VERSION ""

NS_ :

BS_:

BU_: DSAU vHS_M SHVU_RR DPSS AMP ICC RLPSM APSM RWPC RRHV RRPSM CGW_CCU APSS ATS RLHV FPM RDC PSM ASAU

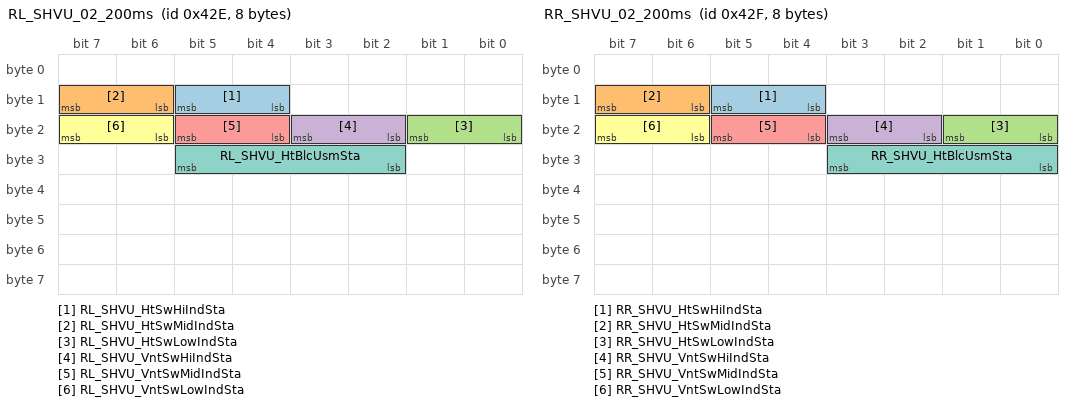
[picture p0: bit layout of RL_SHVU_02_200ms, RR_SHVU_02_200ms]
BO_ 1070 RL_SHVU_02_200ms: 8 SHVU_RR
 SG_ RL_SHVU_HtSwHiIndSta : 12|2@1+ (1,0) [0|0] ""  ATS,CGW_CCU
 SG_ RL_SHVU_HtSwMidIndSta : 14|2@1+ (1,0) [0|0] ""  ATS,CGW_CCU
 SG_ RL_SHVU_HtSwLowIndSta : 16|2@1+ (1,0) [0|0] ""  ATS,CGW_CCU
 SG_ RL_SHVU_VntSwHiIndSta : 18|2@1+ (1,0) [0|0] ""  ATS,CGW_CCU
 SG_ RL_SHVU_VntSwMidIndSta : 20|2@1+ (1,0) [0|0] ""  ATS,CGW_CCU
 SG_ RL_SHVU_VntSwLowIndSta : 22|2@1+ (1,0) [0|0] ""  ATS,CGW_CCU
 SG_ RL_SHVU_HtBlcUsmSta : 26|4@1+ (1,0) [0|0] ""  ATS,CGW_CCU

BO_ 1071 RR_SHVU_02_200ms: 8 SHVU_RR
 SG_ RR_SHVU_HtSwHiIndSta : 12|2@1+ (1,0) [0|0] ""  ATS,CGW_CCU
 SG_ RR_SHVU_HtSwMidIndSta : 14|2@1+ (1,0) [0|0] ""  ATS,CGW_CCU
 SG_ RR_SHVU_HtSwLowIndSta : 16|2@1+ (1,0) [0|0] ""  ATS,CGW_CCU
 SG_ RR_SHVU_VntSwHiIndSta : 18|2@1+ (1,0) [0|0] ""  ATS,CGW_CCU
 SG_ RR_SHVU_VntSwMidIndSta : 20|2@1+ (1,0) [0|0] ""  ATS,CGW_CCU
 SG_ RR_SHVU_VntSwLowIndSta : 22|2@1+ (1,0) [0|0] ""  ATS,CGW_CCU
 SG_ RR_SHVU_HtBlcUsmSta : 24|4@1+ (1,0) [0|0] ""  ATS,CGW_CCU

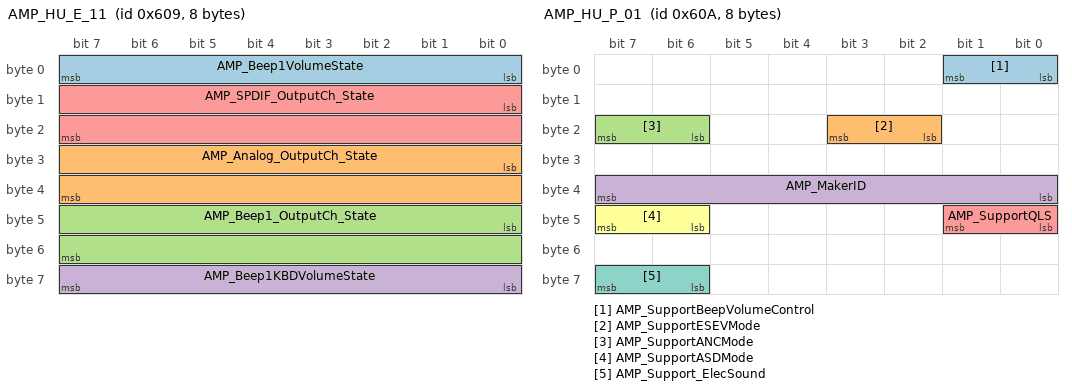
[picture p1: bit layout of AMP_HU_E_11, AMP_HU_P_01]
BO_ 1545 AMP_HU_E_11: 8 AMP
 SG_ AMP_Beep1VolumeState : 0|8@1+ (1,0) [0|0] ""  CGW_CCU
 SG_ AMP_Analog_OutputCh_State : 24|16@1+ (1,0) [0|0] ""  CGW_CCU
 SG_ AMP_Beep1_OutputCh_State : 40|16@1+ (1,0) [0|0] ""  CGW_CCU
 SG_ AMP_Beep1KBDVolumeState : 56|8@1+ (1,0) [0|0] ""  CGW_CCU
 SG_ AMP_SPDIF_OutputCh_State : 8|16@1+ (1,0) [0|0] ""  CGW_CCU

BO_ 1546 AMP_HU_P_01: 8 AMP
 SG_ AMP_SupportBeepVolumeControl : 0|2@1+ (1,0) [0|0] ""  ATS,CGW_CCU
 SG_ AMP_SupportESEVMode : 18|2@1+ (1,0) [0|0] ""  CGW_CCU
 SG_ AMP_SupportANCMode : 22|2@1+ (1,0) [0|0] ""  CGW_CCU
 SG_ AMP_MakerID : 32|8@1+ (1,0) [0|0] ""  CGW_CCU
 SG_ AMP_SupportQLS : 40|2@1+ (1,0) [0|0] ""  CGW_CCU
 SG_ AMP_SupportASDMode : 46|2@1+ (1,0) [0|0] ""  CGW_CCU
 SG_ AMP_Support_ElecSound : 62|2@1+ (1,0) [0|0] ""  CGW_CCU

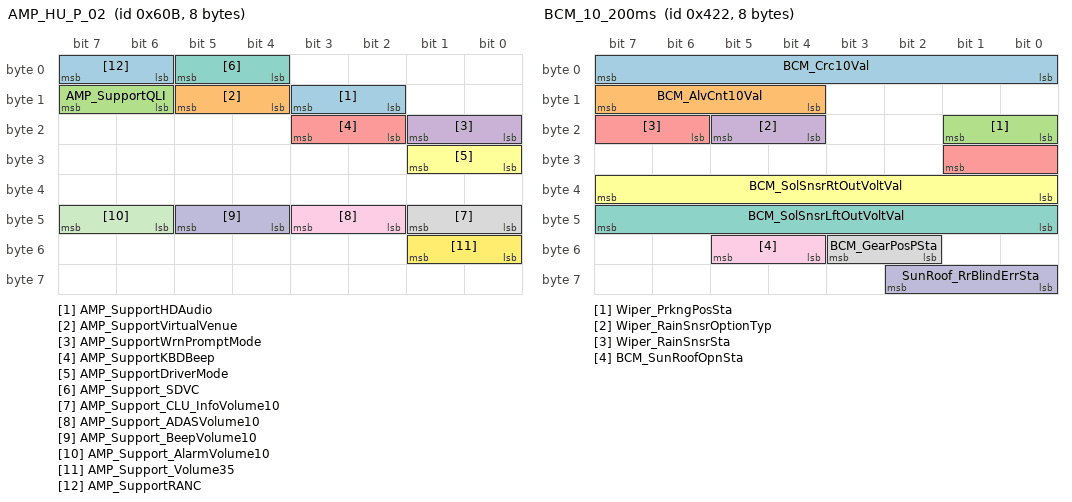
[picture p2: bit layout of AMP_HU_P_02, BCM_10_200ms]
BO_ 1547 AMP_HU_P_02: 8 AMP
 SG_ AMP_SupportHDAudio : 10|2@1+ (1,0) [0|0] ""  CGW_CCU
 SG_ AMP_SupportVirtualVenue : 12|2@1+ (1,0) [0|0] ""  CGW_CCU
 SG_ AMP_SupportQLI : 14|2@1+ (1,0) [0|0] ""  CGW_CCU
 SG_ AMP_SupportWrnPromptMode : 16|2@1+ (1,0) [0|0] ""  CGW_CCU
 SG_ AMP_SupportKBDBeep : 18|2@1+ (1,0) [0|0] ""  CGW_CCU
 SG_ AMP_SupportDriverMode : 24|2@1+ (1,0) [0|0] ""  CGW_CCU
 SG_ AMP_Support_SDVC : 4|2@1+ (1,0) [0|0] ""  CGW_CCU
 SG_ AMP_Support_CLU_InfoVolume10 : 40|2@1+ (1,0) [0|0] ""  CGW_CCU
 SG_ AMP_Support_ADASVolume10 : 42|2@1+ (1,0) [0|0] ""  CGW_CCU
 SG_ AMP_Support_BeepVolume10 : 44|2@1+ (1,0) [0|0] ""  CGW_CCU
 SG_ AMP_Support_AlarmVolume10 : 46|2@1+ (1,0) [0|0] ""  CGW_CCU
 SG_ AMP_Support_Volume35 : 48|2@1+ (1,0) [0|0] ""  CGW_CCU
 SG_ AMP_SupportRANC : 6|2@1+ (1,0) [0|0] ""  CGW_CCU

BO_ 1058 BCM_10_200ms: 8 CGW_CCU
 SG_ BCM_Crc10Val : 0|8@1+ (1,0) [0|0] ""  Vector__XXX
 SG_ BCM_AlvCnt10Val : 12|4@1+ (1,0) [0|0] ""  Vector__XXX
 SG_ Wiper_PrkngPosSta : 16|2@1+ (1,0) [0|0] ""  Vector__XXX
 SG_ Wiper_RainSnsrOptionTyp : 20|2@1+ (1,0) [0|0] ""  Vector__XXX
 SG_ Wiper_RainSnsrSta : 22|4@1+ (1,0) [0|0] ""  Vector__XXX
 SG_ BCM_SolSnsrRtOutVoltVal : 32|8@1+ (4.72441,0) [0|0] ""  Vector__XXX
 SG_ BCM_SolSnsrLftOutVoltVal : 40|8@1+ (4.72441,0) [0|0] ""  Vector__XXX
 SG_ BCM_GearPosPSta : 50|2@1+ (1,0) [0|0] ""  RLPSM,ATS
 SG_ BCM_SunRoofOpnSta : 52|2@1+ (1,0) [0|0] ""  AMP
 SG_ SunRoof_RrBlindErrSta : 56|3@1+ (1,0) [0|0] ""  Vector__XXX

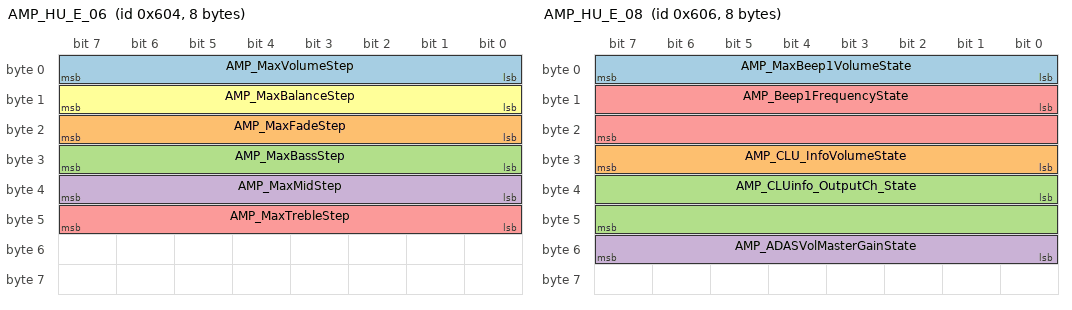
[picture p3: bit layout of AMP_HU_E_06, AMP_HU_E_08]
BO_ 1540 AMP_HU_E_06: 8 AMP
 SG_ AMP_MaxVolumeStep : 0|8@1+ (1,0) [0|0] ""  CGW_CCU
 SG_ AMP_MaxFadeStep : 16|8@1+ (1,0) [0|0] ""  CGW_CCU
 SG_ AMP_MaxBassStep : 24|8@1+ (1,0) [0|0] ""  CGW_CCU
 SG_ AMP_MaxMidStep : 32|8@1+ (1,0) [0|0] ""  CGW_CCU
 SG_ AMP_MaxTrebleStep : 40|8@1+ (1,0) [0|0] ""  CGW_CCU
 SG_ AMP_MaxBalanceStep : 8|8@1+ (1,0) [0|0] ""  CGW_CCU

BO_ 1542 AMP_HU_E_08: 8 AMP
 SG_ AMP_MaxBeep1VolumeState : 0|8@1+ (1,0) [0|0] ""  CGW_CCU
 SG_ AMP_CLU_InfoVolumeState : 24|8@1+ (1,0) [0|0] ""  CGW_CCU
 SG_ AMP_CLUinfo_OutputCh_State : 32|16@1+ (1,0) [0|0] ""  CGW_CCU
 SG_ AMP_ADASVolMasterGainState : 48|8@1+ (1,0) [0|0] ""  CGW_CCU
 SG_ AMP_Beep1FrequencyState : 8|16@1+ (1,0) [0|0] "Hz"  CGW_CCU

BO_ 1543 AMP_HU_E_09: 8 AMP
 SG_ AMP_WalkieTalkieVolumeState : 24|8@1+ (1,0) [0|0] ""  CGW_CCU
 SG_ AMP_WalkieTalkie_OutputCh_State : 8|16@1+ (1,0) [0|0] ""  CGW_CCU

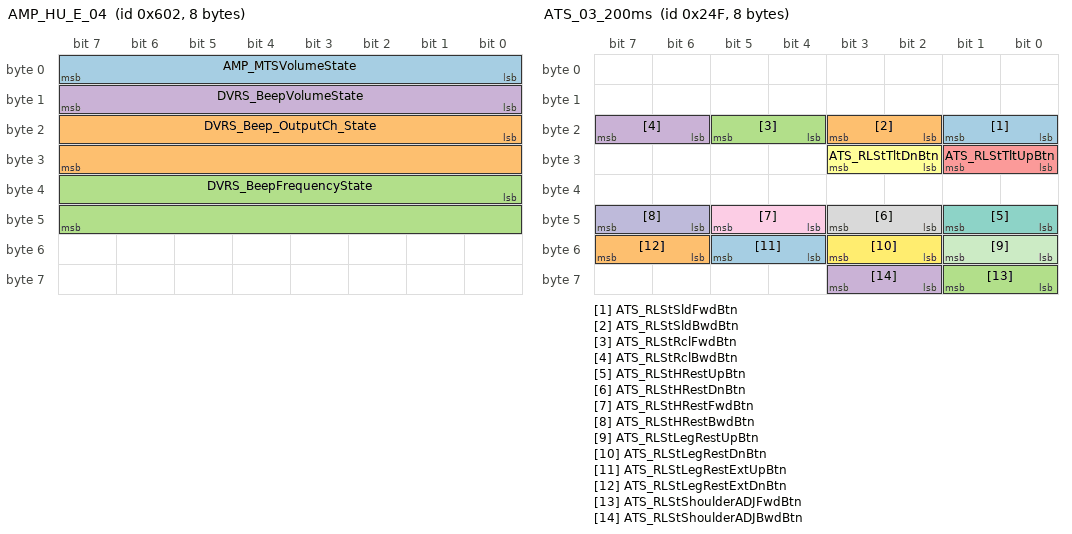
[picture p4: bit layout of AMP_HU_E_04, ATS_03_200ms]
BO_ 1538 AMP_HU_E_04: 8 AMP
 SG_ AMP_MTSVolumeState : 0|8@1+ (1,0) [0|0] ""  CGW_CCU
 SG_ DVRS_Beep_OutputCh_State : 16|16@1+ (1,0) [0|0] ""  CGW_CCU
 SG_ DVRS_BeepFrequencyState : 32|16@1+ (1,0) [0|0] "Hz"  CGW_CCU
 SG_ DVRS_BeepVolumeState : 8|8@1+ (1,0) [0|0] ""  CGW_CCU

BO_ 591 ATS_03_200ms: 8 ATS
 SG_ ATS_RLStSldFwdBtn : 16|2@1+ (1,0) [0|0] ""  RLPSM
 SG_ ATS_RLStSldBwdBtn : 18|2@1+ (1,0) [0|0] ""  RLPSM
 SG_ ATS_RLStRclFwdBtn : 20|2@1+ (1,0) [0|0] ""  RLPSM
 SG_ ATS_RLStRclBwdBtn : 22|2@1+ (1,0) [0|0] ""  RLPSM
 SG_ ATS_RLStTltUpBtn : 24|2@1+ (1,0) [0|0] ""  RLPSM
 SG_ ATS_RLStTltDnBtn : 26|2@1+ (1,0) [0|0] ""  RLPSM
 SG_ ATS_RLStHRestUpBtn : 40|2@1+ (1,0) [0|0] ""  RLPSM
 SG_ ATS_RLStHRestDnBtn : 42|2@1+ (1,0) [0|0] ""  RLPSM
 SG_ ATS_RLStHRestFwdBtn : 44|2@1+ (1,0) [0|0] ""  RLPSM
 SG_ ATS_RLStHRestBwdBtn : 46|2@1+ (1,0) [0|0] ""  RLPSM
 SG_ ATS_RLStLegRestUpBtn : 48|2@1+ (1,0) [0|0] ""  RLPSM
 SG_ ATS_RLStLegRestDnBtn : 50|2@1+ (1,0) [0|0] ""  RLPSM
 SG_ ATS_RLStLegRestExtUpBtn : 52|2@1+ (1,0) [0|0] ""  RLPSM
 SG_ ATS_RLStLegRestExtDnBtn : 54|2@1+ (1,0) [0|0] ""  RLPSM
 SG_ ATS_RLStShoulderADJFwdBtn : 56|2@1+ (1,0) [0|0] ""  RLPSM,RRPSM
 SG_ ATS_RLStShoulderADJBwdBtn : 58|2@1+ (1,0) [0|0] ""  RLPSM,RRPSM

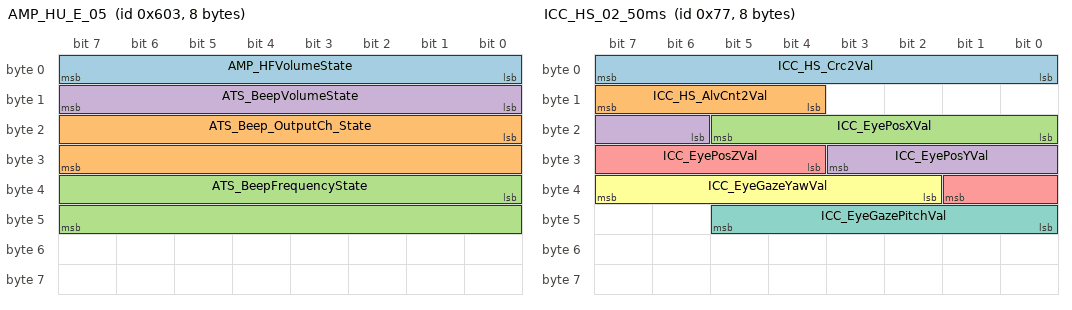
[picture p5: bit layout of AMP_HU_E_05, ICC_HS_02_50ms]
BO_ 1539 AMP_HU_E_05: 8 AMP
 SG_ AMP_HFVolumeState : 0|8@1+ (1,0) [0|0] ""  CGW_CCU
 SG_ ATS_Beep_OutputCh_State : 16|16@1+ (1,0) [0|0] ""  CGW_CCU
 SG_ ATS_BeepFrequencyState : 32|16@1+ (1,0) [0|0] "Hz"  CGW_CCU
 SG_ ATS_BeepVolumeState : 8|8@1+ (1,0) [0|0] ""  CGW_CCU

BO_ 119 ICC_HS_02_50ms: 8 ICC
 SG_ ICC_HS_Crc2Val : 0|8@1+ (1,0) [0|0] ""  CGW_CCU
 SG_ ICC_HS_AlvCnt2Val : 12|4@1+ (1,0) [0|0] ""  CGW_CCU
 SG_ ICC_EyePosXVal : 16|6@1+ (2,-60) [0|0] ""  CGW_CCU
 SG_ ICC_EyePosYVal : 22|6@1+ (2,-60) [0|0] ""  CGW_CCU
 SG_ ICC_EyePosZVal : 28|6@1+ (2,-60) [0|0] ""  CGW_CCU
 SG_ ICC_EyeGazeYawVal : 34|6@1+ (2,-60) [0|0] ""  CGW_CCU
 SG_ ICC_EyeGazePitchVal : 40|6@1+ (2,-60) [0|0] ""  CGW_CCU

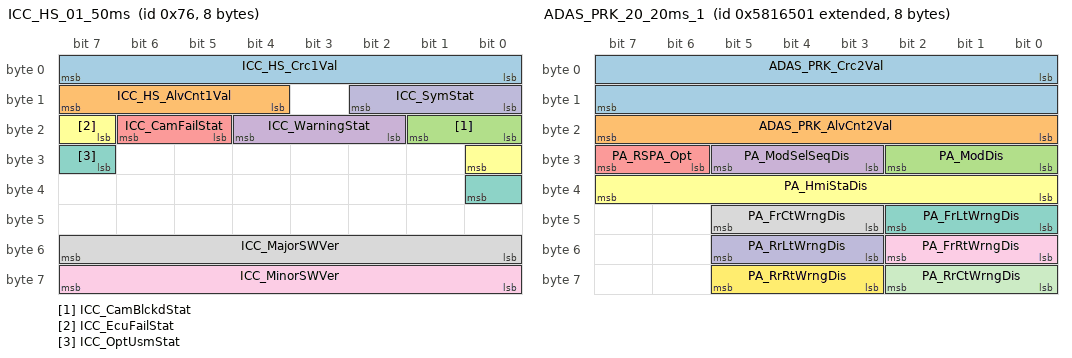
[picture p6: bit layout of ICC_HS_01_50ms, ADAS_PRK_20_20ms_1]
BO_ 118 ICC_HS_01_50ms: 8 ICC
 SG_ ICC_HS_Crc1Val : 0|8@1+ (1,0) [0|0] ""  CGW_CCU
 SG_ ICC_HS_AlvCnt1Val : 12|4@1+ (1,0) [0|0] ""  CGW_CCU
 SG_ ICC_CamBlckdStat : 16|2@1+ (1,0) [0|0] ""  CGW_CCU
 SG_ ICC_WarningStat : 18|3@1+ (1,0) [0|0] ""  CGW_CCU
 SG_ ICC_CamFailStat : 21|2@1+ (1,0) [0|0] ""  CGW_CCU
 SG_ ICC_EcuFailStat : 23|2@1+ (1,0) [0|0] ""  CGW_CCU
 SG_ ICC_OptUsmStat : 31|2@1+ (1,0) [0|0] ""  CGW_CCU
 SG_ ICC_MajorSWVer : 48|8@1+ (1,0) [0|0] ""  CGW_CCU
 SG_ ICC_MinorSWVer : 56|8@1+ (1,0) [0|0] ""  CGW_CCU
 SG_ ICC_SymStat : 8|3@1+ (1,0) [0|0] ""  CGW_CCU

BO_ 2239849729 ADAS_PRK_20_20ms_1: 8 CGW_CCU
 SG_ ADAS_PRK_Crc2Val : 0|16@1+ (1,0) [0|0] ""  Vector__XXX
 SG_ ADAS_PRK_AlvCnt2Val : 16|8@1+ (1,0) [0|0] ""  Vector__XXX
 SG_ PA_ModDis : 24|3@1+ (1,0) [0|0] ""  Vector__XXX
 SG_ PA_ModSelSeqDis : 27|3@1+ (1,0) [0|0] ""  Vector__XXX
 SG_ PA_RSPA_Opt : 30|2@1+ (1,0) [0|0] ""  Vector__XXX
 SG_ PA_HmiStaDis : 32|8@1+ (1,0) [0|0] ""  Vector__XXX
 SG_ PA_FrLtWrngDis : 40|3@1+ (1,0) [0|0] ""  Vector__XXX
 SG_ PA_FrCtWrngDis : 43|3@1+ (1,0) [0|0] ""  Vector__XXX
 SG_ PA_FrRtWrngDis : 48|3@1+ (1,0) [0|0] ""  Vector__XXX
 SG_ PA_RrLtWrngDis : 51|3@1+ (1,0) [0|0] ""  Vector__XXX
 SG_ PA_RrCtWrngDis : 56|3@1+ (1,0) [0|0] ""  Vector__XXX
 SG_ PA_RrRtWrngDis : 59|3@1+ (1,0) [0|0] ""  Vector__XXX

BO_ 2239849730 ADAS_PRK_20_20ms_2: 8 CGW_CCU
 SG_ PA_BpAlrmReq : 0|5@1+ (1,0) [0|0] ""  Vector__XXX
 SG_ PA_FrWrngAlrmReq : 10|2@1+ (1,0) [0|0] ""  Vector__XXX
 SG_ PA_RrWrngAlrmReq : 12|2@1+ (1,0) [0|0] ""  Vector__XXX
 SG_ PA_FrLtWrngAlrmReq : 14|2@1+ (1,0) [0|0] ""  AMP
 SG_ PA_FrCtWrngAlrmReq : 16|2@1+ (1,0) [0|0] ""  AMP
 SG_ PA_FrRtWrngAlrmReq : 18|2@1+ (1,0) [0|0] ""  AMP
 SG_ PA_RrLtWrngAlrmReq : 20|2@1+ (1,0) [0|0] ""  AMP
 SG_ PA_RrCtWrngAlrmReq : 22|2@1+ (1,0) [0|0] ""  AMP
 SG_ PA_RrRtWrngAlrmReq : 24|2@1+ (1,0) [0|0] ""  AMP
 SG_ PA_Sta : 26|4@1+ (1,0) [0|0] ""  Vector__XXX
 SG_ PA_TestModSta : 30|2@1+ (1,0) [0|0] ""  Vector__XXX
 SG_ PA_StrAnglReq : 32|16@1- (0.1,0) [0|0] ""  Vector__XXX
 SG_ ADAS_PRK_OptInfo : 48|4@1+ (1,0) [0|0] ""  Vector__XXX
 SG_ PA_AlrmVlmLvlReq : 5|3@1+ (1,0) [0|0] ""  Vector__XXX
 SG_ PA_LtFrWrngDis : 56|3@1+ (1,0) [0|0] ""  Vector__XXX
 SG_ PA_RtFrWrngDis : 59|3@1+ (1,0) [0|0] ""  Vector__XXX
 SG_ PA_SdWrngAlrmReq : 62|2@1+ (1,0) [0|0] ""  AMP
 SG_ PA_AlrmVlmDeratingReq : 8|2@1+ (1,0) [0|0] ""  Vector__XXX

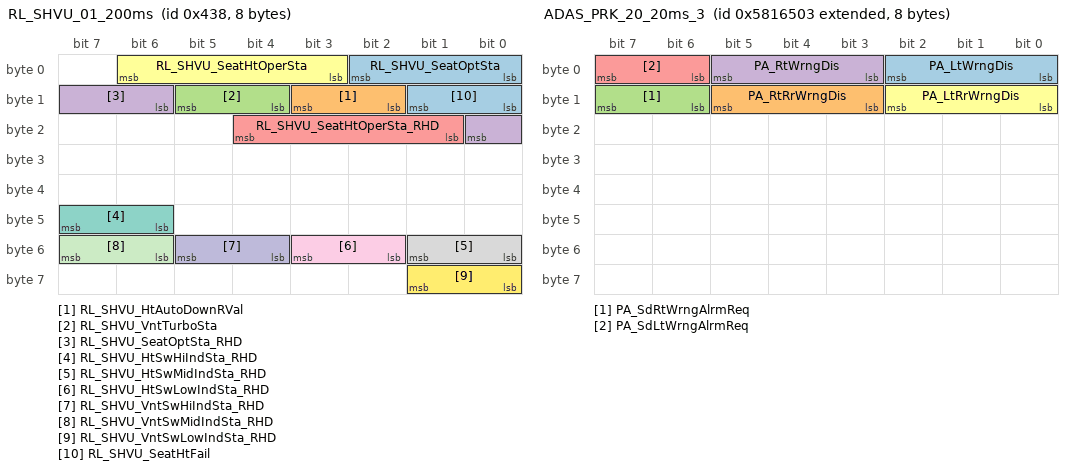
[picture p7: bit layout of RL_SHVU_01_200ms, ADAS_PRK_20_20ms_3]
BO_ 1080 RL_SHVU_01_200ms: 8 SHVU_RR
 SG_ RL_SHVU_SeatOptSta : 0|3@1+ (1,0) [0|0] ""  ATS,CGW_CCU
 SG_ RL_SHVU_HtAutoDownRVal : 10|2@1+ (1,0) [0|0] ""  ATS,ATS,CGW_CCU,CGW_CCU
 SG_ RL_SHVU_VntTurboSta : 12|2@1+ (1,0) [0|0] ""  ATS,ATS,CGW_CCU,CGW_CCU
 SG_ RL_SHVU_SeatOptSta_RHD : 14|3@1+ (1,0) [0|0] ""  ATS,CGW_CCU
 SG_ RL_SHVU_SeatHtOperSta_RHD : 17|4@1+ (1,0) [0|0] ""  ATS,CGW_CCU
 SG_ RL_SHVU_SeatHtOperSta : 3|4@1+ (1,0) [0|0] ""  ATS,CGW_CCU
 SG_ RL_SHVU_HtSwHiIndSta_RHD : 46|2@1+ (1,0) [0|0] ""  ATS,CGW_CCU
 SG_ RL_SHVU_HtSwMidIndSta_RHD : 48|2@1+ (1,0) [0|0] ""  ATS,CGW_CCU
 SG_ RL_SHVU_HtSwLowIndSta_RHD : 50|2@1+ (1,0) [0|0] ""  ATS,CGW_CCU
 SG_ RL_SHVU_VntSwHiIndSta_RHD : 52|2@1+ (1,0) [0|0] ""  ATS,CGW_CCU
 SG_ RL_SHVU_VntSwMidIndSta_RHD : 54|2@1+ (1,0) [0|0] ""  ATS,CGW_CCU
 SG_ RL_SHVU_VntSwLowIndSta_RHD : 56|2@1+ (1,0) [0|0] ""  ATS,CGW_CCU
 SG_ RL_SHVU_SeatHtFail : 8|2@1+ (1,0) [0|0] ""  ATS,CGW_CCU,CGW_CCU

BO_ 2239849731 ADAS_PRK_20_20ms_3: 8 CGW_CCU
 SG_ PA_LtWrngDis : 0|3@1+ (1,0) [0|0] ""  Vector__XXX
 SG_ PA_RtRrWrngDis : 11|3@1+ (1,0) [0|0] ""  Vector__XXX
 SG_ PA_SdRtWrngAlrmReq : 14|2@1+ (1,0) [0|0] ""  AMP
 SG_ PA_RtWrngDis : 3|3@1+ (1,0) [0|0] ""  Vector__XXX
 SG_ PA_SdLtWrngAlrmReq : 6|2@1+ (1,0) [0|0] ""  AMP
 SG_ PA_LtRrWrngDis : 8|3@1+ (1,0) [0|0] ""  Vector__XXX

BO_ 2315420161 HU_FPM_E_02_1: 8 CGW_CCU
 SG_ AVN_Encrypted_Result2 : 0|64@1+ (1,0) [0|0] ""  FPM

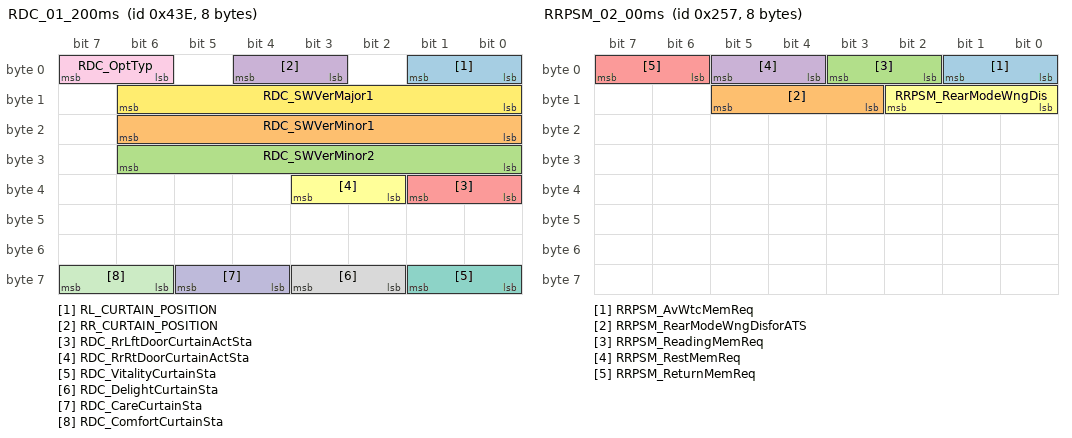
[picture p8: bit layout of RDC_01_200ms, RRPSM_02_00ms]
BO_ 1086 RDC_01_200ms: 8 RDC
 SG_ RL_CURTAIN_POSITION : 0|2@1+ (1,0) [0|0] ""  ATS,CGW_CCU
 SG_ RDC_SWVerMinor1 : 16|7@1+ (1,0) [0|0] ""  CGW_CCU
 SG_ RDC_SWVerMinor2 : 24|7@1+ (1,0) [0|0] ""  CGW_CCU
 SG_ RR_CURTAIN_POSITION : 3|2@1+ (1,0) [0|0] ""  ATS,CGW_CCU
 SG_ RDC_RrLftDoorCurtainActSta : 32|2@1+ (1,0) [0|0] ""  ATS
 SG_ RDC_RrRtDoorCurtainActSta : 34|2@1+ (1,0) [0|0] ""  ATS
 SG_ RDC_VitalityCurtainSta : 56|2@1+ (1,0) [0|0] ""  CGW_CCU
 SG_ RDC_DelightCurtainSta : 58|2@1+ (1,0) [0|0] ""  CGW_CCU
 SG_ RDC_OptTyp : 6|2@1+ (1,0) [0|0] ""  ATS,CGW_CCU
 SG_ RDC_CareCurtainSta : 60|2@1+ (1,0) [0|0] ""  CGW_CCU
 SG_ RDC_ComfortCurtainSta : 62|2@1+ (1,0) [0|0] ""  CGW_CCU
 SG_ RDC_SWVerMajor1 : 8|7@1+ (1,0) [0|0] ""  CGW_CCU

BO_ 599 RRPSM_02_00ms: 8 RRPSM
 SG_ RRPSM_AvWtcMemReq : 0|2@1+ (1,0) [0|0] ""  ATS
 SG_ RRPSM_RearModeWngDisforATS : 11|3@1+ (1,0) [0|0] ""  ATS
 SG_ RRPSM_ReadingMemReq : 2|2@1+ (1,0) [0|0] ""  ATS
 SG_ RRPSM_RestMemReq : 4|2@1+ (1,0) [0|0] ""  ATS
 SG_ RRPSM_ReturnMemReq : 6|2@1+ (1,0) [0|0] ""  ATS
 SG_ RRPSM_RearModeWngDis : 8|3@1+ (1,0) [0|0] ""  CGW_CCU

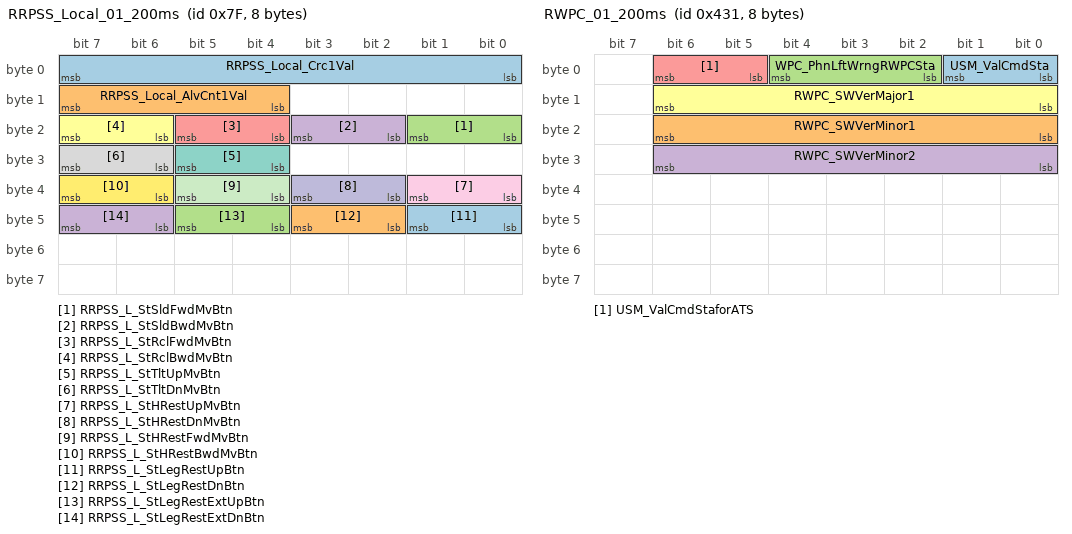
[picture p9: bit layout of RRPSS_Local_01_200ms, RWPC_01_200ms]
BO_ 127 RRPSS_Local_01_200ms: 8 RLPSM
 SG_ RRPSS_Local_Crc1Val : 0|8@1+ (1,0) [0|0] ""  CGW_CCU
 SG_ RRPSS_Local_AlvCnt1Val : 12|4@1+ (1,0) [0|0] ""  CGW_CCU
 SG_ RRPSS_L_StSldFwdMvBtn : 16|2@1+ (1,0) [0|0] ""  ATS,CGW_CCU
 SG_ RRPSS_L_StSldBwdMvBtn : 18|2@1+ (1,0) [0|0] ""  ATS,CGW_CCU
 SG_ RRPSS_L_StRclFwdMvBtn : 20|2@1+ (1,0) [0|0] ""  ATS,CGW_CCU
 SG_ RRPSS_L_StRclBwdMvBtn : 22|2@1+ (1,0) [0|0] ""  ATS,CGW_CCU
 SG_ RRPSS_L_StTltUpMvBtn : 28|2@1+ (1,0) [0|0] ""  ATS,CGW_CCU
 SG_ RRPSS_L_StTltDnMvBtn : 30|2@1+ (1,0) [0|0] ""  ATS,CGW_CCU
 SG_ RRPSS_L_StHRestUpMvBtn : 32|2@1+ (1,0) [0|0] ""  ATS,CGW_CCU
 SG_ RRPSS_L_StHRestDnMvBtn : 34|2@1+ (1,0) [0|0] ""  ATS,CGW_CCU
 SG_ RRPSS_L_StHRestFwdMvBtn : 36|2@1+ (1,0) [0|0] ""  ATS,CGW_CCU
 SG_ RRPSS_L_StHRestBwdMvBtn : 38|2@1+ (1,0) [0|0] ""  ATS,CGW_CCU
 SG_ RRPSS_L_StLegRestUpBtn : 40|2@1+ (1,0) [0|0] ""  ATS,CGW_CCU
 SG_ RRPSS_L_StLegRestDnBtn : 42|2@1+ (1,0) [0|0] ""  ATS,CGW_CCU
 SG_ RRPSS_L_StLegRestExtUpBtn : 44|2@1+ (1,0) [0|0] ""  ATS,CGW_CCU
 SG_ RRPSS_L_StLegRestExtDnBtn : 46|2@1+ (1,0) [0|0] ""  ATS,CGW_CCU

BO_ 1073 RWPC_01_200ms: 8 RWPC
 SG_ USM_ValCmdSta : 0|2@1+ (1,0) [0|0] ""  ATS,CGW_CCU
 SG_ RWPC_SWVerMinor1 : 16|7@1+ (1,0) [0|0] ""  CGW_CCU
 SG_ WPC_PhnLftWrngRWPCSta : 2|3@1+ (1,0) [0|0] ""  ATS,CGW_CCU
 SG_ RWPC_SWVerMinor2 : 24|7@1+ (1,0) [0|0] ""  CGW_CCU
 SG_ USM_ValCmdStaforATS : 5|2@1+ (1,0) [0|0] ""  ATS
 SG_ RWPC_SWVerMajor1 : 8|7@1+ (1,0) [0|0] ""  CGW_CCU

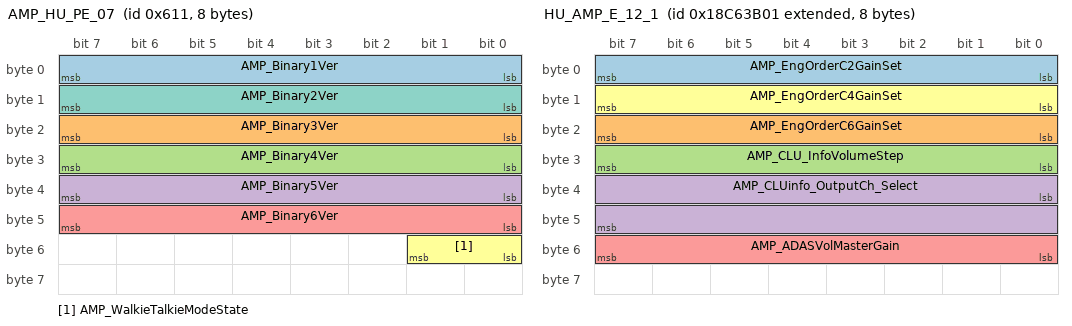
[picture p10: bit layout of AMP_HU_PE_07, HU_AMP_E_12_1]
BO_ 1553 AMP_HU_PE_07: 8 AMP
 SG_ AMP_Binary1Ver : 0|8@1+ (1,0) [0|0] ""  CGW_CCU
 SG_ AMP_Binary3Ver : 16|8@1+ (1,0) [0|0] ""  CGW_CCU
 SG_ AMP_Binary4Ver : 24|8@1+ (1,0) [0|0] ""  CGW_CCU
 SG_ AMP_Binary5Ver : 32|8@1+ (1,0) [0|0] ""  CGW_CCU
 SG_ AMP_Binary6Ver : 40|8@1+ (1,0) [0|0] ""  CGW_CCU
 SG_ AMP_WalkieTalkieModeState : 48|2@1+ (1,0) [0|0] ""  CGW_CCU
 SG_ AMP_Binary2Ver : 8|8@1+ (1,0) [0|0] ""  CGW_CCU

BO_ 2563128065 HU_AMP_E_12_1: 8 CGW_CCU
 SG_ AMP_EngOrderC2GainSet : 0|8@1+ (1,0) [0|0] ""  Vector__XXX
 SG_ AMP_EngOrderC6GainSet : 16|8@1+ (1,0) [0|0] ""  Vector__XXX
 SG_ AMP_CLU_InfoVolumeStep : 24|8@1+ (1,0) [0|0] ""  AMP
 SG_ AMP_CLUinfo_OutputCh_Select : 32|16@1+ (1,0) [0|0] ""  AMP
 SG_ AMP_ADASVolMasterGain : 48|8@1+ (1,0) [0|0] ""  AMP
 SG_ AMP_EngOrderC4GainSet : 8|8@1+ (1,0) [0|0] ""  Vector__XXX

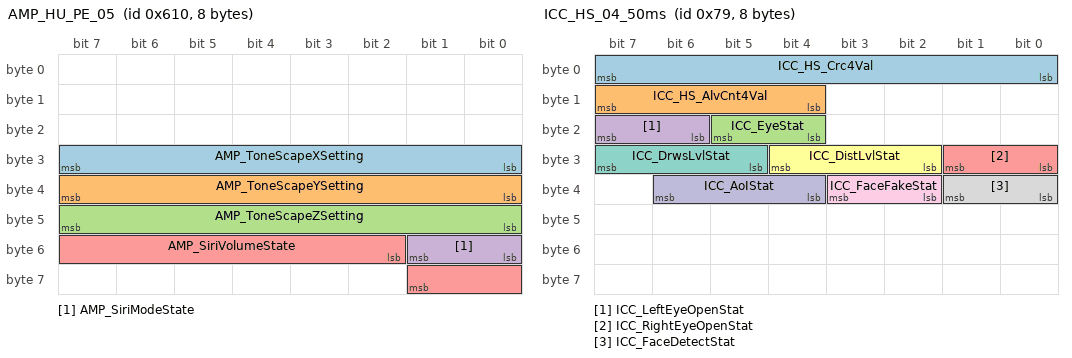
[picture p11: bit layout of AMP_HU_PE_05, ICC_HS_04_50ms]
BO_ 1552 AMP_HU_PE_05: 8 AMP
 SG_ AMP_ToneScapeXSetting : 24|8@1+ (1,0) [0|0] ""  CGW_CCU
 SG_ AMP_ToneScapeYSetting : 32|8@1+ (1,0) [0|0] ""  CGW_CCU
 SG_ AMP_ToneScapeZSetting : 40|8@1+ (1,0) [0|0] ""  CGW_CCU
 SG_ AMP_SiriModeState : 48|2@1+ (1,0) [0|0] ""  CGW_CCU
 SG_ AMP_SiriVolumeState : 50|8@1+ (1,0) [0|0] ""  CGW_CCU

BO_ 121 ICC_HS_04_50ms: 8 ICC
 SG_ ICC_HS_Crc4Val : 0|8@1+ (1,0) [0|0] ""  CGW_CCU
 SG_ ICC_HS_AlvCnt4Val : 12|4@1+ (1,0) [0|0] ""  CGW_CCU
 SG_ ICC_EyeStat : 20|2@1+ (1,0) [0|0] ""  CGW_CCU
 SG_ ICC_LeftEyeOpenStat : 22|2@1+ (1,0) [0|0] ""  CGW_CCU
 SG_ ICC_RightEyeOpenStat : 24|2@1+ (1,0) [0|0] ""  CGW_CCU
 SG_ ICC_DistLvlStat : 26|3@1+ (1,0) [0|0] ""  CGW_CCU
 SG_ ICC_DrwsLvlStat : 29|3@1+ (1,0) [0|0] ""  CGW_CCU
 SG_ ICC_FaceDetectStat : 32|2@1+ (1,0) [0|0] ""  CGW_CCU
 SG_ ICC_FaceFakeStat : 34|2@1+ (1,0) [0|0] ""  CGW_CCU
 SG_ ICC_AoIStat : 36|3@1+ (1,0) [0|0] ""  CGW_CCU

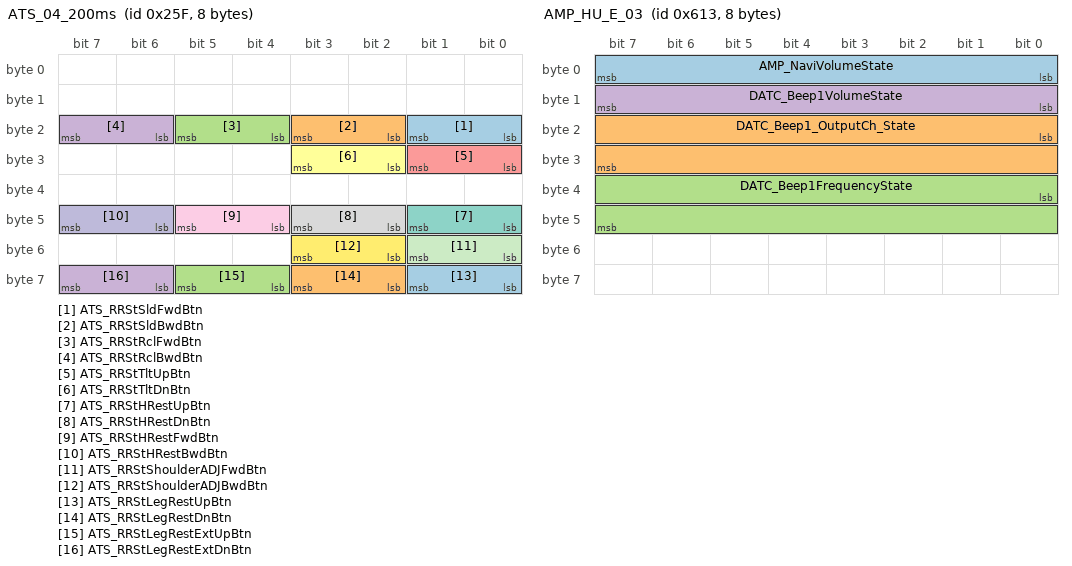
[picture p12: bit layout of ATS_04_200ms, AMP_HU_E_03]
BO_ 607 ATS_04_200ms: 8 ATS
 SG_ ATS_RRStSldFwdBtn : 16|2@1+ (1,0) [0|0] ""  RRPSM
 SG_ ATS_RRStSldBwdBtn : 18|2@1+ (1,0) [0|0] ""  RRPSM
 SG_ ATS_RRStRclFwdBtn : 20|2@1+ (1,0) [0|0] ""  RRPSM
 SG_ ATS_RRStRclBwdBtn : 22|2@1+ (1,0) [0|0] ""  RRPSM
 SG_ ATS_RRStTltUpBtn : 24|2@1+ (1,0) [0|0] ""  RRPSM
 SG_ ATS_RRStTltDnBtn : 26|2@1+ (1,0) [0|0] ""  RRPSM
 SG_ ATS_RRStHRestUpBtn : 40|2@1+ (1,0) [0|0] ""  RRPSM
 SG_ ATS_RRStHRestDnBtn : 42|2@1+ (1,0) [0|0] ""  RRPSM
 SG_ ATS_RRStHRestFwdBtn : 44|2@1+ (1,0) [0|0] ""  RRPSM
 SG_ ATS_RRStHRestBwdBtn : 46|2@1+ (1,0) [0|0] ""  RRPSM
 SG_ ATS_RRStShoulderADJFwdBtn : 48|2@1+ (1,0) [0|0] ""  RLPSM,RRPSM
 SG_ ATS_RRStShoulderADJBwdBtn : 50|2@1+ (1,0) [0|0] ""  RLPSM,RRPSM
 SG_ ATS_RRStLegRestUpBtn : 56|2@1+ (1,0) [0|0] ""  RRPSM
 SG_ ATS_RRStLegRestDnBtn : 58|2@1+ (1,0) [0|0] ""  RRPSM
 SG_ ATS_RRStLegRestExtUpBtn : 60|2@1+ (1,0) [0|0] ""  RRPSM
 SG_ ATS_RRStLegRestExtDnBtn : 62|2@1+ (1,0) [0|0] ""  RRPSM

BO_ 1555 AMP_HU_E_03: 8 AMP
 SG_ AMP_NaviVolumeState : 0|8@1+ (1,0) [0|0] ""  CGW_CCU
 SG_ DATC_Beep1_OutputCh_State : 16|16@1+ (1,0) [0|0] ""  CGW_CCU
 SG_ DATC_Beep1FrequencyState : 32|16@1+ (1,0) [0|0] "Hz"  CGW_CCU
 SG_ DATC_Beep1VolumeState : 8|8@1+ (1,0) [0|0] ""  CGW_CCU

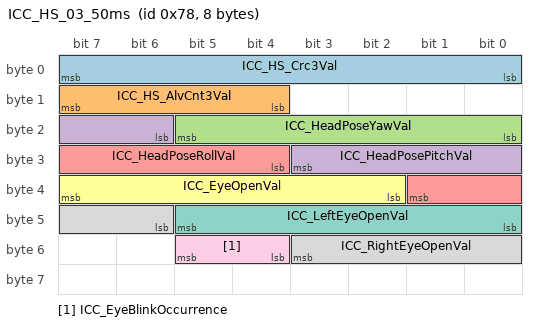
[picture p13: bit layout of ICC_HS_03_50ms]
BO_ 120 ICC_HS_03_50ms: 8 ICC
 SG_ ICC_HS_Crc3Val : 0|8@1+ (1,0) [0|0] ""  CGW_CCU
 SG_ ICC_HS_AlvCnt3Val : 12|4@1+ (1,0) [0|0] ""  CGW_CCU
 SG_ ICC_HeadPoseYawVal : 16|6@1+ (2,-60) [0|0] ""  CGW_CCU
 SG_ ICC_HeadPosePitchVal : 22|6@1+ (2,-60) [0|0] ""  CGW_CCU
 SG_ ICC_HeadPoseRollVal : 28|6@1+ (2,-60) [0|0] ""  CGW_CCU
 SG_ ICC_EyeOpenVal : 34|6@1+ (2,0) [0|0] ""  CGW_CCU
 SG_ ICC_LeftEyeOpenVal : 40|6@1+ (2,0) [0|0] ""  CGW_CCU
 SG_ ICC_RightEyeOpenVal : 46|6@1+ (2,0) [0|0] ""  CGW_CCU
 SG_ ICC_EyeBlinkOccurrence : 52|2@1+ (1,0) [0|0] ""  CGW_CCU

BO_TX_BU_ 1070 : SHVU_RR,RLHV,RLPSM;
BO_TX_BU_ 1071 : SHVU_RR,RRPSM,RRHV;
BO_TX_BU_ 1080 : SHVU_RR,RLHV,RLPSM;
CM_ BO_ 2239849729 "[P] Periodic";
CM_ SG_ 2239849729 ADAS_PRK_Crc2Val "ADAS_PRK_CyclicRedundancyCheck2Value";
CM_ SG_ 2239849729 ADAS_PRK_AlvCnt2Val "ADAS_PRK_AliveCounter2Value";
CM_ SG_ 2239849729 PA_ModDis "PA_ModeDisplay";
CM_ SG_ 2239849729 PA_ModSelSeqDis "PA_ModeSelectionSequenceDisplay";
CM_ SG_ 2239849729 PA_HmiStaDis "PA_HmiStateDisplay";
CM_ SG_ 2239849729 PA_FrLtWrngDis "PA_FrontLeftWarningDisplay";
CM_ SG_ 2239849729 PA_FrCtWrngDis "PA_FrontCenterWarningDisplay";
CM_ SG_ 2239849729 PA_FrRtWrngDis "PA_FrontRightWarningDisplay";
CM_ SG_ 2239849729 PA_RrLtWrngDis "PA_RearLeftWarningDisplay";
CM_ SG_ 2239849729 PA_RrCtWrngDis "PA_RearCenterWarningDisplay";
CM_ SG_ 2239849729 PA_RrRtWrngDis "PA_RearRightWarningDisplay";
CM_ BO_ 2239849730 "[P] Periodic";
CM_ SG_ 2239849730 PA_BpAlrmReq "PA_BeepAlarmRequest";
CM_ SG_ 2239849730 PA_FrWrngAlrmReq "PA_FrontWarningAlarmRequest";
CM_ SG_ 2239849730 PA_RrWrngAlrmReq "PA_RearWarningAlarmRequest";
CM_ SG_ 2239849730 PA_FrLtWrngAlrmReq "PA_FrontLeftWarningAlarmRequest";
CM_ SG_ 2239849730 PA_FrCtWrngAlrmReq "PA_FrontCenterWarningAlarmRequest";
CM_ SG_ 2239849730 PA_FrRtWrngAlrmReq "PA_FrontRightWarningAlarmRequest";
CM_ SG_ 2239849730 PA_RrLtWrngAlrmReq "PA_RearLeftWarningAlarmRequest";
CM_ SG_ 2239849730 PA_RrCtWrngAlrmReq "PA_RearCenterWarningAlarmRequest";
CM_ SG_ 2239849730 PA_RrRtWrngAlrmReq "PA_RearRightWarningAlarmRequest";
CM_ SG_ 2239849730 PA_Sta "PA_Status";
CM_ SG_ 2239849730 PA_TestModSta "PA_TestModeStatus";
CM_ SG_ 2239849730 PA_StrAnglReq "PA_SteeringAngleRequest";
CM_ SG_ 2239849730 ADAS_PRK_OptInfo "Information of Resolution/PCLK to H/U";
CM_ SG_ 2239849730 PA_AlrmVlmLvlReq "PA_AlarmVolumeLevelRequest";
CM_ SG_ 2239849730 PA_LtFrWrngDis "PA_LeftFrontWarningDisplay";
CM_ SG_ 2239849730 PA_RtFrWrngDis "PA_RightFrontWarningDisplay";
CM_ SG_ 2239849730 PA_SdWrngAlrmReq "PA_SideWarningAlarmRequest";
CM_ SG_ 2239849730 PA_AlrmVlmDeratingReq "PA_AlarmVolumeDeratingRequest";
CM_ BO_ 2239849731 "[P] Periodic";
CM_ SG_ 2239849731 PA_LtWrngDis "PA_LeftWarningDisplay";
CM_ SG_ 2239849731 PA_RtRrWrngDis "PA_RightRearWarningDisplay";
CM_ SG_ 2239849731 PA_SdRtWrngAlrmReq "PA_SideRightWarningAlarmRequest";
CM_ SG_ 2239849731 PA_RtWrngDis "PA_RightWarningDisplay";
CM_ SG_ 2239849731 PA_SdLtWrngAlrmReq "PA_SideLeftWarningAlarmRequest";
CM_ SG_ 2239849731 PA_LtRrWrngDis "PA_LeftRearWarningDisplay";
CM_ BO_ 1555 "[EC] On Event and On Change";
CM_ SG_ 1555 AMP_NaviVolumeState "Information for Current Navi Prompt Volume Setting
-range : 0 ~ max
-max : value of AMP_MaxNaviVolumeState(0x082)
-Feedback from AMP_NaviVolumeStep(0x00C)@H_U";
CM_ BO_ 1538 "[EC] On Event and On Change";
CM_ SG_ 1538 AMP_MTSVolumeState "Information for Current MTS Call Volume Setting Status
For AVN 4.0 production diagnostic
-range : 0 ~ max
-max : value of AMP_MaxMTSVolumeState(0x083)
-Feedback from AMP_MTSVolumeStep(0x00D)@H_U";
CM_ BO_ 1539 "[EC] On Event and On Change";
CM_ SG_ 1539 AMP_HFVolumeState "Information for Current HF(Hands Free) Call Volume Setting Status
-range : 0 ~ max
-max : value of AMP_MaxHFVolumeState(0x084)
-Feedback from AMP_HFVolumeStep(0x00E)@H_U";
CM_ BO_ 1540 "[EC] On Event and On Change";
CM_ SG_ 1540 AMP_MaxVolumeStep "Information for Current Max Main Audio Volume Limit
Transmit 500msec after Booting Up
-AMP_MainVolumeSet(0x00F)@H_U uses this Value to define range
-AMP_MainVolumeSetting(0x183)@AMP uses this Value to define range";
CM_ SG_ 1540 AMP_MaxFadeStep "Information for Current Max Front/Rear Audio Fader Limit
Transmit 500msec after Booting Up
-AMP_FadeSet(0x00F)@H_U uses this Value to define range
-AMP_FadeSetting(0x183)@AMP uses this Value to define range";
CM_ SG_ 1540 AMP_MaxBassStep "Information for Current Max Bass Tone Control Limit
Transmit 500msec after Booting Up
-AMP_BassSet(0x00F)@H_U uses this Value to define range
-AMP_BassSetting(0x183)@AMP uses this Value to define range";
CM_ SG_ 1540 AMP_MaxMidStep "Information for Current Max Midrange Tone Control Limit
Transmit 500msec after Booting Up
-AMP_MidSet(0x00F)@H_U uses this Value to define range
-AMP_MidSetting(0x183)@H_U uses this Value to define range";
CM_ SG_ 1540 AMP_MaxTrebleStep "Information for Current Max Treble Tone Control Limit
Transmit 500msec after Booting Up
-AMP_TrebleSet(0x00F)@H_U uses this Value to define range
-AMP_TrebleSetting(0x183)@H_U uses this Value to define range";
CM_ SG_ 1540 AMP_MaxBalanceStep "Information for Current Max Left/Right Audio Balance Limit
Transmit 500msec after Booting Up
-AMP_BalanceSet(0x00F)@H_U uses this Value to define range
-AMP_BalnaceSetting(0x183)@AMP uses this Value to define range";
CM_ BO_ 1542 "[EC] On Event and On Change";
CM_ SG_ 1542 AMP_MaxBeep1VolumeState "Information for current touch beep sound max volume limit
Send 500msec after Booting up";
CM_ BO_ 1543 "[EC] On Event and On Change";
CM_ BO_ 1545 "[EC] On Event and On Change";
CM_ SG_ 1545 AMP_Beep1VolumeState "Information for Current Beep1 Sound Volume Setting Status
-range : 0 ~ max
-max : value of AMP_MaxBeep1VolumeState(0x087)
-Feedback from AMP_Beep1VolumeStep(0x070)@H_U";
CM_ BO_ 1552 "[PE] Periodic and On Event";
CM_ SG_ 1552 AMP_SiriModeState "Send Feedback Signal 'Siri Mode On/Off' from AMP to HU";
CM_ BO_ 1553 "[PE] Periodic and On Event";
CM_ SG_ 1553 AMP_Binary1Ver "Information for SW Binary1 Version of AMP";
CM_ SG_ 1553 AMP_Binary3Ver "Information for SW Binary3 Version of AMP";
CM_ SG_ 1553 AMP_Binary4Ver "Information for SW Binary4 Version of AMP";
CM_ SG_ 1553 AMP_Binary5Ver "Information for SW Binary5 Version of AMP";
CM_ SG_ 1553 AMP_Binary6Ver "Information for SW Binary6 Version of AMP";
CM_ SG_ 1553 AMP_WalkieTalkieModeState "Send Feedback Signal 'WalkieTalkie Mode On/Off' from AMP to HU";
CM_ SG_ 1553 AMP_Binary2Ver "Information for SW Binary2 Version of AMP";
CM_ BO_ 1546 "[P] Periodic";
CM_ SG_ 1546 AMP_SupportBeepVolumeControl "Information for AMPsupport configurable Beep1
send 500msec after Booting up";
CM_ SG_ 1546 AMP_SupportESEVMode "Information for AMP support ESEV(Engine Sound by Engine Vibration).";
CM_ SG_ 1546 AMP_SupportANCMode "Does AMP support ANC?";
CM_ SG_ 1546 AMP_MakerID "Information for AMP Maker
For model afrer 2014, use 0x01~0x03 only.
* Use Only 0x01~0x03 values after 2014 *";
CM_ SG_ 1546 AMP_SupportQLS "Information for amp support Quantum Logic Surround mode
Harman AMP Only";
CM_ SG_ 1546 AMP_SupportASDMode "Information for  AMP support ASD (Active Sound Design, Virtual Engine Sound)";
CM_ SG_ 1546 AMP_Support_ElecSound "inform to H/U & CLU whether amp support premium electric sound or not";
CM_ BO_ 1547 "[P] Periodic";
CM_ SG_ 1547 AMP_SupportKBDBeep "Information for AMP support Keyboard Beep";
CM_ SG_ 1547 AMP_Support_SDVC "Information for AMP support RANC (Road Active Noise Control)";
CM_ SG_ 1547 AMP_SupportRANC "Information for AMP support RANC (Road Active Noise Control)";
CM_ BO_ 591 "[PE] Periodic and On Event";
CM_ SG_ 591 ATS_RLStSldFwdBtn "Rear Left Power Seat Slide Forward Touch Button";
CM_ SG_ 591 ATS_RLStSldBwdBtn "Rear Left Power Seat Slide Backward Touch Button";
CM_ SG_ 591 ATS_RLStRclFwdBtn "Rear Left Power Seat Recline Forward Touch Button";
CM_ SG_ 591 ATS_RLStRclBwdBtn "Rear Left Power Seat Recline Backward Touch Button";
CM_ SG_ 591 ATS_RLStTltUpBtn "Rear Left Power Seat Tilt Up Touch Button";
CM_ SG_ 591 ATS_RLStTltDnBtn "Rear Left Power Seat Tilt Down Touch Button";
CM_ SG_ 591 ATS_RLStHRestUpBtn "Rear Left Power Seat Head Rest Up Touch Button";
CM_ SG_ 591 ATS_RLStHRestDnBtn "Rear Left Power Seat Head Rest Down Touch Button";
CM_ SG_ 591 ATS_RLStHRestFwdBtn "Rear Left Power Seat Head Rest Forward Touch Button";
CM_ SG_ 591 ATS_RLStHRestBwdBtn "Rear Left Power Seat Head Rest Backward Touch Button";
CM_ SG_ 591 ATS_RLStLegRestUpBtn "Rear Left Power Seat Leg Rest Up Touch Button";
CM_ SG_ 591 ATS_RLStLegRestDnBtn "Rear Left Power Seat Leg Rest Down Touch Button";
CM_ SG_ 591 ATS_RLStLegRestExtUpBtn "Rear Left Power Seat Leg Rest Ext. Up Touch Button";
CM_ SG_ 591 ATS_RLStLegRestExtDnBtn "Rear Left Power Seat Leg Rest Ext. Down Touch Button";
CM_ SG_ 591 ATS_RLStShoulderADJFwdBtn "Rear Left Power Seat Shoulder Adjuster Forward Touch Button";
CM_ SG_ 591 ATS_RLStShoulderADJBwdBtn "Rear Left Power Seat Shoulder Adjuster Backward Touch Button";
CM_ BO_ 607 "[PE] Periodic and On Event";
CM_ SG_ 607 ATS_RRStSldFwdBtn "Rear Right Power Seat Slide Forward Touch Button";
CM_ SG_ 607 ATS_RRStSldBwdBtn "Rear Right Power Seat Slide Backward Touch Button";
CM_ SG_ 607 ATS_RRStRclFwdBtn "Rear Right Power Seat Recline Forward Touch Button";
CM_ SG_ 607 ATS_RRStRclBwdBtn "Rear Right Power Seat Recline Backward Touch Button";
CM_ SG_ 607 ATS_RRStTltUpBtn "Rear Right Power Seat Tilt Up Touch Button";
CM_ SG_ 607 ATS_RRStTltDnBtn "Rear Right Power Seat Tilt Down Touch Button";
CM_ SG_ 607 ATS_RRStHRestUpBtn "Rear Right Power Seat Head Rest Up Touch Button";
CM_ SG_ 607 ATS_RRStHRestDnBtn "Rear Right Power Seat Head Rest Down Touch Button";
CM_ SG_ 607 ATS_RRStHRestFwdBtn "Rear Right Power Seat Head Rest Forward Touch Button";
CM_ SG_ 607 ATS_RRStHRestBwdBtn "Rear Right Power Seat Head Rest Backward Touch Button";
CM_ SG_ 607 ATS_RRStShoulderADJFwdBtn "Rear Right Power Seat Shoulder Adjuster Forward Touch Button";
CM_ SG_ 607 ATS_RRStShoulderADJBwdBtn "Rear Right Power Seat Shoulder Adjuster Backward Touch Button";
CM_ SG_ 607 ATS_RRStLegRestUpBtn "Rear Right Power Seat Leg Rest Up Touch Button";
CM_ SG_ 607 ATS_RRStLegRestDnBtn "Rear Right Power Seat Leg Rest Down Touch Button";
CM_ SG_ 607 ATS_RRStLegRestExtUpBtn "Rear Right Power Seat Leg Rest Ext. Up Touch Button";
CM_ SG_ 607 ATS_RRStLegRestExtDnBtn "Rear Right Power Seat Leg Rest Ext. Down Touch Button";
CM_ BO_ 1058 "[PE] Periodic and On Event";
CM_ SG_ 1058 BCM_Crc10Val "BCM_CyclicRedundancyCheck10Value";
CM_ SG_ 1058 BCM_AlvCnt10Val "BCM_AliveCounter10Value";
CM_ SG_ 1058 Wiper_PrkngPosSta "Wiper_ParkingPositionStatus ##2G##BCM - BCMmsg22 - C_WiperParkPosition";
CM_ SG_ 1058 Wiper_RainSnsrOptionTyp "Wiper_RainSensorOptionType ##2G##BCM - BCMmsg24 - C_RainSnsOption";
CM_ SG_ 1058 Wiper_RainSnsrSta "Wiper_RainSensorStatus ##2G##BCM - BCMmsg24 - C_RainSnsState";
CM_ SG_ 1058 BCM_SolSnsrRtOutVoltVal "BCM_SolarSensorRightOutputVoltageValue ##2G##BCM - BCMmsg24 - C_PhotosensorRH";
CM_ SG_ 1058 BCM_SolSnsrLftOutVoltVal "BCM_SolarSensorLeftOutputVoltageValue ##2G##BCM - BCMmsg24 - C_PhotosensorLH";
CM_ SG_ 1058 BCM_GearPosPSta "BCM_GearPositionPStatus ##2G##BCM - BCMmsg17 - C_PpositiOn";
CM_ SG_ 1058 BCM_SunRoofOpnSta "BCM_SunRoofOpenStatus ##2G##BCM - BCMmsg20 - C_SunRoofOpenState";
CM_ BO_ 2563128065 "[EC] On Event and On Change";
CM_ SG_ 2563128065 AMP_EngOrderC2GainSet "Command for Personal Engine Sound System (Engine Sound Equalizer) Advanced Setting for Engine order C2 (Powerful Lowband Sound)
Default : 0x5 (NVH Sound research lab tuning value)";
CM_ SG_ 2563128065 AMP_EngOrderC6GainSet "Command for Personal Engine Sound System (Engine Sound Equalizer) Advanced Setting for Engine order C6 (Highband Sound)
Default : 0x5 (NVH Sound research lab tuning value)";
CM_ SG_ 2563128065 AMP_EngOrderC4GainSet "Command for Personal Engine Sound System (Engine Sound Equalizer) Advanced Setting for Engine order C4 (Sporty Midband Sound)
Default : 0x5 (NVH Sound research lab tuning value)";
CM_ BO_ 2315420161 "[EC] On Event and On Change";
CM_ BO_ 118 "[P] Periodic";
CM_ SG_ 118 ICC_HS_Crc1Val "ICC_HS_CyclicRedundancyCheck1Value";
CM_ SG_ 118 ICC_HS_AlvCnt1Val "ICC_HS_AliveCounter1Value";
CM_ BO_ 119 "[P] Periodic";
CM_ SG_ 119 ICC_HS_Crc2Val "ICC_HS_CyclicRedundancyCheck2Value";
CM_ SG_ 119 ICC_HS_AlvCnt2Val "ICC_HS_AliveCounter2Value";
CM_ BO_ 120 "[P] Periodic";
CM_ SG_ 120 ICC_HS_Crc3Val "ICC_HS_CyclicRedundancyCheck3Value";
CM_ SG_ 120 ICC_HS_AlvCnt3Val "ICC_HS_AliveCounter3Value";
CM_ BO_ 121 "[P] Periodic";
CM_ SG_ 121 ICC_HS_Crc4Val "ICC_HS_CyclicRedundancyCheck4Value";
CM_ SG_ 121 ICC_HS_AlvCnt4Val "ICC_HS_AliveCounter4Value";
CM_ BO_ 1086 "[PE] Periodic and On Event";
CM_ SG_ 1086 RL_CURTAIN_POSITION "Rear Left Curtain Status Position Output";
CM_ SG_ 1086 RDC_SWVerMinor1 "Second Word(ASCII) in RDC S/W Ver";
CM_ SG_ 1086 RDC_SWVerMinor2 "Third Word(ASCII) in RDC S/W Ver";
CM_ SG_ 1086 RR_CURTAIN_POSITION "Rear Right Curtain Status Position Output";
CM_ SG_ 1086 RDC_OptTyp "OPTION FLAG for RDC";
CM_ SG_ 1086 RDC_SWVerMajor1 "First Word(ASCII) in RDC S/W Ver";
CM_ BO_ 1080 "[PE] Periodic and On Event";
CM_ SG_ 1080 RL_SHVU_SeatOptSta "Rear LH Seat Heater/Vent option info";
CM_ SG_ 1080 RL_SHVU_HtAutoDownRVal "Rear LH Seat Heater AutoDown R Value";
CM_ SG_ 1080 RL_SHVU_VntTurboSta "Rear LH Seat Vent Turbo Mode Status";
CM_ SG_ 1080 RL_SHVU_SeatOptSta_RHD "Rear LH Seat Heater/Vent option info";
CM_ SG_ 1080 RL_SHVU_SeatHtOperSta_RHD "Rear LH Seat Heater/Vent current operation state";
CM_ SG_ 1080 RL_SHVU_SeatHtOperSta "Rear LH Seat Heater/Vent current operation state";
CM_ SG_ 1080 RL_SHVU_HtSwHiIndSta_RHD "Rear Left_Seat Heater Switch High Indicator Status";
CM_ SG_ 1080 RL_SHVU_HtSwMidIndSta_RHD "Rear Left_Seat Heater Switch Mid Indicator Status";
CM_ SG_ 1080 RL_SHVU_HtSwLowIndSta_RHD "Rear Left_Seat Heater Switch Low Indicator Status";
CM_ SG_ 1080 RL_SHVU_VntSwHiIndSta_RHD "Rear Left Seat Vent Switch High Indicator Status";
CM_ SG_ 1080 RL_SHVU_VntSwMidIndSta_RHD "Rear Left Seat Vent Switch Mid Indicator Status";
CM_ SG_ 1080 RL_SHVU_VntSwLowIndSta_RHD "Rear Left Seat Vent Switch Low Indicator Status";
CM_ SG_ 1080 RL_SHVU_SeatHtFail "Rear LH Seat Heater/Vent FailSafe State";
CM_ BO_ 1070 "[PE] Periodic and On Event";
CM_ SG_ 1070 RL_SHVU_HtSwHiIndSta "Rear Left_Seat Heater Switch High Indicator Status";
CM_ SG_ 1070 RL_SHVU_HtSwMidIndSta "Rear Left_Seat Heater Switch Mid Indicator Status";
CM_ SG_ 1070 RL_SHVU_HtSwLowIndSta "Rear Left_Seat Heater Switch Low Indicator Status";
CM_ SG_ 1070 RL_SHVU_VntSwHiIndSta "Rear Left Seat Vent Switch High Indicator Status";
CM_ SG_ 1070 RL_SHVU_VntSwMidIndSta "Rear Left Seat Vent Switch Mid Indicator Status";
CM_ SG_ 1070 RL_SHVU_VntSwLowIndSta "Rear Left Seat Vent Switch Low Indicator Status";
CM_ SG_ 1070 RL_SHVU_HtBlcUsmSta "RL Seat Heater Balance Status";
CM_ BO_ 599 "[EC] On Event and On Change";
CM_ SG_ 599 RRPSM_AvWtcMemReq "RRPSM_AvWatchingPositionMemoryRequest";
CM_ SG_ 599 RRPSM_RearModeWngDisforATS "Rear Mode information for ATS";
CM_ SG_ 599 RRPSM_ReadingMemReq "RRPSM_ReadingPositionMemoryRequest";
CM_ SG_ 599 RRPSM_RestMemReq "RRPSM_RestModePositionMemoryRequest";
CM_ SG_ 599 RRPSM_ReturnMemReq "RRPSM_ReturnModePositionMemoryRequest";
CM_ SG_ 599 RRPSM_RearModeWngDis "Rear Mode information for AVN Display";
CM_ BO_ 127 "[PE] Periodic and On Event";
CM_ SG_ 127 RRPSS_Local_Crc1Val "RRPSS_CyclicRedundancyCheck1Value";
CM_ SG_ 127 RRPSS_Local_AlvCnt1Val "RRPSS_AliveCounter1Value";
CM_ SG_ 127 RRPSS_L_StSldFwdMvBtn "RRPSS_StSldFwdMvBtn";
CM_ SG_ 127 RRPSS_L_StSldBwdMvBtn "RRPSS_StSldBwdMvBtn";
CM_ SG_ 127 RRPSS_L_StRclFwdMvBtn "RRPSS_StRclFwdMvBtn";
CM_ SG_ 127 RRPSS_L_StRclBwdMvBtn "RRPSS_StRclBwdMvBtn";
CM_ SG_ 127 RRPSS_L_StTltUpMvBtn "RRPSS_StTltUpMvBtn";
CM_ SG_ 127 RRPSS_L_StTltDnMvBtn "RRPSS_StTltDnMvBtn";
CM_ SG_ 127 RRPSS_L_StHRestUpMvBtn "RRPSS_StHRestUpMvBtn";
CM_ SG_ 127 RRPSS_L_StHRestDnMvBtn "RRPSS_StHRestDnMvBtn";
CM_ SG_ 127 RRPSS_L_StHRestFwdMvBtn "RRPSS_StHRestFwdMvBtn";
CM_ SG_ 127 RRPSS_L_StHRestBwdMvBtn "RRPSS_StHRestBwdMvBtn";
CM_ SG_ 127 RRPSS_L_StLegRestUpBtn "RRPSS_Leg Rest Up Move Button";
CM_ SG_ 127 RRPSS_L_StLegRestDnBtn "RRPSS_Leg Rest Down Move Button";
CM_ SG_ 127 RRPSS_L_StLegRestExtUpBtn "RRPSS_Leg Support Forward Move Button";
CM_ SG_ 127 RRPSS_L_StLegRestExtDnBtn "RRPSS_Leg Support Backward Move Button";
CM_ BO_ 1071 "[PE] Periodic and On Event";
CM_ SG_ 1071 RR_SHVU_HtSwHiIndSta "Rear Right_Seat Heater Switch High Indicator Status";
CM_ SG_ 1071 RR_SHVU_HtSwMidIndSta "Rear Left_Seat Heater Switch Mid Indicator Status";
CM_ SG_ 1071 RR_SHVU_HtSwLowIndSta "Rear Right_Seat Heater Switch Low Indicator Status";
CM_ SG_ 1071 RR_SHVU_VntSwHiIndSta "Rear Right Seat Vent Switch High Indicator Status";
CM_ SG_ 1071 RR_SHVU_VntSwMidIndSta "Rear Right Seat Vent Switch Mid Indicator Status";
CM_ SG_ 1071 RR_SHVU_VntSwLowIndSta "Rear Right Seat Vent Switch Low Indicator Status";
CM_ SG_ 1071 RR_SHVU_HtBlcUsmSta "RR Seat Heater Balance Status";
CM_ BO_ 1073 "[PE] Periodic and On Event";
CM_ SG_ 1073 USM_ValCmdSta "USM_ValueCommandStatus";
CM_ SG_ 1073 RWPC_SWVerMinor1 "Second Word(ASCII) in RWPC S/W Ver";
CM_ SG_ 1073 WPC_PhnLftWrngRWPCSta "WPC_PhoneLeftWaringRWPCStatus";
CM_ SG_ 1073 RWPC_SWVerMinor2 "Third Word(ASCII) in RWPC S/W Ver";
CM_ SG_ 1073 USM_ValCmdStaforATS "USM_ValueCommandStatus";
CM_ SG_ 1073 RWPC_SWVerMajor1 "First Word(ASCII) in RWPC S/W Ver";
BA_DEF_ BO_ "DiagState" ENUM "No","Yes" ;
BA_DEF_ BO_ "DiagResponse" ENUM "No","Yes" ;
BA_DEF_ BO_ "DiagRequest" ENUM "No","Yes" ;
BA_DEF_ BO_ "TpMessage" ENUM "No","Yes" ;
BA_DEF_ BO_ "UsrMsgIDSforwardDeviation" INT 0 100 ;
BA_DEF_ BO_ "UsrMsgIDSbackwardDeviation" INT 50 1000 ;
BA_DEF_ BO_ "GenMsgCycleTime" INT 0 2000 ;
BA_DEF_ BO_ "GenMsgStartDelayTime" INT 0 2000 ;
BA_DEF_ BO_ "GenMsgSendType" ENUM "Cyclic","NoMsgSendType" ;
BA_DEF_ BO_ "GenMsgCycleTimeFast" INT 0 500 ;
BA_DEF_ BO_ "GenMsgDelayTime" INT 0 20 ;
BA_DEF_ BO_ "GenMsgILSupport" ENUM "No","Yes" ;
BA_DEF_ BO_ "GenMsgNrOfRepetition" INT 0 3 ;
BA_DEF_ BO_ "NmMessage" ENUM "No","Yes" ;
BA_DEF_ BO_ "NWM-Botschaft" ENUM "No","Yes" ;
BA_DEF_ BO_ "TpTxIndex" INT 0 255 ;
BA_DEF_ BO_ "VFrameFormat" ENUM "StandardCAN","ExtendedCAN","reserved","reserved","reserved","reserved","reserved","reserved","reserved","reserved","reserved","reserved","reserved","reserved","StandardCAN_FD","ExtendedCAN_FD" ;
BA_DEF_ SG_ "UserSigValidity" ENUM "B+","ACC","IG","IG1","IG2","IG3","IG1 or IG2","IG1 or IG3","Undef" ;
BA_DEF_ SG_ "TimeoutValue" STRING ;
BA_DEF_ SG_ "UsrSigPurpose" ENUM "Undef","FN","DIAG","DIAG(Req)","DIAG(Res)","DIAG(Phy)","DEV","CCP(Req)","CCP(Res)","NM","TP" ;
BA_DEF_ SG_ "GenSigStartValue" INT 0 1215752192 ;
BA_DEF_ SG_ "NetworkRequest" ENUM "Yes","No" ;
BA_DEF_ SG_ "NetworkRequestHoldingTime" INT 0 65535 ;
BA_DEF_ SG_ "Description" STRING ;
BA_DEF_ SG_ "Version" STRING ;
BA_DEF_ SG_ "GenSigEnvVarType" ENUM "Int","Float","Undef" ;
BA_DEF_ SG_ "GenSigSendType" ENUM "Cyclic","OnWrite","OnWriteWithRepetition","OnChange","OnChangeWithRepetition","IfActive","IfActiveWithRepetition","NoSigSendType","OnChangeAndIfActive","OnChangeAndIfActiveWithRepetition" ;
BA_DEF_ SG_ "GwSigLatencyTime" INT 0 65536 ;
BA_DEF_ SG_ "GwSigMissingSourceType" ENUM "Undef","OldValue","DefaultValue","InitialValue" ;
BA_DEF_ SG_ "NWM-WakeupAllowed" ENUM "<n.a.>" ;
BA_DEF_ SG_ "RoutingFactor" INT 1 1215752192 ;
BA_DEF_REL_ BU_SG_REL_ "GenSigTimeoutTime" INT 0 7000 ;
BA_DEF_DEF_ "DiagState" "No" ;
BA_DEF_DEF_ "DiagResponse" "No" ;
BA_DEF_DEF_ "DiagRequest" "No" ;
BA_DEF_DEF_ "TpMessage" "No" ;
BA_DEF_DEF_ "UsrMsgIDSforwardDeviation" 10 ;
BA_DEF_DEF_ "UsrMsgIDSbackwardDeviation" 100 ;
BA_DEF_DEF_ "GenMsgCycleTime" 200 ;
BA_DEF_DEF_ "GenMsgStartDelayTime" 0 ;
BA_DEF_DEF_ "GenMsgSendType" "NoMsgSendType" ;
BA_DEF_DEF_ "GenMsgCycleTimeFast" 40 ;
BA_DEF_DEF_ "GenMsgDelayTime" 20 ;
BA_DEF_DEF_ "GenMsgILSupport" "Yes" ;
BA_DEF_DEF_ "GenMsgNrOfRepetition" 3 ;
BA_DEF_DEF_ "NmMessage" "No" ;
BA_DEF_DEF_ "NWM-Botschaft" "No" ;
BA_DEF_DEF_ "TpTxIndex" 0 ;
BA_DEF_DEF_ "VFrameFormat" "StandardCAN" ;
BA_DEF_DEF_ "UserSigValidity" "IG" ;
BA_DEF_DEF_ "TimeoutValue" "" ;
BA_DEF_DEF_ "UsrSigPurpose" "FN" ;
BA_DEF_DEF_ "GenSigStartValue" 0 ;
BA_DEF_DEF_ "NetworkRequest" "No" ;
BA_DEF_DEF_ "NetworkRequestHoldingTime" 0 ;
BA_DEF_DEF_ "Description" "" ;
BA_DEF_DEF_ "Version" "" ;
BA_DEF_DEF_ "GenSigEnvVarType" "Undef" ;
BA_DEF_DEF_ "GenSigSendType" "NoSigSendType" ;
BA_DEF_DEF_ "GwSigLatencyTime" 40 ;
BA_DEF_DEF_ "GwSigMissingSourceType" "Undef" ;
BA_DEF_DEF_ "NWM-WakeupAllowed" "<n.a.>" ;
BA_DEF_DEF_ "RoutingFactor" 1 ;
BA_DEF_DEF_REL_ "GenSigTimeoutTime" 500 ;
BA_ "GenMsgSendType" BO_ 2239849729 0;
BA_ "GenMsgCycleTime" BO_ 2239849729 100;
BA_ "GenMsgCycleTimeFast" BO_ 2239849729 0;
BA_ "GenMsgNrOfRepetition" BO_ 2239849729 0;
BA_ "VFrameFormat" BO_ 2239849729 1;
BA_ "Description" SG_ 2239849729 ADAS_PRK_Crc2Val "The data area for CRC calculation is based on the data length (DLC) of the message DB.

The CRC shall be calculated over the entire data block (excluding the CRC bytes) including the user data, alive counter and Data ID

 

- CRC Polynomial (0x1021) , Initial Value : 0xFFFF, XOR value : 0x0000, Data ID : Message ID + 0xF800 

- The initial value is for CRC calculation and the message should be sent with the calculated result value. 

- The mathematical expression to 16 bit CRC polynomial is given here. G(x) = x16 + x12 + x5 + 1";
BA_ "GenSigStartValue" SG_ 2239849729 ADAS_PRK_Crc2Val 65535;
BA_ "UserSigValidity" SG_ 2239849729 ADAS_PRK_Crc2Val 3;
BA_ "RoutingFactor" SG_ 2239849729 ADAS_PRK_Crc2Val 5;
BA_ "Version" SG_ 2239849729 ADAS_PRK_Crc2Val "18.11.08";
BA_ "Description" SG_ 2239849729 ADAS_PRK_AlvCnt2Val "For the first transmission request for a data element the counter shall be initialized with 0 and shall be incremented by 1 for every subsequent send request. 

When the counter reaches the maximum value(0xFF), then it shall restart with 0 for the next send request";
BA_ "UserSigValidity" SG_ 2239849729 ADAS_PRK_AlvCnt2Val 3;
BA_ "RoutingFactor" SG_ 2239849729 ADAS_PRK_AlvCnt2Val 5;
BA_ "Version" SG_ 2239849729 ADAS_PRK_AlvCnt2Val "18.11.08";
BA_ "Description" SG_ 2239849729 PA_ModDis "This signal is used for PA/PDW display ON/OFF.

The value is sended to be based on the PA/PDW internal activation status, not the only switch status.

This means that the signal value should be OFF in case of PA/PDW internal activation status OFF, although PA/PDW switch is ON.



<Fuction>

0H : PA OFF, PDW OFF

1H : PA OFF, PDW ON

2H : PA ON, PDW OFF

3H : PA ON, PDW ON";
BA_ "UserSigValidity" SG_ 2239849729 PA_ModDis 3;
BA_ "RoutingFactor" SG_ 2239849729 PA_ModDis 5;
BA_ "Version" SG_ 2239849729 PA_ModDis "17.12.03";
BA_ "Description" SG_ 2239849729 PA_ModSelSeqDis "The signal is used for PA mode selection tap of Cluster.";
BA_ "UserSigValidity" SG_ 2239849729 PA_ModSelSeqDis 3;
BA_ "RoutingFactor" SG_ 2239849729 PA_ModSelSeqDis 5;
BA_ "Version" SG_ 2239849729 PA_ModSelSeqDis "17.11.00";
BA_ "Description" SG_ 2239849729 PA_RSPA_Opt "0x0: PA & RSPA (ENTRY) & RSPA 기능 등 MDPS 조향 제어 필요 기능 미적용 시,

        신호값 '0x0' 송출.  

0x1: PA or RSPA (ENTRY) or RSPA 등 MDPS 조향 제어 필요 기능 적용 시, 

        신호값 '0x1' 송출.";
BA_ "UserSigValidity" SG_ 2239849729 PA_RSPA_Opt 3;
BA_ "RoutingFactor" SG_ 2239849729 PA_RSPA_Opt 5;
BA_ "Version" SG_ 2239849729 PA_RSPA_Opt "19.12.01";
BA_ "Description" SG_ 2239849729 PA_HmiStaDis "This signal is used for PA HMI indicator (display).";
BA_ "UserSigValidity" SG_ 2239849729 PA_HmiStaDis 3;
BA_ "RoutingFactor" SG_ 2239849729 PA_HmiStaDis 5;
BA_ "Version" SG_ 2239849729 PA_HmiStaDis "19.01.04";
BA_ "Description" SG_ 2239849729 PA_FrLtWrngDis "This signal is used for PA sensors warning indicator(display).";
BA_ "UserSigValidity" SG_ 2239849729 PA_FrLtWrngDis 3;
BA_ "RoutingFactor" SG_ 2239849729 PA_FrLtWrngDis 5;
BA_ "Version" SG_ 2239849729 PA_FrLtWrngDis "20.03.02";
BA_ "Description" SG_ 2239849729 PA_FrCtWrngDis "This signal is used for PA sensors warning indicator(display).

PA_FrCtrWrngDis signal is to indicate the closest obstacle warning among front inner left & right sensors.";
BA_ "UserSigValidity" SG_ 2239849729 PA_FrCtWrngDis 3;
BA_ "RoutingFactor" SG_ 2239849729 PA_FrCtWrngDis 5;
BA_ "Version" SG_ 2239849729 PA_FrCtWrngDis "20.03.02";
BA_ "Description" SG_ 2239849729 PA_FrRtWrngDis "This signal is used for PA sensors warning indicator(display).";
BA_ "UserSigValidity" SG_ 2239849729 PA_FrRtWrngDis 3;
BA_ "RoutingFactor" SG_ 2239849729 PA_FrRtWrngDis 5;
BA_ "Version" SG_ 2239849729 PA_FrRtWrngDis "17.11.00";
BA_ "Description" SG_ 2239849729 PA_RrLtWrngDis "This signal is used for PA sensors warning indicator(display).";
BA_ "UserSigValidity" SG_ 2239849729 PA_RrLtWrngDis 3;
BA_ "RoutingFactor" SG_ 2239849729 PA_RrLtWrngDis 5;
BA_ "Version" SG_ 2239849729 PA_RrLtWrngDis "20.03.02";
BA_ "Description" SG_ 2239849729 PA_RrCtWrngDis "This signal is used for PA sensors warning indicator(display).

PA_RrCtrWrngDis signal is to indicate the closest obstacle warning among rear inner left & right sensors.";
BA_ "UserSigValidity" SG_ 2239849729 PA_RrCtWrngDis 3;
BA_ "RoutingFactor" SG_ 2239849729 PA_RrCtWrngDis 5;
BA_ "Version" SG_ 2239849729 PA_RrCtWrngDis "20.03.02";
BA_ "Description" SG_ 2239849729 PA_RrRtWrngDis "This signal is used for PA sensors warning indicator(display).";
BA_ "UserSigValidity" SG_ 2239849729 PA_RrRtWrngDis 3;
BA_ "RoutingFactor" SG_ 2239849729 PA_RrRtWrngDis 5;
BA_ "Version" SG_ 2239849729 PA_RrRtWrngDis "17.11.00";
BA_ "GenMsgSendType" BO_ 2239849730 0;
BA_ "GenMsgCycleTime" BO_ 2239849730 100;
BA_ "GenMsgCycleTimeFast" BO_ 2239849730 0;
BA_ "GenMsgNrOfRepetition" BO_ 2239849730 0;
BA_ "VFrameFormat" BO_ 2239849730 1;
BA_ "Description" SG_ 2239849730 PA_BpAlrmReq "This signal is used for Beep warning alarm of PA/PDW in AMP Speaker

and PIEZO(SMK) Buzzer";
BA_ "UserSigValidity" SG_ 2239849730 PA_BpAlrmReq 3;
BA_ "RoutingFactor" SG_ 2239849730 PA_BpAlrmReq 5;
BA_ "Version" SG_ 2239849730 PA_BpAlrmReq "18.08.07";
BA_ "Description" SG_ 2239849730 PA_FrWrngAlrmReq "This signal is used for front warning alarm of PA/PDW.";
BA_ "UserSigValidity" SG_ 2239849730 PA_FrWrngAlrmReq 3;
BA_ "RoutingFactor" SG_ 2239849730 PA_FrWrngAlrmReq 5;
BA_ "Version" SG_ 2239849730 PA_FrWrngAlrmReq "17.11.00";
BA_ "Description" SG_ 2239849730 PA_RrWrngAlrmReq "This signal is used for rear warning alarm of PA/PDW.";
BA_ "UserSigValidity" SG_ 2239849730 PA_RrWrngAlrmReq 3;
BA_ "RoutingFactor" SG_ 2239849730 PA_RrWrngAlrmReq 5;
BA_ "Version" SG_ 2239849730 PA_RrWrngAlrmReq "17.11.00";
BA_ "Description" SG_ 2239849730 PA_FrLtWrngAlrmReq "This signal is used for front left warning alarm of PA/PDW for EXP AMP";
BA_ "UserSigValidity" SG_ 2239849730 PA_FrLtWrngAlrmReq 3;
BA_REL_ "GenSigTimeoutTime" BU_SG_REL_ AMP SG_ 2239849730 PA_FrLtWrngAlrmReq 1500;
BA_ "RoutingFactor" SG_ 2239849730 PA_FrLtWrngAlrmReq 5;
BA_ "Version" SG_ 2239849730 PA_FrLtWrngAlrmReq "20.03.02";
BA_ "Description" SG_ 2239849730 PA_FrCtWrngAlrmReq "This signal is used for front center warning alarm of PA/PDW for EXP AMP";
BA_ "UserSigValidity" SG_ 2239849730 PA_FrCtWrngAlrmReq 3;
BA_REL_ "GenSigTimeoutTime" BU_SG_REL_ AMP SG_ 2239849730 PA_FrCtWrngAlrmReq 1500;
BA_ "RoutingFactor" SG_ 2239849730 PA_FrCtWrngAlrmReq 5;
BA_ "Version" SG_ 2239849730 PA_FrCtWrngAlrmReq "20.03.02";
BA_ "Description" SG_ 2239849730 PA_FrRtWrngAlrmReq "This signal is used for front right warning alarm of PA/PDW for EXP AMP";
BA_ "UserSigValidity" SG_ 2239849730 PA_FrRtWrngAlrmReq 3;
BA_REL_ "GenSigTimeoutTime" BU_SG_REL_ AMP SG_ 2239849730 PA_FrRtWrngAlrmReq 1500;
BA_ "RoutingFactor" SG_ 2239849730 PA_FrRtWrngAlrmReq 5;
BA_ "Version" SG_ 2239849730 PA_FrRtWrngAlrmReq "17.11.00";
BA_ "Description" SG_ 2239849730 PA_RrLtWrngAlrmReq "This signal is used for rear left warning alarm of PA/PDW for EXP AMP";
BA_ "UserSigValidity" SG_ 2239849730 PA_RrLtWrngAlrmReq 3;
BA_REL_ "GenSigTimeoutTime" BU_SG_REL_ AMP SG_ 2239849730 PA_RrLtWrngAlrmReq 1500;
BA_ "RoutingFactor" SG_ 2239849730 PA_RrLtWrngAlrmReq 5;
BA_ "Version" SG_ 2239849730 PA_RrLtWrngAlrmReq "20.03.02";
BA_ "Description" SG_ 2239849730 PA_RrCtWrngAlrmReq "This signal is used for rear center warning alarm of PA/PDW for EXP AMP";
BA_ "UserSigValidity" SG_ 2239849730 PA_RrCtWrngAlrmReq 3;
BA_REL_ "GenSigTimeoutTime" BU_SG_REL_ AMP SG_ 2239849730 PA_RrCtWrngAlrmReq 1500;
BA_ "RoutingFactor" SG_ 2239849730 PA_RrCtWrngAlrmReq 5;
BA_ "Version" SG_ 2239849730 PA_RrCtWrngAlrmReq "20.03.02";
BA_ "Description" SG_ 2239849730 PA_RrRtWrngAlrmReq "This signal is used for rear right warning alarm of PA/PDW for EXP AMP";
BA_ "UserSigValidity" SG_ 2239849730 PA_RrRtWrngAlrmReq 3;
BA_REL_ "GenSigTimeoutTime" BU_SG_REL_ AMP SG_ 2239849730 PA_RrRtWrngAlrmReq 1500;
BA_ "RoutingFactor" SG_ 2239849730 PA_RrRtWrngAlrmReq 5;
BA_ "Version" SG_ 2239849730 PA_RrRtWrngAlrmReq "17.11.00";
BA_ "Description" SG_ 2239849730 PA_Sta "This signal indicates the status of the PA steering activation machine. 



 <Fuction>

0H : Reserved

1H : Initial value after ignition

2H : Request of a new start status after an abort of the MDPS

3H : StandBy status of the PA function. No error and no request

4H : First request toward an automatic steering

5H : Final request for an automatic steering

6H : Acknowledge an MDPS failure. This state is set for one cycle only

7H : Acknowledge an MDPS abort. This state is set for one cycle only

8H ~ FH : Reserved";
BA_ "GenSigStartValue" SG_ 2239849730 PA_Sta 1;
BA_ "UserSigValidity" SG_ 2239849730 PA_Sta 3;
BA_ "RoutingFactor" SG_ 2239849730 PA_Sta 5;
BA_ "Version" SG_ 2239849730 PA_Sta "17.12.03";
BA_ "Description" SG_ 2239849730 PA_TestModSta "This signal indicates the status of the “ MDPS Activation control for testing the PA system”";
BA_ "UserSigValidity" SG_ 2239849730 PA_TestModSta 3;
BA_ "RoutingFactor" SG_ 2239849730 PA_TestModSta 5;
BA_ "Version" SG_ 2239849730 PA_TestModSta "17.11.00";
BA_ "Description" SG_ 2239849730 PA_StrAnglReq "This value is used to set a steering wheel position target for the PA function. The signal is signed 16bits.



Conversion: (PH) = (HEX) x 0.1 (for 0< HEX < 32767) OR

(HEX - 65536) x 0.1 (for HEX > 32767)";
BA_ "UserSigValidity" SG_ 2239849730 PA_StrAnglReq 3;
BA_ "RoutingFactor" SG_ 2239849730 PA_StrAnglReq 5;
BA_ "Version" SG_ 2239849730 PA_StrAnglReq "17.11.00";
BA_ "Description" SG_ 2239849730 ADAS_PRK_OptInfo "Information of Resolution/PCLK to H/U

Bit0 : RVM PCLK for ADAS_PRK (0: Not Support / 1: Support)

Bit1 : PCA-R Warning Level State Display Spec (0: Old / 1: New)

Bit2 : Reserved

Bit3 : Reserved";
BA_ "UserSigValidity" SG_ 2239849730 ADAS_PRK_OptInfo 3;
BA_ "RoutingFactor" SG_ 2239849730 ADAS_PRK_OptInfo 5;
BA_ "Version" SG_ 2239849730 ADAS_PRK_OptInfo "20.01.01";
BA_ "Description" SG_ 2239849730 PA_AlrmVlmLvlReq "This signal is used for adjusting PDW Volume";
BA_ "UserSigValidity" SG_ 2239849730 PA_AlrmVlmLvlReq 3;
BA_ "RoutingFactor" SG_ 2239849730 PA_AlrmVlmLvlReq 5;
BA_ "Version" SG_ 2239849730 PA_AlrmVlmLvlReq "17.11.00";
BA_ "Description" SG_ 2239849730 PA_LtFrWrngDis "This signal is used for PA sensors warning indicator(display).

PA_LtFrWrngDis signal is to indicate the closest obstacle warning among left sensors.";
BA_ "UserSigValidity" SG_ 2239849730 PA_LtFrWrngDis 3;
BA_ "RoutingFactor" SG_ 2239849730 PA_LtFrWrngDis 5;
BA_ "Version" SG_ 2239849730 PA_LtFrWrngDis "20.06.02";
BA_ "Description" SG_ 2239849730 PA_RtFrWrngDis "This signal is used for PA sensors warning indicator(display).

PA_RtFrWrngDis signal is to indicate the closest obstacle warning among right sensors.";
BA_ "UserSigValidity" SG_ 2239849730 PA_RtFrWrngDis 3;
BA_ "RoutingFactor" SG_ 2239849730 PA_RtFrWrngDis 5;
BA_ "Version" SG_ 2239849730 PA_RtFrWrngDis "20.06.02";
BA_ "Description" SG_ 2239849730 PA_SdWrngAlrmReq "This signal is used for side warning alarm of PA/PDW.";
BA_ "UserSigValidity" SG_ 2239849730 PA_SdWrngAlrmReq 3;
BA_REL_ "GenSigTimeoutTime" BU_SG_REL_ AMP SG_ 2239849730 PA_SdWrngAlrmReq 1500;
BA_ "RoutingFactor" SG_ 2239849730 PA_SdWrngAlrmReq 5;
BA_ "Version" SG_ 2239849730 PA_SdWrngAlrmReq "20.06.02";
BA_ "Description" SG_ 2239849730 PA_AlrmVlmDeratingReq "This signal indicates function of Audio volume down during PA / PDW Warning Alarm.";
BA_ "UserSigValidity" SG_ 2239849730 PA_AlrmVlmDeratingReq 3;
BA_ "RoutingFactor" SG_ 2239849730 PA_AlrmVlmDeratingReq 5;
BA_ "Version" SG_ 2239849730 PA_AlrmVlmDeratingReq "17.11.00";
BA_ "GenMsgSendType" BO_ 2239849731 0;
BA_ "GenMsgCycleTime" BO_ 2239849731 100;
BA_ "GenMsgCycleTimeFast" BO_ 2239849731 0;
BA_ "GenMsgNrOfRepetition" BO_ 2239849731 0;
BA_ "VFrameFormat" BO_ 2239849731 1;
BA_ "Description" SG_ 2239849731 PA_LtWrngDis "This signal is used for PA sensors warning indicator(display).

PA_LtWrngDis signal is to indicate the closest obstacle warning among left sensors.";
BA_ "UserSigValidity" SG_ 2239849731 PA_LtWrngDis 3;
BA_ "RoutingFactor" SG_ 2239849731 PA_LtWrngDis 5;
BA_ "Version" SG_ 2239849731 PA_LtWrngDis "20.06.02";
BA_ "Description" SG_ 2239849731 PA_RtRrWrngDis "This signal is used for PA sensors warning indicator(display).

PA_RtRrWrngDis signal is to indicate the closest obstacle warning among right sensors.";
BA_ "UserSigValidity" SG_ 2239849731 PA_RtRrWrngDis 3;
BA_ "RoutingFactor" SG_ 2239849731 PA_RtRrWrngDis 5;
BA_ "Version" SG_ 2239849731 PA_RtRrWrngDis "20.06.02";
BA_ "Description" SG_ 2239849731 PA_SdRtWrngAlrmReq "This signal is used for side right warning alarm of PA/PDW.";
BA_ "UserSigValidity" SG_ 2239849731 PA_SdRtWrngAlrmReq 3;
BA_REL_ "GenSigTimeoutTime" BU_SG_REL_ AMP SG_ 2239849731 PA_SdRtWrngAlrmReq 1500;
BA_ "RoutingFactor" SG_ 2239849731 PA_SdRtWrngAlrmReq 5;
BA_ "Version" SG_ 2239849731 PA_SdRtWrngAlrmReq "20.06.02";
BA_ "Description" SG_ 2239849731 PA_RtWrngDis "This signal is used for PA sensors warning indicator(display).

PA_RtWrngDis signal is to indicate the closest obstacle warning among right sensors.";
BA_ "UserSigValidity" SG_ 2239849731 PA_RtWrngDis 3;
BA_ "RoutingFactor" SG_ 2239849731 PA_RtWrngDis 5;
BA_ "Version" SG_ 2239849731 PA_RtWrngDis "20.06.02";
BA_ "Description" SG_ 2239849731 PA_SdLtWrngAlrmReq "This signal is used for side left warning alarm of PA/PDW.";
BA_ "UserSigValidity" SG_ 2239849731 PA_SdLtWrngAlrmReq 3;
BA_REL_ "GenSigTimeoutTime" BU_SG_REL_ AMP SG_ 2239849731 PA_SdLtWrngAlrmReq 1500;
BA_ "RoutingFactor" SG_ 2239849731 PA_SdLtWrngAlrmReq 5;
BA_ "Version" SG_ 2239849731 PA_SdLtWrngAlrmReq "20.06.02";
BA_ "Description" SG_ 2239849731 PA_LtRrWrngDis "This signal is used for PA sensors warning indicator(display).

PA_LtRrWrngDis signal is to indicate the closest obstacle warning among left sensors.";
BA_ "UserSigValidity" SG_ 2239849731 PA_LtRrWrngDis 3;
BA_ "RoutingFactor" SG_ 2239849731 PA_LtRrWrngDis 5;
BA_ "Version" SG_ 2239849731 PA_LtRrWrngDis "20.06.02";
BA_ "GenMsgCycleTime" BO_ 1555 0;
BA_ "GenSigSendType" SG_ 1555 AMP_NaviVolumeState 4;
BA_ "GenSigStartValue" SG_ 1555 AMP_NaviVolumeState 255;
BA_ "UserSigValidity" SG_ 1555 AMP_NaviVolumeState 1;
BA_REL_ "GenSigTimeoutTime" BU_SG_REL_ CGW_CCU SG_ 1555 AMP_NaviVolumeState 0;
BA_ "NetworkRequest" SG_ 1555 AMP_NaviVolumeState 0;
BA_ "Version" SG_ 1555 AMP_NaviVolumeState "19.01.07";
BA_ "Description" SG_ 1555 DATC_Beep1_OutputCh_State "Command for Set DATC Beep1 Output Channel to identify which Speakers will output Sound

- per bit, 0 means 'Not Output Channel' and 1 means 'Output Channel'

bit0 : FL / bit1 : FR / bit2 : RL / bit3 : RR / bit4 : CTR / bit5 : Surround L /

bit6 : Surround R / bit7 : SWF / bit8 : Headrest L / bit9 : Headrest R / bit10 : Loof L /

bit11 : Loof CTR / bit12 : Loof R / bit13~bit15 : Reserved

- Feedback from DATC_Beep1_OutputCh_Select@H_U_MM";
BA_ "GenSigSendType" SG_ 1555 DATC_Beep1_OutputCh_State 4;
BA_ "GenSigStartValue" SG_ 1555 DATC_Beep1_OutputCh_State 65535;
BA_ "UserSigValidity" SG_ 1555 DATC_Beep1_OutputCh_State 1;
BA_REL_ "GenSigTimeoutTime" BU_SG_REL_ CGW_CCU SG_ 1555 DATC_Beep1_OutputCh_State 0;
BA_ "Version" SG_ 1555 DATC_Beep1_OutputCh_State "21.07.05";
BA_ "Description" SG_ 1555 DATC_Beep1FrequencyState "Information for current DATC touch beep frequency

-range : 20Hz ~ 20000Hz";
BA_ "GenSigSendType" SG_ 1555 DATC_Beep1FrequencyState 4;
BA_ "GenSigStartValue" SG_ 1555 DATC_Beep1FrequencyState 65535;
BA_ "UserSigValidity" SG_ 1555 DATC_Beep1FrequencyState 1;
BA_REL_ "GenSigTimeoutTime" BU_SG_REL_ CGW_CCU SG_ 1555 DATC_Beep1FrequencyState 0;
BA_ "Version" SG_ 1555 DATC_Beep1FrequencyState "21.07.05";
BA_ "Description" SG_ 1555 DATC_Beep1VolumeState "Information for Current DATC Beep Sound Volume Setting Status

-range : 0 ~ max

-max : value of AMP_MaxBeep1VolumeState

-Feedback from DATC_Beep1VolumeStep@H_U";
BA_ "GenSigSendType" SG_ 1555 DATC_Beep1VolumeState 4;
BA_ "GenSigStartValue" SG_ 1555 DATC_Beep1VolumeState 255;
BA_ "UserSigValidity" SG_ 1555 DATC_Beep1VolumeState 1;
BA_REL_ "GenSigTimeoutTime" BU_SG_REL_ CGW_CCU SG_ 1555 DATC_Beep1VolumeState 0;
BA_ "Version" SG_ 1555 DATC_Beep1VolumeState "20.03.03";
BA_ "GenMsgCycleTime" BO_ 1538 0;
BA_ "GenSigSendType" SG_ 1538 AMP_MTSVolumeState 4;
BA_ "GenSigStartValue" SG_ 1538 AMP_MTSVolumeState 255;
BA_ "UserSigValidity" SG_ 1538 AMP_MTSVolumeState 1;
BA_REL_ "GenSigTimeoutTime" BU_SG_REL_ CGW_CCU SG_ 1538 AMP_MTSVolumeState 0;
BA_ "NetworkRequest" SG_ 1538 AMP_MTSVolumeState 0;
BA_ "Version" SG_ 1538 AMP_MTSVolumeState "18.12.06";
BA_ "Description" SG_ 1538 DVRS_Beep_OutputCh_State "Command for Set DVRS Beep Output Channel to identify which Speakers will output Sound

- per bit, 0 means 'Not Output Channel' and 1 means 'Output Channel'

bit0 : FL / bit1 : FR / bit2 : RL / bit3 : RR / bit4 : CTR / bit5 : Surround L /

bit6 : Surround R / bit7 : SWF / bit8 : Headrest L / bit9 : Headrest R / bit10 : Loof L /

bit11 : Loof CTR / bit12 : Loof R / bit13~bit15 : Reserved

- Feedback from DVRS_Beep_OutputCh_Select@H_U_MM";
BA_ "GenSigSendType" SG_ 1538 DVRS_Beep_OutputCh_State 4;
BA_ "GenSigStartValue" SG_ 1538 DVRS_Beep_OutputCh_State 65535;
BA_ "UserSigValidity" SG_ 1538 DVRS_Beep_OutputCh_State 1;
BA_REL_ "GenSigTimeoutTime" BU_SG_REL_ CGW_CCU SG_ 1538 DVRS_Beep_OutputCh_State 0;
BA_ "Version" SG_ 1538 DVRS_Beep_OutputCh_State "20.03.03";
BA_ "Description" SG_ 1538 DVRS_BeepFrequencyState "Information for current DVRS touch beep frequency

-range : 20Hz ~ 20000Hz";
BA_ "GenSigSendType" SG_ 1538 DVRS_BeepFrequencyState 4;
BA_ "GenSigStartValue" SG_ 1538 DVRS_BeepFrequencyState 65535;
BA_ "UserSigValidity" SG_ 1538 DVRS_BeepFrequencyState 1;
BA_REL_ "GenSigTimeoutTime" BU_SG_REL_ CGW_CCU SG_ 1538 DVRS_BeepFrequencyState 0;
BA_ "Version" SG_ 1538 DVRS_BeepFrequencyState "21.07.05";
BA_ "Description" SG_ 1538 DVRS_BeepVolumeState "Information for Current DVRS Beep Sound Volume Setting Status

-range : 0 ~ max

-max : value of AMP_MaxBeep1VolumeState

-Feedback from DVRS_BeepVolumeStep@H_U";
BA_ "GenSigSendType" SG_ 1538 DVRS_BeepVolumeState 4;
BA_ "GenSigStartValue" SG_ 1538 DVRS_BeepVolumeState 255;
BA_ "UserSigValidity" SG_ 1538 DVRS_BeepVolumeState 1;
BA_REL_ "GenSigTimeoutTime" BU_SG_REL_ CGW_CCU SG_ 1538 DVRS_BeepVolumeState 0;
BA_ "Version" SG_ 1538 DVRS_BeepVolumeState "20.03.03";
BA_ "GenMsgCycleTime" BO_ 1539 0;
BA_ "GenSigSendType" SG_ 1539 AMP_HFVolumeState 4;
BA_ "GenSigStartValue" SG_ 1539 AMP_HFVolumeState 255;
BA_ "UserSigValidity" SG_ 1539 AMP_HFVolumeState 1;
BA_REL_ "GenSigTimeoutTime" BU_SG_REL_ CGW_CCU SG_ 1539 AMP_HFVolumeState 0;
BA_ "NetworkRequest" SG_ 1539 AMP_HFVolumeState 0;
BA_ "Version" SG_ 1539 AMP_HFVolumeState "18.12.06";
BA_ "Description" SG_ 1539 ATS_Beep_OutputCh_State "Command for Set ATS Beep Output Channel to identify which Speakers will output Sound

- per bit, 0 means 'Not Output Channel' and 1 means 'Output Channel'

bit0 : FL / bit1 : FR / bit2 : RL / bit3 : RR / bit4 : CTR / bit5 : Surround L /

bit6 : Surround R / bit7 : SWF / bit8 : Headrest L / bit9 : Headrest R / bit10 : Loof L /

bit11 : Loof CTR / bit12 : Loof R / bit13~bit15 : Reserved

- Feedback from ATS_Beep_OutputCh_Select@H_U_MM";
BA_ "GenSigSendType" SG_ 1539 ATS_Beep_OutputCh_State 4;
BA_ "GenSigStartValue" SG_ 1539 ATS_Beep_OutputCh_State 65535;
BA_ "UserSigValidity" SG_ 1539 ATS_Beep_OutputCh_State 1;
BA_REL_ "GenSigTimeoutTime" BU_SG_REL_ CGW_CCU SG_ 1539 ATS_Beep_OutputCh_State 0;
BA_ "Version" SG_ 1539 ATS_Beep_OutputCh_State "21.07.05";
BA_ "Description" SG_ 1539 ATS_BeepFrequencyState "Information for current ATS touch beep frequency

-range : 20Hz ~ 20000Hz";
BA_ "GenSigSendType" SG_ 1539 ATS_BeepFrequencyState 4;
BA_ "GenSigStartValue" SG_ 1539 ATS_BeepFrequencyState 65535;
BA_ "UserSigValidity" SG_ 1539 ATS_BeepFrequencyState 1;
BA_REL_ "GenSigTimeoutTime" BU_SG_REL_ CGW_CCU SG_ 1539 ATS_BeepFrequencyState 0;
BA_ "Version" SG_ 1539 ATS_BeepFrequencyState "21.07.05";
BA_ "Description" SG_ 1539 ATS_BeepVolumeState "Information for Current ATS Beep Sound Volume Setting Status

-range : 0 ~ max

-max : value of AMP_MaxBeep1VolumeState

-Feedback from ATS_BeepVolumeStep@H_U";
BA_ "GenSigSendType" SG_ 1539 ATS_BeepVolumeState 4;
BA_ "GenSigStartValue" SG_ 1539 ATS_BeepVolumeState 255;
BA_ "UserSigValidity" SG_ 1539 ATS_BeepVolumeState 1;
BA_REL_ "GenSigTimeoutTime" BU_SG_REL_ CGW_CCU SG_ 1539 ATS_BeepVolumeState 0;
BA_ "Version" SG_ 1539 ATS_BeepVolumeState "20.03.03";
BA_ "GenMsgCycleTime" BO_ 1540 0;
BA_ "GenSigSendType" SG_ 1540 AMP_MaxVolumeStep 4;
BA_ "GenSigStartValue" SG_ 1540 AMP_MaxVolumeStep 255;
BA_ "UserSigValidity" SG_ 1540 AMP_MaxVolumeStep 1;
BA_REL_ "GenSigTimeoutTime" BU_SG_REL_ CGW_CCU SG_ 1540 AMP_MaxVolumeStep 0;
BA_ "NetworkRequest" SG_ 1540 AMP_MaxVolumeStep 0;
BA_ "Version" SG_ 1540 AMP_MaxVolumeStep "18.12.06";
BA_ "GenSigSendType" SG_ 1540 AMP_MaxFadeStep 4;
BA_ "GenSigStartValue" SG_ 1540 AMP_MaxFadeStep 255;
BA_ "UserSigValidity" SG_ 1540 AMP_MaxFadeStep 1;
BA_REL_ "GenSigTimeoutTime" BU_SG_REL_ CGW_CCU SG_ 1540 AMP_MaxFadeStep 0;
BA_ "NetworkRequest" SG_ 1540 AMP_MaxFadeStep 0;
BA_ "Version" SG_ 1540 AMP_MaxFadeStep "18.12.06";
BA_ "GenSigSendType" SG_ 1540 AMP_MaxBassStep 4;
BA_ "GenSigStartValue" SG_ 1540 AMP_MaxBassStep 255;
BA_ "UserSigValidity" SG_ 1540 AMP_MaxBassStep 1;
BA_REL_ "GenSigTimeoutTime" BU_SG_REL_ CGW_CCU SG_ 1540 AMP_MaxBassStep 0;
BA_ "NetworkRequest" SG_ 1540 AMP_MaxBassStep 0;
BA_ "Version" SG_ 1540 AMP_MaxBassStep "18.12.06";
BA_ "GenSigSendType" SG_ 1540 AMP_MaxMidStep 4;
BA_ "GenSigStartValue" SG_ 1540 AMP_MaxMidStep 255;
BA_ "UserSigValidity" SG_ 1540 AMP_MaxMidStep 1;
BA_REL_ "GenSigTimeoutTime" BU_SG_REL_ CGW_CCU SG_ 1540 AMP_MaxMidStep 0;
BA_ "NetworkRequest" SG_ 1540 AMP_MaxMidStep 0;
BA_ "Version" SG_ 1540 AMP_MaxMidStep "18.12.06";
BA_ "GenSigSendType" SG_ 1540 AMP_MaxTrebleStep 4;
BA_ "GenSigStartValue" SG_ 1540 AMP_MaxTrebleStep 255;
BA_ "UserSigValidity" SG_ 1540 AMP_MaxTrebleStep 1;
BA_REL_ "GenSigTimeoutTime" BU_SG_REL_ CGW_CCU SG_ 1540 AMP_MaxTrebleStep 0;
BA_ "NetworkRequest" SG_ 1540 AMP_MaxTrebleStep 0;
BA_ "Version" SG_ 1540 AMP_MaxTrebleStep "18.12.06";
BA_ "GenSigSendType" SG_ 1540 AMP_MaxBalanceStep 4;
BA_ "GenSigStartValue" SG_ 1540 AMP_MaxBalanceStep 255;
BA_ "UserSigValidity" SG_ 1540 AMP_MaxBalanceStep 1;
BA_REL_ "GenSigTimeoutTime" BU_SG_REL_ CGW_CCU SG_ 1540 AMP_MaxBalanceStep 0;
BA_ "NetworkRequest" SG_ 1540 AMP_MaxBalanceStep 0;
BA_ "Version" SG_ 1540 AMP_MaxBalanceStep "18.12.06";
BA_ "GenMsgCycleTime" BO_ 1542 0;
BA_ "GenSigSendType" SG_ 1542 AMP_MaxBeep1VolumeState 4;
BA_ "GenSigStartValue" SG_ 1542 AMP_MaxBeep1VolumeState 255;
BA_ "UserSigValidity" SG_ 1542 AMP_MaxBeep1VolumeState 1;
BA_REL_ "GenSigTimeoutTime" BU_SG_REL_ CGW_CCU SG_ 1542 AMP_MaxBeep1VolumeState 0;
BA_ "NetworkRequest" SG_ 1542 AMP_MaxBeep1VolumeState 0;
BA_ "Version" SG_ 1542 AMP_MaxBeep1VolumeState "18.12.06";
BA_ "Description" SG_ 1542 AMP_CLU_InfoVolumeState "Information for Current cluster info volume Setting Status

-range : 0 ~ 0xFE

-Feedback from AMP_CLU_InfoVolumeStep @H_U";
BA_ "GenSigSendType" SG_ 1542 AMP_CLU_InfoVolumeState 4;
BA_ "GenSigStartValue" SG_ 1542 AMP_CLU_InfoVolumeState 255;
BA_ "UserSigValidity" SG_ 1542 AMP_CLU_InfoVolumeState 1;
BA_REL_ "GenSigTimeoutTime" BU_SG_REL_ CGW_CCU SG_ 1542 AMP_CLU_InfoVolumeState 0;
BA_ "Version" SG_ 1542 AMP_CLU_InfoVolumeState "21.05.02";
BA_ "Description" SG_ 1542 AMP_CLUinfo_OutputCh_State "Command for Set cluster info sound Output Channel to identify which Speakers will output Sound

- per bit, 0 means 'Not Output Channel' and 1 means 'Output Channel'

bit0 : FL / bit1 : FR / bit2 : RL / bit3 : RR / bit4 : CTR / bit5 : Surround L /

bit6 : Surround R / bit7 : SWF / bit8 : Headrest L / bit9 : Headrest R / bit10 : Loof L /

bit11 : Loof CTR / bit12 : Loof R / bit13~bit15 : Reserved

- Feedback from AMP_CLUinfo_OutputCh_Select @H_U_MM";
BA_ "GenSigSendType" SG_ 1542 AMP_CLUinfo_OutputCh_State 4;
BA_ "GenSigStartValue" SG_ 1542 AMP_CLUinfo_OutputCh_State 65535;
BA_ "UserSigValidity" SG_ 1542 AMP_CLUinfo_OutputCh_State 1;
BA_REL_ "GenSigTimeoutTime" BU_SG_REL_ CGW_CCU SG_ 1542 AMP_CLUinfo_OutputCh_State 0;
BA_ "Version" SG_ 1542 AMP_CLUinfo_OutputCh_State "21.05.02";
BA_ "Description" SG_ 1542 AMP_ADASVolMasterGainState "Information for Current ADAS warning sound Volume Setting Status

-range : 0 ~ 0xFE

-Feedback from AMP_ADASVolMasterGain @H_U";
BA_ "GenSigSendType" SG_ 1542 AMP_ADASVolMasterGainState 4;
BA_ "GenSigStartValue" SG_ 1542 AMP_ADASVolMasterGainState 255;
BA_ "UserSigValidity" SG_ 1542 AMP_ADASVolMasterGainState 1;
BA_REL_ "GenSigTimeoutTime" BU_SG_REL_ CGW_CCU SG_ 1542 AMP_ADASVolMasterGainState 0;
BA_ "Version" SG_ 1542 AMP_ADASVolMasterGainState "21.05.02";
BA_ "Description" SG_ 1542 AMP_Beep1FrequencyState "Information for current AVN touch beep frequency

-range : 20 Hz ~ 20000 Hz";
BA_ "GenSigSendType" SG_ 1542 AMP_Beep1FrequencyState 4;
BA_ "GenSigStartValue" SG_ 1542 AMP_Beep1FrequencyState 65535;
BA_ "UserSigValidity" SG_ 1542 AMP_Beep1FrequencyState 1;
BA_REL_ "GenSigTimeoutTime" BU_SG_REL_ CGW_CCU SG_ 1542 AMP_Beep1FrequencyState 0;
BA_ "Version" SG_ 1542 AMP_Beep1FrequencyState "21.07.05";
BA_ "GenMsgCycleTime" BO_ 1543 0;
BA_ "Description" SG_ 1543 AMP_WalkieTalkieVolumeState "Feedback signal for WalkieTalkie Mode Volume State";
BA_ "GenSigSendType" SG_ 1543 AMP_WalkieTalkieVolumeState 4;
BA_ "GenSigStartValue" SG_ 1543 AMP_WalkieTalkieVolumeState 255;
BA_ "UserSigValidity" SG_ 1543 AMP_WalkieTalkieVolumeState 1;
BA_REL_ "GenSigTimeoutTime" BU_SG_REL_ CGW_CCU SG_ 1543 AMP_WalkieTalkieVolumeState 0;
BA_ "Version" SG_ 1543 AMP_WalkieTalkieVolumeState "21.07.04";
BA_ "Description" SG_ 1543 AMP_WalkieTalkie_OutputCh_State "Command for Set WalkieTalkie Output Channel to identify which Speakers will output Sound

- per bit, 0 means 'Not Output Channel' and 1 means 'Output Channel'

bit0 : FL / bit1 : FR / bit2 : RL / bit3 : RR / bit4 : CTR / bit5 : Surround L /

bit6 : Surround R / bit7 : SWF / bit8 : Headrest L / bit9 : Headrest R / bit10 : Loof L /

bit11 : Loof CTR / bit12 : Loof R / bit13~bit15 : Reserved

- Feedback from AMP_WalkieTalkie_OutputCh_Select@H_U_MM";
BA_ "GenSigSendType" SG_ 1543 AMP_WalkieTalkie_OutputCh_State 4;
BA_ "UserSigValidity" SG_ 1543 AMP_WalkieTalkie_OutputCh_State 1;
BA_REL_ "GenSigTimeoutTime" BU_SG_REL_ CGW_CCU SG_ 1543 AMP_WalkieTalkie_OutputCh_State 0;
BA_ "Version" SG_ 1543 AMP_WalkieTalkie_OutputCh_State "21.07.04";
BA_ "GenMsgCycleTime" BO_ 1545 0;
BA_ "GenSigSendType" SG_ 1545 AMP_Beep1VolumeState 4;
BA_ "GenSigStartValue" SG_ 1545 AMP_Beep1VolumeState 255;
BA_ "UserSigValidity" SG_ 1545 AMP_Beep1VolumeState 1;
BA_REL_ "GenSigTimeoutTime" BU_SG_REL_ CGW_CCU SG_ 1545 AMP_Beep1VolumeState 0;
BA_ "NetworkRequest" SG_ 1545 AMP_Beep1VolumeState 0;
BA_ "Version" SG_ 1545 AMP_Beep1VolumeState "18.12.06";
BA_ "Description" SG_ 1545 AMP_Analog_OutputCh_State "Command for Set Analog Output Channel to identify which Speakers will output Sound

- per bit, 0 means 'Not Output Channel' and 1 means 'Output Channel'

bit0 : FL / bit1 : FR / bit2 : RL / bit3 : RR / bit4 : CTR / bit5 : Surround L /

bit6 : Surround R / bit7 : SWF / bit8 : Headrest L / bit9 : Headrest R / bit10 : Loof L /

bit11 : Loof CTR / bit12 : Loof R / bit13~bit15 : Reserved

- Feedback from AMP_Analog_OutputCh_Select@H_U_MM";
BA_ "GenSigSendType" SG_ 1545 AMP_Analog_OutputCh_State 4;
BA_ "UserSigValidity" SG_ 1545 AMP_Analog_OutputCh_State 1;
BA_REL_ "GenSigTimeoutTime" BU_SG_REL_ CGW_CCU SG_ 1545 AMP_Analog_OutputCh_State 0;
BA_ "Version" SG_ 1545 AMP_Analog_OutputCh_State "20.01.01";
BA_ "Description" SG_ 1545 AMP_Beep1_OutputCh_State "Command for Set Beep1 Output Channel to identify which Speakers will output Sound

- per bit, 0 means 'Not Output Channel' and 1 means 'Output Channel'

bit0 : FL / bit1 : FR / bit2 : RL / bit3 : RR / bit4 : CTR / bit5 : Surround L /

bit6 : Surround R / bit7 : SWF / bit8 : Headrest L / bit9 : Headrest R / bit10 : Loof L /

bit11 : Loof CTR / bit12 : Loof R / bit13~bit15 : Reserved

- Feedback from AMP_Beep1_OutputCh_Select@H_U_MM";
BA_ "GenSigSendType" SG_ 1545 AMP_Beep1_OutputCh_State 4;
BA_ "GenSigStartValue" SG_ 1545 AMP_Beep1_OutputCh_State 65535;
BA_ "UserSigValidity" SG_ 1545 AMP_Beep1_OutputCh_State 1;
BA_REL_ "GenSigTimeoutTime" BU_SG_REL_ CGW_CCU SG_ 1545 AMP_Beep1_OutputCh_State 0;
BA_ "Version" SG_ 1545 AMP_Beep1_OutputCh_State "19.12.08";
BA_ "Description" SG_ 1545 AMP_Beep1KBDVolumeState "Information for Current AVN keyboard Beep Sound Volume Setting Status

-range : 0 ~ max

-max : value of AMP_MaxBeep1VolumeState

-Feedback from AMP_Beep1KBDVolumeStep@H_U";
BA_ "GenSigSendType" SG_ 1545 AMP_Beep1KBDVolumeState 4;
BA_ "GenSigStartValue" SG_ 1545 AMP_Beep1KBDVolumeState 255;
BA_ "UserSigValidity" SG_ 1545 AMP_Beep1KBDVolumeState 1;
BA_REL_ "GenSigTimeoutTime" BU_SG_REL_ CGW_CCU SG_ 1545 AMP_Beep1KBDVolumeState 0;
BA_ "Version" SG_ 1545 AMP_Beep1KBDVolumeState "20.06.01";
BA_ "Description" SG_ 1545 AMP_SPDIF_OutputCh_State "Command for Set SPDIF Output Channel to identify which Speakers will output Sound

- per bit, 0 means 'Not Output Channel' and 1 means 'Output Channel'

bit0 : FL / bit1 : FR / bit2 : RL / bit3 : RR / bit4 : CTR / bit5 : Surround L /

bit6 : Surround R / bit7 : SWF / bit8 : Headrest L / bit9 : Headrest R / bit10 : Loof L /

bit11 : Loof CTR / bit12 : Loof R / bit13~bit15 : Reserved

- Feedback from AMP_SPDIF_OutputCh_Select@H_U_MM";
BA_ "GenSigSendType" SG_ 1545 AMP_SPDIF_OutputCh_State 4;
BA_ "GenSigStartValue" SG_ 1545 AMP_SPDIF_OutputCh_State 255;
BA_ "UserSigValidity" SG_ 1545 AMP_SPDIF_OutputCh_State 1;
BA_REL_ "GenSigTimeoutTime" BU_SG_REL_ CGW_CCU SG_ 1545 AMP_SPDIF_OutputCh_State 0;
BA_ "Version" SG_ 1545 AMP_SPDIF_OutputCh_State "19.12.02";
BA_ "GenMsgSendType" BO_ 1552 0;
BA_ "GenMsgCycleTime" BO_ 1552 2000;
BA_ "GenSigSendType" SG_ 1552 AMP_ToneScapeXSetting 4;
BA_ "GenSigStartValue" SG_ 1552 AMP_ToneScapeXSetting 255;
BA_ "UserSigValidity" SG_ 1552 AMP_ToneScapeXSetting 1;
BA_REL_ "GenSigTimeoutTime" BU_SG_REL_ CGW_CCU SG_ 1552 AMP_ToneScapeXSetting 5000;
BA_ "NetworkRequest" SG_ 1552 AMP_ToneScapeXSetting 0;
BA_ "Version" SG_ 1552 AMP_ToneScapeXSetting "20.02.04";
BA_ "GenSigSendType" SG_ 1552 AMP_ToneScapeYSetting 4;
BA_ "GenSigStartValue" SG_ 1552 AMP_ToneScapeYSetting 255;
BA_ "UserSigValidity" SG_ 1552 AMP_ToneScapeYSetting 1;
BA_REL_ "GenSigTimeoutTime" BU_SG_REL_ CGW_CCU SG_ 1552 AMP_ToneScapeYSetting 5000;
BA_ "NetworkRequest" SG_ 1552 AMP_ToneScapeYSetting 0;
BA_ "Version" SG_ 1552 AMP_ToneScapeYSetting "20.02.04";
BA_ "GenSigSendType" SG_ 1552 AMP_ToneScapeZSetting 4;
BA_ "GenSigStartValue" SG_ 1552 AMP_ToneScapeZSetting 255;
BA_ "UserSigValidity" SG_ 1552 AMP_ToneScapeZSetting 1;
BA_REL_ "GenSigTimeoutTime" BU_SG_REL_ CGW_CCU SG_ 1552 AMP_ToneScapeZSetting 5000;
BA_ "NetworkRequest" SG_ 1552 AMP_ToneScapeZSetting 0;
BA_ "Version" SG_ 1552 AMP_ToneScapeZSetting "20.02.04";
BA_ "Description" SG_ 1552 AMP_SiriModeState "The signal is the feedback signal of Siri Mode On/Off state";
BA_ "GenSigSendType" SG_ 1552 AMP_SiriModeState 4;
BA_ "GenSigStartValue" SG_ 1552 AMP_SiriModeState 3;
BA_ "UserSigValidity" SG_ 1552 AMP_SiriModeState 1;
BA_REL_ "GenSigTimeoutTime" BU_SG_REL_ CGW_CCU SG_ 1552 AMP_SiriModeState 5000;
BA_ "Version" SG_ 1552 AMP_SiriModeState "20.07.00";
BA_ "Description" SG_ 1552 AMP_SiriVolumeState "Feedback signal for Siri Mode Volume State";
BA_ "GenSigSendType" SG_ 1552 AMP_SiriVolumeState 4;
BA_ "GenSigStartValue" SG_ 1552 AMP_SiriVolumeState 255;
BA_ "UserSigValidity" SG_ 1552 AMP_SiriVolumeState 1;
BA_REL_ "GenSigTimeoutTime" BU_SG_REL_ CGW_CCU SG_ 1552 AMP_SiriVolumeState 5000;
BA_ "Version" SG_ 1552 AMP_SiriVolumeState "20.07.00";
BA_ "GenMsgSendType" BO_ 1553 0;
BA_ "GenSigSendType" SG_ 1553 AMP_Binary1Ver 4;
BA_ "GenSigStartValue" SG_ 1553 AMP_Binary1Ver 255;
BA_ "UserSigValidity" SG_ 1553 AMP_Binary1Ver 1;
BA_REL_ "GenSigTimeoutTime" BU_SG_REL_ CGW_CCU SG_ 1553 AMP_Binary1Ver 1500;
BA_ "RoutingFactor" SG_ 1553 AMP_Binary1Ver 0;
BA_ "Version" SG_ 1553 AMP_Binary1Ver "20.07.04";
BA_ "GenSigSendType" SG_ 1553 AMP_Binary3Ver 4;
BA_ "GenSigStartValue" SG_ 1553 AMP_Binary3Ver 255;
BA_ "UserSigValidity" SG_ 1553 AMP_Binary3Ver 1;
BA_REL_ "GenSigTimeoutTime" BU_SG_REL_ CGW_CCU SG_ 1553 AMP_Binary3Ver 1500;
BA_ "RoutingFactor" SG_ 1553 AMP_Binary3Ver 0;
BA_ "Version" SG_ 1553 AMP_Binary3Ver "20.07.04";
BA_ "GenSigSendType" SG_ 1553 AMP_Binary4Ver 4;
BA_ "GenSigStartValue" SG_ 1553 AMP_Binary4Ver 255;
BA_ "UserSigValidity" SG_ 1553 AMP_Binary4Ver 1;
BA_REL_ "GenSigTimeoutTime" BU_SG_REL_ CGW_CCU SG_ 1553 AMP_Binary4Ver 1500;
BA_ "RoutingFactor" SG_ 1553 AMP_Binary4Ver 0;
BA_ "Version" SG_ 1553 AMP_Binary4Ver "20.07.04";
BA_ "GenSigSendType" SG_ 1553 AMP_Binary5Ver 4;
BA_ "GenSigStartValue" SG_ 1553 AMP_Binary5Ver 255;
BA_ "UserSigValidity" SG_ 1553 AMP_Binary5Ver 1;
BA_REL_ "GenSigTimeoutTime" BU_SG_REL_ CGW_CCU SG_ 1553 AMP_Binary5Ver 1500;
BA_ "RoutingFactor" SG_ 1553 AMP_Binary5Ver 0;
BA_ "Version" SG_ 1553 AMP_Binary5Ver "20.07.05";
BA_ "GenSigSendType" SG_ 1553 AMP_Binary6Ver 4;
BA_ "GenSigStartValue" SG_ 1553 AMP_Binary6Ver 255;
BA_ "UserSigValidity" SG_ 1553 AMP_Binary6Ver 1;
BA_REL_ "GenSigTimeoutTime" BU_SG_REL_ CGW_CCU SG_ 1553 AMP_Binary6Ver 1500;
BA_ "RoutingFactor" SG_ 1553 AMP_Binary6Ver 0;
BA_ "Version" SG_ 1553 AMP_Binary6Ver "20.07.05";
BA_ "Description" SG_ 1553 AMP_WalkieTalkieModeState "The signal is the feedback signal of WalkieTalkie Mode On/Off state";
BA_ "GenSigSendType" SG_ 1553 AMP_WalkieTalkieModeState 4;
BA_ "GenSigStartValue" SG_ 1553 AMP_WalkieTalkieModeState 3;
BA_ "UserSigValidity" SG_ 1553 AMP_WalkieTalkieModeState 1;
BA_REL_ "GenSigTimeoutTime" BU_SG_REL_ CGW_CCU SG_ 1553 AMP_WalkieTalkieModeState 1500;
BA_ "RoutingFactor" SG_ 1553 AMP_WalkieTalkieModeState 0;
BA_ "Version" SG_ 1553 AMP_WalkieTalkieModeState "21.07.04";
BA_ "GenSigSendType" SG_ 1553 AMP_Binary2Ver 4;
BA_ "GenSigStartValue" SG_ 1553 AMP_Binary2Ver 255;
BA_ "UserSigValidity" SG_ 1553 AMP_Binary2Ver 1;
BA_REL_ "GenSigTimeoutTime" BU_SG_REL_ CGW_CCU SG_ 1553 AMP_Binary2Ver 1500;
BA_ "RoutingFactor" SG_ 1553 AMP_Binary2Ver 0;
BA_ "Version" SG_ 1553 AMP_Binary2Ver "20.07.04";
BA_ "GenMsgSendType" BO_ 1546 0;
BA_ "GenMsgCycleTimeFast" BO_ 1546 0;
BA_ "GenMsgNrOfRepetition" BO_ 1546 0;
BA_ "Description" SG_ 1546 AMP_SupportBeepVolumeControl "Does amp support Dynamic Speed Compensation mode?";
BA_ "GenSigStartValue" SG_ 1546 AMP_SupportBeepVolumeControl 3;
BA_ "UserSigValidity" SG_ 1546 AMP_SupportBeepVolumeControl 1;
BA_REL_ "GenSigTimeoutTime" BU_SG_REL_ ATS SG_ 1546 AMP_SupportBeepVolumeControl 1500;
BA_REL_ "GenSigTimeoutTime" BU_SG_REL_ CGW_CCU SG_ 1546 AMP_SupportBeepVolumeControl 1500;
BA_ "Version" SG_ 1546 AMP_SupportBeepVolumeControl "18.12.06";
BA_ "Description" SG_ 1546 AMP_SupportESEVMode "Dose amp support CenterPoint mode?";
BA_ "GenSigStartValue" SG_ 1546 AMP_SupportESEVMode 3;
BA_ "UserSigValidity" SG_ 1546 AMP_SupportESEVMode 1;
BA_REL_ "GenSigTimeoutTime" BU_SG_REL_ CGW_CCU SG_ 1546 AMP_SupportESEVMode 1500;
BA_ "NetworkRequest" SG_ 1546 AMP_SupportESEVMode 0;
BA_ "Version" SG_ 1546 AMP_SupportESEVMode "20.03.06";
BA_ "GenSigStartValue" SG_ 1546 AMP_SupportANCMode 3;
BA_ "UserSigValidity" SG_ 1546 AMP_SupportANCMode 1;
BA_REL_ "GenSigTimeoutTime" BU_SG_REL_ CGW_CCU SG_ 1546 AMP_SupportANCMode 1500;
BA_ "Version" SG_ 1546 AMP_SupportANCMode "18.12.06";
BA_ "GenSigStartValue" SG_ 1546 AMP_MakerID 255;
BA_ "UserSigValidity" SG_ 1546 AMP_MakerID 1;
BA_REL_ "GenSigTimeoutTime" BU_SG_REL_ CGW_CCU SG_ 1546 AMP_MakerID 1500;
BA_ "Version" SG_ 1546 AMP_MakerID "19.12.00";
BA_ "GenSigStartValue" SG_ 1546 AMP_SupportQLS 3;
BA_ "UserSigValidity" SG_ 1546 AMP_SupportQLS 1;
BA_REL_ "GenSigTimeoutTime" BU_SG_REL_ CGW_CCU SG_ 1546 AMP_SupportQLS 1500;
BA_ "Version" SG_ 1546 AMP_SupportQLS "18.12.06";
BA_ "Description" SG_ 1546 AMP_SupportASDMode "Does amp support CenterPoint mode?";
BA_ "GenSigStartValue" SG_ 1546 AMP_SupportASDMode 3;
BA_ "UserSigValidity" SG_ 1546 AMP_SupportASDMode 1;
BA_REL_ "GenSigTimeoutTime" BU_SG_REL_ CGW_CCU SG_ 1546 AMP_SupportASDMode 1500;
BA_ "Version" SG_ 1546 AMP_SupportASDMode "18.12.06";
BA_ "GenSigStartValue" SG_ 1546 AMP_Support_ElecSound 3;
BA_ "UserSigValidity" SG_ 1546 AMP_Support_ElecSound 1;
BA_REL_ "GenSigTimeoutTime" BU_SG_REL_ CGW_CCU SG_ 1546 AMP_Support_ElecSound 1500;
BA_ "NetworkRequest" SG_ 1546 AMP_Support_ElecSound 0;
BA_ "Version" SG_ 1546 AMP_Support_ElecSound "18.12.06";
BA_ "GenMsgSendType" BO_ 1547 0;
BA_ "GenMsgCycleTimeFast" BO_ 1547 0;
BA_ "GenMsgNrOfRepetition" BO_ 1547 0;
BA_ "GenMsgStartDelayTime" BO_ 1547 10;
BA_ "Description" SG_ 1547 AMP_SupportHDAudio "Inform whether AMP support HD Audio";
BA_ "GenSigStartValue" SG_ 1547 AMP_SupportHDAudio 3;
BA_ "UserSigValidity" SG_ 1547 AMP_SupportHDAudio 1;
BA_REL_ "GenSigTimeoutTime" BU_SG_REL_ CGW_CCU SG_ 1547 AMP_SupportHDAudio 1500;
BA_ "NetworkRequest" SG_ 1547 AMP_SupportHDAudio 0;
BA_ "Version" SG_ 1547 AMP_SupportHDAudio "19.08.08";
BA_ "Description" SG_ 1547 AMP_SupportVirtualVenue "Inform whether AMP support VV";
BA_ "GenSigStartValue" SG_ 1547 AMP_SupportVirtualVenue 3;
BA_ "UserSigValidity" SG_ 1547 AMP_SupportVirtualVenue 1;
BA_REL_ "GenSigTimeoutTime" BU_SG_REL_ CGW_CCU SG_ 1547 AMP_SupportVirtualVenue 1500;
BA_ "NetworkRequest" SG_ 1547 AMP_SupportVirtualVenue 0;
BA_ "Version" SG_ 1547 AMP_SupportVirtualVenue "19.08.08";
BA_ "Description" SG_ 1547 AMP_SupportQLI "Inform whether AMP support QLI";
BA_ "GenSigStartValue" SG_ 1547 AMP_SupportQLI 3;
BA_ "UserSigValidity" SG_ 1547 AMP_SupportQLI 1;
BA_REL_ "GenSigTimeoutTime" BU_SG_REL_ CGW_CCU SG_ 1547 AMP_SupportQLI 1500;
BA_ "NetworkRequest" SG_ 1547 AMP_SupportQLI 0;
BA_ "Version" SG_ 1547 AMP_SupportQLI "19.08.08";
BA_ "Description" SG_ 1547 AMP_SupportWrnPromptMode "This signal is used for setting UI menu of Warning Prompt Mode";
BA_ "GenSigStartValue" SG_ 1547 AMP_SupportWrnPromptMode 3;
BA_ "UserSigValidity" SG_ 1547 AMP_SupportWrnPromptMode 0;
BA_REL_ "GenSigTimeoutTime" BU_SG_REL_ CGW_CCU SG_ 1547 AMP_SupportWrnPromptMode 1500;
BA_ "Version" SG_ 1547 AMP_SupportWrnPromptMode "19.02.07";
BA_ "Description" SG_ 1547 AMP_SupportKBDBeep "Information for AMP support Keyboard Beep";
BA_ "GenSigStartValue" SG_ 1547 AMP_SupportKBDBeep 3;
BA_ "UserSigValidity" SG_ 1547 AMP_SupportKBDBeep 1;
BA_REL_ "GenSigTimeoutTime" BU_SG_REL_ CGW_CCU SG_ 1547 AMP_SupportKBDBeep 1500;
BA_ "Version" SG_ 1547 AMP_SupportKBDBeep "20.08.00";
BA_ "Description" SG_ 1547 AMP_SupportDriverMode "Inform whether AMP support Driver mode";
BA_ "GenSigStartValue" SG_ 1547 AMP_SupportDriverMode 3;
BA_ "UserSigValidity" SG_ 1547 AMP_SupportDriverMode 1;
BA_REL_ "GenSigTimeoutTime" BU_SG_REL_ CGW_CCU SG_ 1547 AMP_SupportDriverMode 1500;
BA_ "NetworkRequest" SG_ 1547 AMP_SupportDriverMode 0;
BA_ "Version" SG_ 1547 AMP_SupportDriverMode "19.08.08";
BA_ "Description" SG_ 1547 AMP_Support_SDVC "SDVC FUNCTION APPLING";
BA_ "GenSigStartValue" SG_ 1547 AMP_Support_SDVC 3;
BA_ "UserSigValidity" SG_ 1547 AMP_Support_SDVC 1;
BA_REL_ "GenSigTimeoutTime" BU_SG_REL_ CGW_CCU SG_ 1547 AMP_Support_SDVC 1500;
BA_ "Version" SG_ 1547 AMP_Support_SDVC "19.01.04";
BA_ "Description" SG_ 1547 AMP_Support_CLU_InfoVolume10 "Inform whether AMP support For Cluster info sound volume 10 step";
BA_ "GenSigStartValue" SG_ 1547 AMP_Support_CLU_InfoVolume10 3;
BA_ "UserSigValidity" SG_ 1547 AMP_Support_CLU_InfoVolume10 1;
BA_REL_ "GenSigTimeoutTime" BU_SG_REL_ CGW_CCU SG_ 1547 AMP_Support_CLU_InfoVolume10 1500;
BA_ "NetworkRequest" SG_ 1547 AMP_Support_CLU_InfoVolume10 0;
BA_ "Version" SG_ 1547 AMP_Support_CLU_InfoVolume10 "21.05.02";
BA_ "Description" SG_ 1547 AMP_Support_ADASVolume10 "Inform whether AMP support for ADAS warning sound volume 10 step";
BA_ "GenSigStartValue" SG_ 1547 AMP_Support_ADASVolume10 3;
BA_ "UserSigValidity" SG_ 1547 AMP_Support_ADASVolume10 1;
BA_REL_ "GenSigTimeoutTime" BU_SG_REL_ CGW_CCU SG_ 1547 AMP_Support_ADASVolume10 1500;
BA_ "NetworkRequest" SG_ 1547 AMP_Support_ADASVolume10 0;
BA_ "Version" SG_ 1547 AMP_Support_ADASVolume10 "21.05.02";
BA_ "Description" SG_ 1547 AMP_Support_BeepVolume10 "Inform whether AMP support for beep volume 10 step";
BA_ "GenSigStartValue" SG_ 1547 AMP_Support_BeepVolume10 3;
BA_ "UserSigValidity" SG_ 1547 AMP_Support_BeepVolume10 1;
BA_REL_ "GenSigTimeoutTime" BU_SG_REL_ CGW_CCU SG_ 1547 AMP_Support_BeepVolume10 1500;
BA_ "NetworkRequest" SG_ 1547 AMP_Support_BeepVolume10 0;
BA_ "Version" SG_ 1547 AMP_Support_BeepVolume10 "21.05.02";
BA_ "Description" SG_ 1547 AMP_Support_AlarmVolume10 "Inform whether AMP support for Alarm volume 10 step";
BA_ "GenSigStartValue" SG_ 1547 AMP_Support_AlarmVolume10 3;
BA_ "UserSigValidity" SG_ 1547 AMP_Support_AlarmVolume10 1;
BA_REL_ "GenSigTimeoutTime" BU_SG_REL_ CGW_CCU SG_ 1547 AMP_Support_AlarmVolume10 1500;
BA_ "NetworkRequest" SG_ 1547 AMP_Support_AlarmVolume10 0;
BA_ "Version" SG_ 1547 AMP_Support_AlarmVolume10 "21.05.02";
BA_ "Description" SG_ 1547 AMP_Support_Volume35 "Inform whether AMP support for change from 75 step to 35 step";
BA_ "GenSigStartValue" SG_ 1547 AMP_Support_Volume35 3;
BA_ "UserSigValidity" SG_ 1547 AMP_Support_Volume35 1;
BA_REL_ "GenSigTimeoutTime" BU_SG_REL_ CGW_CCU SG_ 1547 AMP_Support_Volume35 1500;
BA_ "NetworkRequest" SG_ 1547 AMP_Support_Volume35 0;
BA_ "Version" SG_ 1547 AMP_Support_Volume35 "21.05.02";
BA_ "GenSigStartValue" SG_ 1547 AMP_SupportRANC 3;
BA_ "UserSigValidity" SG_ 1547 AMP_SupportRANC 1;
BA_REL_ "GenSigTimeoutTime" BU_SG_REL_ CGW_CCU SG_ 1547 AMP_SupportRANC 1500;
BA_ "Version" SG_ 1547 AMP_SupportRANC "18.12.06";
BA_ "GenMsgSendType" BO_ 591 0;
BA_ "Description" SG_ 591 ATS_RLStSldFwdBtn "후석 LH 슬라이딩 전방 이동";
BA_ "GenSigSendType" SG_ 591 ATS_RLStSldFwdBtn 4;
BA_ "UserSigValidity" SG_ 591 ATS_RLStSldFwdBtn 3;
BA_REL_ "GenSigTimeoutTime" BU_SG_REL_ RLPSM SG_ 591 ATS_RLStSldFwdBtn 1500;
BA_ "NetworkRequest" SG_ 591 ATS_RLStSldFwdBtn 0;
BA_ "NetworkRequestHoldingTime" SG_ 591 ATS_RLStSldFwdBtn 5000;
BA_ "Version" SG_ 591 ATS_RLStSldFwdBtn "19.09.02";
BA_ "Description" SG_ 591 ATS_RLStSldBwdBtn "후석 LH 슬라이딩 후방 이동";
BA_ "GenSigSendType" SG_ 591 ATS_RLStSldBwdBtn 4;
BA_ "UserSigValidity" SG_ 591 ATS_RLStSldBwdBtn 3;
BA_REL_ "GenSigTimeoutTime" BU_SG_REL_ RLPSM SG_ 591 ATS_RLStSldBwdBtn 1500;
BA_ "NetworkRequest" SG_ 591 ATS_RLStSldBwdBtn 0;
BA_ "NetworkRequestHoldingTime" SG_ 591 ATS_RLStSldBwdBtn 5000;
BA_ "Version" SG_ 591 ATS_RLStSldBwdBtn "19.09.02";
BA_ "Description" SG_ 591 ATS_RLStRclFwdBtn "후석 LH 리클라이닝 전방 이동";
BA_ "GenSigSendType" SG_ 591 ATS_RLStRclFwdBtn 4;
BA_ "UserSigValidity" SG_ 591 ATS_RLStRclFwdBtn 3;
BA_REL_ "GenSigTimeoutTime" BU_SG_REL_ RLPSM SG_ 591 ATS_RLStRclFwdBtn 1500;
BA_ "NetworkRequest" SG_ 591 ATS_RLStRclFwdBtn 0;
BA_ "NetworkRequestHoldingTime" SG_ 591 ATS_RLStRclFwdBtn 5000;
BA_ "Version" SG_ 591 ATS_RLStRclFwdBtn "19.09.02";
BA_ "Description" SG_ 591 ATS_RLStRclBwdBtn "후석 LH 리클라이닝 후방 이동";
BA_ "GenSigSendType" SG_ 591 ATS_RLStRclBwdBtn 4;
BA_ "UserSigValidity" SG_ 591 ATS_RLStRclBwdBtn 3;
BA_REL_ "GenSigTimeoutTime" BU_SG_REL_ RLPSM SG_ 591 ATS_RLStRclBwdBtn 1500;
BA_ "NetworkRequest" SG_ 591 ATS_RLStRclBwdBtn 0;
BA_ "NetworkRequestHoldingTime" SG_ 591 ATS_RLStRclBwdBtn 5000;
BA_ "Version" SG_ 591 ATS_RLStRclBwdBtn "19.09.02";
BA_ "Description" SG_ 591 ATS_RLStTltUpBtn "후석 LH 틸트 업 이동";
BA_ "GenSigSendType" SG_ 591 ATS_RLStTltUpBtn 4;
BA_ "UserSigValidity" SG_ 591 ATS_RLStTltUpBtn 3;
BA_REL_ "GenSigTimeoutTime" BU_SG_REL_ RLPSM SG_ 591 ATS_RLStTltUpBtn 1500;
BA_ "NetworkRequest" SG_ 591 ATS_RLStTltUpBtn 0;
BA_ "NetworkRequestHoldingTime" SG_ 591 ATS_RLStTltUpBtn 5000;
BA_ "Version" SG_ 591 ATS_RLStTltUpBtn "19.09.02";
BA_ "Description" SG_ 591 ATS_RLStTltDnBtn "후석 LH 틸트 다운 이동";
BA_ "GenSigSendType" SG_ 591 ATS_RLStTltDnBtn 4;
BA_ "UserSigValidity" SG_ 591 ATS_RLStTltDnBtn 3;
BA_REL_ "GenSigTimeoutTime" BU_SG_REL_ RLPSM SG_ 591 ATS_RLStTltDnBtn 1500;
BA_ "NetworkRequest" SG_ 591 ATS_RLStTltDnBtn 0;
BA_ "NetworkRequestHoldingTime" SG_ 591 ATS_RLStTltDnBtn 5000;
BA_ "Version" SG_ 591 ATS_RLStTltDnBtn "19.09.02";
BA_ "Description" SG_ 591 ATS_RLStHRestUpBtn "후석 LH 헤드레스트 업 이동";
BA_ "GenSigSendType" SG_ 591 ATS_RLStHRestUpBtn 4;
BA_ "UserSigValidity" SG_ 591 ATS_RLStHRestUpBtn 3;
BA_REL_ "GenSigTimeoutTime" BU_SG_REL_ RLPSM SG_ 591 ATS_RLStHRestUpBtn 1500;
BA_ "NetworkRequest" SG_ 591 ATS_RLStHRestUpBtn 0;
BA_ "NetworkRequestHoldingTime" SG_ 591 ATS_RLStHRestUpBtn 5000;
BA_ "Version" SG_ 591 ATS_RLStHRestUpBtn "19.09.02";
BA_ "Description" SG_ 591 ATS_RLStHRestDnBtn "후석 LH 헤드레스트 다운 이동";
BA_ "GenSigSendType" SG_ 591 ATS_RLStHRestDnBtn 4;
BA_ "UserSigValidity" SG_ 591 ATS_RLStHRestDnBtn 3;
BA_REL_ "GenSigTimeoutTime" BU_SG_REL_ RLPSM SG_ 591 ATS_RLStHRestDnBtn 1500;
BA_ "NetworkRequest" SG_ 591 ATS_RLStHRestDnBtn 0;
BA_ "NetworkRequestHoldingTime" SG_ 591 ATS_RLStHRestDnBtn 5000;
BA_ "Version" SG_ 591 ATS_RLStHRestDnBtn "19.09.02";
BA_ "Description" SG_ 591 ATS_RLStHRestFwdBtn "후석 LH 헤드레스트 전방 이동";
BA_ "GenSigSendType" SG_ 591 ATS_RLStHRestFwdBtn 4;
BA_ "UserSigValidity" SG_ 591 ATS_RLStHRestFwdBtn 3;
BA_REL_ "GenSigTimeoutTime" BU_SG_REL_ RLPSM SG_ 591 ATS_RLStHRestFwdBtn 1500;
BA_ "NetworkRequest" SG_ 591 ATS_RLStHRestFwdBtn 0;
BA_ "NetworkRequestHoldingTime" SG_ 591 ATS_RLStHRestFwdBtn 5000;
BA_ "Version" SG_ 591 ATS_RLStHRestFwdBtn "19.09.02";
BA_ "Description" SG_ 591 ATS_RLStHRestBwdBtn "후석 LH 헤드레스트 후방 이동";
BA_ "GenSigSendType" SG_ 591 ATS_RLStHRestBwdBtn 4;
BA_ "UserSigValidity" SG_ 591 ATS_RLStHRestBwdBtn 3;
BA_REL_ "GenSigTimeoutTime" BU_SG_REL_ RLPSM SG_ 591 ATS_RLStHRestBwdBtn 1500;
BA_ "NetworkRequest" SG_ 591 ATS_RLStHRestBwdBtn 0;
BA_ "NetworkRequestHoldingTime" SG_ 591 ATS_RLStHRestBwdBtn 5000;
BA_ "Version" SG_ 591 ATS_RLStHRestBwdBtn "19.09.02";
BA_ "Description" SG_ 591 ATS_RLStLegRestUpBtn "후석 LH 레그레스트 UP";
BA_ "GenSigSendType" SG_ 591 ATS_RLStLegRestUpBtn 4;
BA_ "UserSigValidity" SG_ 591 ATS_RLStLegRestUpBtn 3;
BA_REL_ "GenSigTimeoutTime" BU_SG_REL_ RLPSM SG_ 591 ATS_RLStLegRestUpBtn 1500;
BA_ "NetworkRequest" SG_ 591 ATS_RLStLegRestUpBtn 0;
BA_ "NetworkRequestHoldingTime" SG_ 591 ATS_RLStLegRestUpBtn 5000;
BA_ "Version" SG_ 591 ATS_RLStLegRestUpBtn "19.11.09";
BA_ "Description" SG_ 591 ATS_RLStLegRestDnBtn "후석 LH 레그레스트 DOWN";
BA_ "GenSigSendType" SG_ 591 ATS_RLStLegRestDnBtn 4;
BA_ "UserSigValidity" SG_ 591 ATS_RLStLegRestDnBtn 3;
BA_REL_ "GenSigTimeoutTime" BU_SG_REL_ RLPSM SG_ 591 ATS_RLStLegRestDnBtn 1500;
BA_ "NetworkRequest" SG_ 591 ATS_RLStLegRestDnBtn 0;
BA_ "NetworkRequestHoldingTime" SG_ 591 ATS_RLStLegRestDnBtn 5000;
BA_ "Version" SG_ 591 ATS_RLStLegRestDnBtn "21.06.11";
BA_ "Description" SG_ 591 ATS_RLStLegRestExtUpBtn "후석 LH 레그레스트 EXT";
BA_ "GenSigSendType" SG_ 591 ATS_RLStLegRestExtUpBtn 4;
BA_ "UserSigValidity" SG_ 591 ATS_RLStLegRestExtUpBtn 3;
BA_REL_ "GenSigTimeoutTime" BU_SG_REL_ RLPSM SG_ 591 ATS_RLStLegRestExtUpBtn 1500;
BA_ "NetworkRequest" SG_ 591 ATS_RLStLegRestExtUpBtn 0;
BA_ "NetworkRequestHoldingTime" SG_ 591 ATS_RLStLegRestExtUpBtn 5000;
BA_ "Version" SG_ 591 ATS_RLStLegRestExtUpBtn "19.11.09";
BA_ "Description" SG_ 591 ATS_RLStLegRestExtDnBtn "후석 LH 레그레스트 EXT BWD";
BA_ "GenSigSendType" SG_ 591 ATS_RLStLegRestExtDnBtn 4;
BA_ "UserSigValidity" SG_ 591 ATS_RLStLegRestExtDnBtn 3;
BA_REL_ "GenSigTimeoutTime" BU_SG_REL_ RLPSM SG_ 591 ATS_RLStLegRestExtDnBtn 1500;
BA_ "NetworkRequest" SG_ 591 ATS_RLStLegRestExtDnBtn 0;
BA_ "NetworkRequestHoldingTime" SG_ 591 ATS_RLStLegRestExtDnBtn 5000;
BA_ "Version" SG_ 591 ATS_RLStLegRestExtDnBtn "19.11.09";
BA_ "Description" SG_ 591 ATS_RLStShoulderADJFwdBtn "후석 LH 숄더어져스터 FWD";
BA_ "GenSigSendType" SG_ 591 ATS_RLStShoulderADJFwdBtn 4;
BA_ "UserSigValidity" SG_ 591 ATS_RLStShoulderADJFwdBtn 3;
BA_REL_ "GenSigTimeoutTime" BU_SG_REL_ RLPSM SG_ 591 ATS_RLStShoulderADJFwdBtn 1500;
BA_REL_ "GenSigTimeoutTime" BU_SG_REL_ RRPSM SG_ 591 ATS_RLStShoulderADJFwdBtn 1500;
BA_ "NetworkRequest" SG_ 591 ATS_RLStShoulderADJFwdBtn 0;
BA_ "NetworkRequestHoldingTime" SG_ 591 ATS_RLStShoulderADJFwdBtn 5000;
BA_ "Version" SG_ 591 ATS_RLStShoulderADJFwdBtn "20.03.02";
BA_ "Description" SG_ 591 ATS_RLStShoulderADJBwdBtn "후석 LH 숄더어져스터 BWD";
BA_ "GenSigSendType" SG_ 591 ATS_RLStShoulderADJBwdBtn 4;
BA_ "UserSigValidity" SG_ 591 ATS_RLStShoulderADJBwdBtn 3;
BA_REL_ "GenSigTimeoutTime" BU_SG_REL_ RLPSM SG_ 591 ATS_RLStShoulderADJBwdBtn 1500;
BA_REL_ "GenSigTimeoutTime" BU_SG_REL_ RRPSM SG_ 591 ATS_RLStShoulderADJBwdBtn 1500;
BA_ "NetworkRequest" SG_ 591 ATS_RLStShoulderADJBwdBtn 0;
BA_ "NetworkRequestHoldingTime" SG_ 591 ATS_RLStShoulderADJBwdBtn 5000;
BA_ "Version" SG_ 591 ATS_RLStShoulderADJBwdBtn "20.03.02";
BA_ "GenMsgSendType" BO_ 607 0;
BA_ "Description" SG_ 607 ATS_RRStSldFwdBtn "후석 RH 슬라이딩 전방 이동";
BA_ "GenSigSendType" SG_ 607 ATS_RRStSldFwdBtn 4;
BA_ "UserSigValidity" SG_ 607 ATS_RRStSldFwdBtn 3;
BA_REL_ "GenSigTimeoutTime" BU_SG_REL_ RRPSM SG_ 607 ATS_RRStSldFwdBtn 1500;
BA_ "NetworkRequest" SG_ 607 ATS_RRStSldFwdBtn 0;
BA_ "NetworkRequestHoldingTime" SG_ 607 ATS_RRStSldFwdBtn 5000;
BA_ "Version" SG_ 607 ATS_RRStSldFwdBtn "19.09.02";
BA_ "Description" SG_ 607 ATS_RRStSldBwdBtn "후석 RH 슬라이딩 후방 이동";
BA_ "GenSigSendType" SG_ 607 ATS_RRStSldBwdBtn 4;
BA_ "UserSigValidity" SG_ 607 ATS_RRStSldBwdBtn 3;
BA_REL_ "GenSigTimeoutTime" BU_SG_REL_ RRPSM SG_ 607 ATS_RRStSldBwdBtn 1500;
BA_ "NetworkRequest" SG_ 607 ATS_RRStSldBwdBtn 0;
BA_ "NetworkRequestHoldingTime" SG_ 607 ATS_RRStSldBwdBtn 5000;
BA_ "Version" SG_ 607 ATS_RRStSldBwdBtn "19.09.02";
BA_ "Description" SG_ 607 ATS_RRStRclFwdBtn "후석 RH 리클라이닝 전방 이동";
BA_ "GenSigSendType" SG_ 607 ATS_RRStRclFwdBtn 4;
BA_ "UserSigValidity" SG_ 607 ATS_RRStRclFwdBtn 3;
BA_REL_ "GenSigTimeoutTime" BU_SG_REL_ RRPSM SG_ 607 ATS_RRStRclFwdBtn 1500;
BA_ "NetworkRequest" SG_ 607 ATS_RRStRclFwdBtn 0;
BA_ "NetworkRequestHoldingTime" SG_ 607 ATS_RRStRclFwdBtn 5000;
BA_ "Version" SG_ 607 ATS_RRStRclFwdBtn "19.09.02";
BA_ "Description" SG_ 607 ATS_RRStRclBwdBtn "후석 RH 리클라이닝 후방 이동";
BA_ "GenSigSendType" SG_ 607 ATS_RRStRclBwdBtn 4;
BA_ "UserSigValidity" SG_ 607 ATS_RRStRclBwdBtn 3;
BA_REL_ "GenSigTimeoutTime" BU_SG_REL_ RRPSM SG_ 607 ATS_RRStRclBwdBtn 1500;
BA_ "NetworkRequest" SG_ 607 ATS_RRStRclBwdBtn 0;
BA_ "NetworkRequestHoldingTime" SG_ 607 ATS_RRStRclBwdBtn 5000;
BA_ "Version" SG_ 607 ATS_RRStRclBwdBtn "19.09.02";
BA_ "Description" SG_ 607 ATS_RRStTltUpBtn "후석 RH 틸트 업 이동";
BA_ "GenSigSendType" SG_ 607 ATS_RRStTltUpBtn 4;
BA_ "UserSigValidity" SG_ 607 ATS_RRStTltUpBtn 3;
BA_REL_ "GenSigTimeoutTime" BU_SG_REL_ RRPSM SG_ 607 ATS_RRStTltUpBtn 1500;
BA_ "NetworkRequest" SG_ 607 ATS_RRStTltUpBtn 0;
BA_ "NetworkRequestHoldingTime" SG_ 607 ATS_RRStTltUpBtn 5000;
BA_ "Version" SG_ 607 ATS_RRStTltUpBtn "19.09.02";
BA_ "Description" SG_ 607 ATS_RRStTltDnBtn "후석 RH 틸트 다운 이동";
BA_ "GenSigSendType" SG_ 607 ATS_RRStTltDnBtn 4;
BA_ "UserSigValidity" SG_ 607 ATS_RRStTltDnBtn 3;
BA_REL_ "GenSigTimeoutTime" BU_SG_REL_ RRPSM SG_ 607 ATS_RRStTltDnBtn 1500;
BA_ "NetworkRequest" SG_ 607 ATS_RRStTltDnBtn 0;
BA_ "NetworkRequestHoldingTime" SG_ 607 ATS_RRStTltDnBtn 5000;
BA_ "Version" SG_ 607 ATS_RRStTltDnBtn "19.09.02";
BA_ "Description" SG_ 607 ATS_RRStHRestUpBtn "후석 RH 헤드레스트 업 이동";
BA_ "GenSigSendType" SG_ 607 ATS_RRStHRestUpBtn 4;
BA_ "UserSigValidity" SG_ 607 ATS_RRStHRestUpBtn 3;
BA_REL_ "GenSigTimeoutTime" BU_SG_REL_ RRPSM SG_ 607 ATS_RRStHRestUpBtn 1500;
BA_ "NetworkRequest" SG_ 607 ATS_RRStHRestUpBtn 0;
BA_ "NetworkRequestHoldingTime" SG_ 607 ATS_RRStHRestUpBtn 5000;
BA_ "Version" SG_ 607 ATS_RRStHRestUpBtn "19.09.02";
BA_ "Description" SG_ 607 ATS_RRStHRestDnBtn "후석 RH 헤드레스트 다운 이동";
BA_ "GenSigSendType" SG_ 607 ATS_RRStHRestDnBtn 4;
BA_ "UserSigValidity" SG_ 607 ATS_RRStHRestDnBtn 3;
BA_REL_ "GenSigTimeoutTime" BU_SG_REL_ RRPSM SG_ 607 ATS_RRStHRestDnBtn 1500;
BA_ "NetworkRequest" SG_ 607 ATS_RRStHRestDnBtn 0;
BA_ "NetworkRequestHoldingTime" SG_ 607 ATS_RRStHRestDnBtn 5000;
BA_ "Version" SG_ 607 ATS_RRStHRestDnBtn "19.09.02";
BA_ "Description" SG_ 607 ATS_RRStHRestFwdBtn "후석 RH 헤드레스트 전방 이동";
BA_ "GenSigSendType" SG_ 607 ATS_RRStHRestFwdBtn 4;
BA_ "UserSigValidity" SG_ 607 ATS_RRStHRestFwdBtn 3;
BA_REL_ "GenSigTimeoutTime" BU_SG_REL_ RRPSM SG_ 607 ATS_RRStHRestFwdBtn 1500;
BA_ "NetworkRequest" SG_ 607 ATS_RRStHRestFwdBtn 0;
BA_ "NetworkRequestHoldingTime" SG_ 607 ATS_RRStHRestFwdBtn 5000;
BA_ "Version" SG_ 607 ATS_RRStHRestFwdBtn "19.09.02";
BA_ "Description" SG_ 607 ATS_RRStHRestBwdBtn "후석 RH 헤드레스트 후방 이동";
BA_ "GenSigSendType" SG_ 607 ATS_RRStHRestBwdBtn 4;
BA_ "UserSigValidity" SG_ 607 ATS_RRStHRestBwdBtn 3;
BA_REL_ "GenSigTimeoutTime" BU_SG_REL_ RRPSM SG_ 607 ATS_RRStHRestBwdBtn 1500;
BA_ "NetworkRequest" SG_ 607 ATS_RRStHRestBwdBtn 0;
BA_ "NetworkRequestHoldingTime" SG_ 607 ATS_RRStHRestBwdBtn 5000;
BA_ "Version" SG_ 607 ATS_RRStHRestBwdBtn "19.09.02";
BA_ "Description" SG_ 607 ATS_RRStShoulderADJFwdBtn "후석 RH 숄더어져스터 FWD 이동";
BA_ "GenSigSendType" SG_ 607 ATS_RRStShoulderADJFwdBtn 4;
BA_ "UserSigValidity" SG_ 607 ATS_RRStShoulderADJFwdBtn 3;
BA_REL_ "GenSigTimeoutTime" BU_SG_REL_ RLPSM SG_ 607 ATS_RRStShoulderADJFwdBtn 1500;
BA_REL_ "GenSigTimeoutTime" BU_SG_REL_ RRPSM SG_ 607 ATS_RRStShoulderADJFwdBtn 1500;
BA_ "NetworkRequest" SG_ 607 ATS_RRStShoulderADJFwdBtn 0;
BA_ "NetworkRequestHoldingTime" SG_ 607 ATS_RRStShoulderADJFwdBtn 5000;
BA_ "Version" SG_ 607 ATS_RRStShoulderADJFwdBtn "20.03.02";
BA_ "Description" SG_ 607 ATS_RRStShoulderADJBwdBtn "후석 RH 숄더어져스터 BWD 이동";
BA_ "GenSigSendType" SG_ 607 ATS_RRStShoulderADJBwdBtn 4;
BA_ "UserSigValidity" SG_ 607 ATS_RRStShoulderADJBwdBtn 3;
BA_REL_ "GenSigTimeoutTime" BU_SG_REL_ RLPSM SG_ 607 ATS_RRStShoulderADJBwdBtn 1500;
BA_REL_ "GenSigTimeoutTime" BU_SG_REL_ RRPSM SG_ 607 ATS_RRStShoulderADJBwdBtn 1500;
BA_ "NetworkRequest" SG_ 607 ATS_RRStShoulderADJBwdBtn 0;
BA_ "NetworkRequestHoldingTime" SG_ 607 ATS_RRStShoulderADJBwdBtn 5000;
BA_ "Version" SG_ 607 ATS_RRStShoulderADJBwdBtn "20.03.02";
BA_ "Description" SG_ 607 ATS_RRStLegRestUpBtn "후석 RH 레그레스트 업 이동";
BA_ "GenSigSendType" SG_ 607 ATS_RRStLegRestUpBtn 4;
BA_ "UserSigValidity" SG_ 607 ATS_RRStLegRestUpBtn 3;
BA_REL_ "GenSigTimeoutTime" BU_SG_REL_ RRPSM SG_ 607 ATS_RRStLegRestUpBtn 1500;
BA_ "NetworkRequest" SG_ 607 ATS_RRStLegRestUpBtn 0;
BA_ "NetworkRequestHoldingTime" SG_ 607 ATS_RRStLegRestUpBtn 5000;
BA_ "Version" SG_ 607 ATS_RRStLegRestUpBtn "19.09.02";
BA_ "Description" SG_ 607 ATS_RRStLegRestDnBtn "후석 RH 레그레스트 다운 이동";
BA_ "GenSigSendType" SG_ 607 ATS_RRStLegRestDnBtn 4;
BA_ "UserSigValidity" SG_ 607 ATS_RRStLegRestDnBtn 3;
BA_REL_ "GenSigTimeoutTime" BU_SG_REL_ RRPSM SG_ 607 ATS_RRStLegRestDnBtn 1500;
BA_ "NetworkRequest" SG_ 607 ATS_RRStLegRestDnBtn 0;
BA_ "NetworkRequestHoldingTime" SG_ 607 ATS_RRStLegRestDnBtn 5000;
BA_ "Version" SG_ 607 ATS_RRStLegRestDnBtn "19.09.02";
BA_ "Description" SG_ 607 ATS_RRStLegRestExtUpBtn "후석 RH 레그레스트 전방 익스텐션 이동";
BA_ "GenSigSendType" SG_ 607 ATS_RRStLegRestExtUpBtn 4;
BA_ "UserSigValidity" SG_ 607 ATS_RRStLegRestExtUpBtn 3;
BA_REL_ "GenSigTimeoutTime" BU_SG_REL_ RRPSM SG_ 607 ATS_RRStLegRestExtUpBtn 1500;
BA_ "NetworkRequest" SG_ 607 ATS_RRStLegRestExtUpBtn 0;
BA_ "NetworkRequestHoldingTime" SG_ 607 ATS_RRStLegRestExtUpBtn 5000;
BA_ "Version" SG_ 607 ATS_RRStLegRestExtUpBtn "19.09.02";
BA_ "Description" SG_ 607 ATS_RRStLegRestExtDnBtn "후석 RH 레그레스트 후방 익스텐션 이동";
BA_ "GenSigSendType" SG_ 607 ATS_RRStLegRestExtDnBtn 4;
BA_ "UserSigValidity" SG_ 607 ATS_RRStLegRestExtDnBtn 3;
BA_REL_ "GenSigTimeoutTime" BU_SG_REL_ RRPSM SG_ 607 ATS_RRStLegRestExtDnBtn 1500;
BA_ "NetworkRequest" SG_ 607 ATS_RRStLegRestExtDnBtn 0;
BA_ "NetworkRequestHoldingTime" SG_ 607 ATS_RRStLegRestExtDnBtn 5000;
BA_ "Version" SG_ 607 ATS_RRStLegRestExtDnBtn "19.09.02";
BA_ "GenMsgSendType" BO_ 1058 0;
BA_ "Description" SG_ 1058 BCM_Crc10Val "The data area for CRC calculation is based on the data length (DLC) of the message DB.

The CRC shall be calculated over the entire data block (excluding the CRC bytes) including the user data, alive counter and Data ID 

 

- CRC Polynomial (0x1D) , Initial Value : 0x00, XOR value : 0xFF, Data ID Mode : Both, Data ID : Message ID + 0xF800 

- The initial value is for CRC calculation and the message should be sent with the calculated result value. 

The mathematical expression to 8 bit CRC polynomial is given here. G(x) = x8 + x4 + x3 + x2 + 1";
BA_ "GenSigSendType" SG_ 1058 BCM_Crc10Val 4;
BA_ "GenSigStartValue" SG_ 1058 BCM_Crc10Val 255;
BA_ "UserSigValidity" SG_ 1058 BCM_Crc10Val 0;
BA_ "Version" SG_ 1058 BCM_Crc10Val "18.11.08";
BA_ "Description" SG_ 1058 BCM_AlvCnt10Val "For the first transmission request for a data element the counter shall be initialized with 0 and shall be incremented by 1

for every subsequent send request. When the counter reaches the maximum value(0xE), then it shall restart with 0 for the next send request";
BA_ "GenSigSendType" SG_ 1058 BCM_AlvCnt10Val 4;
BA_ "UserSigValidity" SG_ 1058 BCM_AlvCnt10Val 0;
BA_ "Version" SG_ 1058 BCM_AlvCnt10Val "18.11.08";
BA_ "GenSigSendType" SG_ 1058 Wiper_PrkngPosSta 4;
BA_ "UserSigValidity" SG_ 1058 Wiper_PrkngPosSta 0;
BA_ "NetworkRequest" SG_ 1058 Wiper_PrkngPosSta 0;
BA_ "NetworkRequestHoldingTime" SG_ 1058 Wiper_PrkngPosSta 5000;
BA_ "Version" SG_ 1058 Wiper_PrkngPosSta "17.12.00";
BA_ "Description" SG_ 1058 Wiper_RainSnsrOptionTyp "Rain Sensor Option Information";
BA_ "GenSigSendType" SG_ 1058 Wiper_RainSnsrOptionTyp 4;
BA_ "UserSigValidity" SG_ 1058 Wiper_RainSnsrOptionTyp 0;
BA_ "NetworkRequest" SG_ 1058 Wiper_RainSnsrOptionTyp 0;
BA_ "NetworkRequestHoldingTime" SG_ 1058 Wiper_RainSnsrOptionTyp 5000;
BA_ "Version" SG_ 1058 Wiper_RainSnsrOptionTyp "17.12.00";
BA_ "Description" SG_ 1058 Wiper_RainSnsrSta "This signal represents the status of Rain Sensor signal state. 

- '20. 8/3 : Changed value table (0x5, 0x6 : Fault2/3 → Reserved)";
BA_ "GenSigSendType" SG_ 1058 Wiper_RainSnsrSta 4;
BA_ "UserSigValidity" SG_ 1058 Wiper_RainSnsrSta 0;
BA_ "NetworkRequest" SG_ 1058 Wiper_RainSnsrSta 0;
BA_ "NetworkRequestHoldingTime" SG_ 1058 Wiper_RainSnsrSta 5000;
BA_ "Version" SG_ 1058 Wiper_RainSnsrSta "20.08.00";
BA_ "Description" SG_ 1058 BCM_SolSnsrRtOutVoltVal "This signal indicates solar sensor output voltage - RH";
BA_ "GenSigSendType" SG_ 1058 BCM_SolSnsrRtOutVoltVal 4;
BA_ "UserSigValidity" SG_ 1058 BCM_SolSnsrRtOutVoltVal 0;
BA_ "NetworkRequest" SG_ 1058 BCM_SolSnsrRtOutVoltVal 0;
BA_ "NetworkRequestHoldingTime" SG_ 1058 BCM_SolSnsrRtOutVoltVal 5000;
BA_ "Version" SG_ 1058 BCM_SolSnsrRtOutVoltVal "18.04.02";
BA_ "Description" SG_ 1058 BCM_SolSnsrLftOutVoltVal "This signal indicates solar sensor output voltage - LH";
BA_ "GenSigSendType" SG_ 1058 BCM_SolSnsrLftOutVoltVal 4;
BA_ "UserSigValidity" SG_ 1058 BCM_SolSnsrLftOutVoltVal 0;
BA_ "NetworkRequest" SG_ 1058 BCM_SolSnsrLftOutVoltVal 0;
BA_ "NetworkRequestHoldingTime" SG_ 1058 BCM_SolSnsrLftOutVoltVal 5000;
BA_ "Version" SG_ 1058 BCM_SolSnsrLftOutVoltVal "18.04.02";
BA_ "GenSigSendType" SG_ 1058 BCM_GearPosPSta 4;
BA_ "UserSigValidity" SG_ 1058 BCM_GearPosPSta 0;
BA_REL_ "GenSigTimeoutTime" BU_SG_REL_ RLPSM SG_ 1058 BCM_GearPosPSta 1500;
BA_REL_ "GenSigTimeoutTime" BU_SG_REL_ ATS SG_ 1058 BCM_GearPosPSta 1500;
BA_ "NetworkRequest" SG_ 1058 BCM_GearPosPSta 0;
BA_ "NetworkRequestHoldingTime" SG_ 1058 BCM_GearPosPSta 5000;
BA_ "Version" SG_ 1058 BCM_GearPosPSta "17.12.00";
BA_ "Description" SG_ 1058 BCM_SunRoofOpnSta "-Sunroof open/close state";
BA_ "GenSigSendType" SG_ 1058 BCM_SunRoofOpnSta 4;
BA_ "UserSigValidity" SG_ 1058 BCM_SunRoofOpnSta 0;
BA_REL_ "GenSigTimeoutTime" BU_SG_REL_ AMP SG_ 1058 BCM_SunRoofOpnSta 1500;
BA_ "NetworkRequest" SG_ 1058 BCM_SunRoofOpnSta 0;
BA_ "NetworkRequestHoldingTime" SG_ 1058 BCM_SunRoofOpnSta 5000;
BA_ "Version" SG_ 1058 BCM_SunRoofOpnSta "17.12.00";
BA_ "Description" SG_ 1058 SunRoof_RrBlindErrSta "Rear Sunroof Blind error Status (LIN to CAN signal)

-LIN Signal Name : SunBlind_Rear_Error";
BA_ "GenSigSendType" SG_ 1058 SunRoof_RrBlindErrSta 4;
BA_ "UserSigValidity" SG_ 1058 SunRoof_RrBlindErrSta 0;
BA_ "Version" SG_ 1058 SunRoof_RrBlindErrSta "20.07.00";
BA_ "GenMsgCycleTime" BO_ 2563128065 0;
BA_ "VFrameFormat" BO_ 2563128065 1;
BA_ "GenSigSendType" SG_ 2563128065 AMP_EngOrderC2GainSet 4;
BA_ "GenSigStartValue" SG_ 2563128065 AMP_EngOrderC2GainSet 255;
BA_ "UserSigValidity" SG_ 2563128065 AMP_EngOrderC2GainSet 1;
BA_ "NetworkRequest" SG_ 2563128065 AMP_EngOrderC2GainSet 0;
BA_ "Version" SG_ 2563128065 AMP_EngOrderC2GainSet "18.12.06";
BA_ "GenSigSendType" SG_ 2563128065 AMP_EngOrderC6GainSet 4;
BA_ "GenSigStartValue" SG_ 2563128065 AMP_EngOrderC6GainSet 255;
BA_ "UserSigValidity" SG_ 2563128065 AMP_EngOrderC6GainSet 1;
BA_ "NetworkRequest" SG_ 2563128065 AMP_EngOrderC6GainSet 0;
BA_ "Version" SG_ 2563128065 AMP_EngOrderC6GainSet "18.12.06";
BA_ "Description" SG_ 2563128065 AMP_CLU_InfoVolumeStep "Command for cluster inforamtion Sound Volume Setting 

-range : 0 ~ 0xFE

-This Signal's Feedback is AMP_CLU_InfoVolumeState @AMP";
BA_ "GenSigSendType" SG_ 2563128065 AMP_CLU_InfoVolumeStep 4;
BA_ "GenSigStartValue" SG_ 2563128065 AMP_CLU_InfoVolumeStep 255;
BA_ "UserSigValidity" SG_ 2563128065 AMP_CLU_InfoVolumeStep 1;
BA_REL_ "GenSigTimeoutTime" BU_SG_REL_ AMP SG_ 2563128065 AMP_CLU_InfoVolumeStep 0;
BA_ "Version" SG_ 2563128065 AMP_CLU_InfoVolumeStep "21.05.02";
BA_ "Description" SG_ 2563128065 AMP_CLUinfo_OutputCh_Select "Command for Set cluster info sound Output Channel to identify which Speakers will output Sound

- per bit, 0 means 'Not Output Channel' and 1 means 'Output Channel'

bit0 : FL / bit1 : FR / bit2 : RL / bit3 : RR / bit4 : CTR / bit5 : Surround L /

bit6 : Surround R / bit7 : SWF / bit8 : Headrest L / bit9 : Headrest R / bit10 : Loof L /

bit11 : Loof CTR / bit12 : Loof R / bit13~bit15 : Reserved

- This Signal's Feedback is AMP_CLUinfo_OutputCh_State @AMP";
BA_ "GenSigSendType" SG_ 2563128065 AMP_CLUinfo_OutputCh_Select 4;
BA_ "GenSigStartValue" SG_ 2563128065 AMP_CLUinfo_OutputCh_Select 65535;
BA_ "UserSigValidity" SG_ 2563128065 AMP_CLUinfo_OutputCh_Select 1;
BA_REL_ "GenSigTimeoutTime" BU_SG_REL_ AMP SG_ 2563128065 AMP_CLUinfo_OutputCh_Select 0;
BA_ "Version" SG_ 2563128065 AMP_CLUinfo_OutputCh_Select "21.05.02";
BA_ "Description" SG_ 2563128065 AMP_ADASVolMasterGain "Command for ADAS warning Master Volume Gain Setting 

-range : 0x00 ~ 0x96

-Matching Table range : -75 Step ~ + 75 Step

-Factory Initial value : 0x4B ( Matching Master Gain = 0dB)

-This Signal's Feedback is AMP_ADASVolMasterGainState @AMP";
BA_ "GenSigSendType" SG_ 2563128065 AMP_ADASVolMasterGain 4;
BA_ "GenSigStartValue" SG_ 2563128065 AMP_ADASVolMasterGain 255;
BA_ "UserSigValidity" SG_ 2563128065 AMP_ADASVolMasterGain 1;
BA_REL_ "GenSigTimeoutTime" BU_SG_REL_ AMP SG_ 2563128065 AMP_ADASVolMasterGain 0;
BA_ "Version" SG_ 2563128065 AMP_ADASVolMasterGain "21.05.02";
BA_ "GenSigSendType" SG_ 2563128065 AMP_EngOrderC4GainSet 4;
BA_ "GenSigStartValue" SG_ 2563128065 AMP_EngOrderC4GainSet 255;
BA_ "UserSigValidity" SG_ 2563128065 AMP_EngOrderC4GainSet 1;
BA_ "NetworkRequest" SG_ 2563128065 AMP_EngOrderC4GainSet 0;
BA_ "Version" SG_ 2563128065 AMP_EngOrderC4GainSet "18.12.06";
BA_ "GenMsgCycleTime" BO_ 2315420161 0;
BA_ "VFrameFormat" BO_ 2315420161 1;
BA_ "Description" SG_ 2315420161 AVN_Encrypted_Result2 "This signal is for a send encrypted result of AVN";
BA_ "GenSigSendType" SG_ 2315420161 AVN_Encrypted_Result2 4;
BA_ "UserSigValidity" SG_ 2315420161 AVN_Encrypted_Result2 0;
BA_REL_ "GenSigTimeoutTime" BU_SG_REL_ FPM SG_ 2315420161 AVN_Encrypted_Result2 0;
BA_ "Version" SG_ 2315420161 AVN_Encrypted_Result2 "21.07.05";
BA_ "GenMsgSendType" BO_ 118 0;
BA_ "GenMsgCycleTime" BO_ 118 50;
BA_ "GenMsgCycleTimeFast" BO_ 118 0;
BA_ "GenMsgNrOfRepetition" BO_ 118 0;
BA_ "Description" SG_ 118 ICC_HS_Crc1Val "The data area for CRC calculation is based on the data length (DLC) of the message DB.

The CRC shall be calculated over the entire data block (excluding the CRC bytes) including the user data, alive counter and Data ID 

 

- CRC Polynomial (0x1D) , Initial Value : 0x00, XOR value : 0xFF, Data ID Mode : Both, Data ID : Message ID + 0xF800 

- The initial value is for CRC calculation and the message should be sent with the calculated result value. 

The mathematical expression to 8 bit CRC polynomial is given here. G(x) = x8 + x4 + x3 + x2 + 1";
BA_ "GenSigStartValue" SG_ 118 ICC_HS_Crc1Val 255;
BA_ "UserSigValidity" SG_ 118 ICC_HS_Crc1Val 3;
BA_ "Version" SG_ 118 ICC_HS_Crc1Val "21.03.02";
BA_ "Description" SG_ 118 ICC_HS_AlvCnt1Val "For the first transmission request for a data element the counter shall be initialized with 0 and shall be incremented by 1

for every subsequent send request. When the counter reaches the maximum value(0xE), then it shall restart with 0 for the next send request";
BA_ "UserSigValidity" SG_ 118 ICC_HS_AlvCnt1Val 3;
BA_ "Version" SG_ 118 ICC_HS_AlvCnt1Val "21.03.02";
BA_ "Description" SG_ 118 ICC_CamBlckdStat "The status of Camera Blockage";
BA_ "UserSigValidity" SG_ 118 ICC_CamBlckdStat 1;
BA_ "Version" SG_ 118 ICC_CamBlckdStat "21.03.02";
BA_ "Description" SG_ 118 ICC_WarningStat "The status of driver warning";
BA_ "UserSigValidity" SG_ 118 ICC_WarningStat 1;
BA_ "Version" SG_ 118 ICC_WarningStat "21.07.05";
BA_ "Description" SG_ 118 ICC_CamFailStat "The status of Camera Failure";
BA_ "UserSigValidity" SG_ 118 ICC_CamFailStat 1;
BA_ "Version" SG_ 118 ICC_CamFailStat "21.03.02";
BA_ "Description" SG_ 118 ICC_EcuFailStat "The status of ECU failure";
BA_ "UserSigValidity" SG_ 118 ICC_EcuFailStat 1;
BA_ "Version" SG_ 118 ICC_EcuFailStat "21.03.02";
BA_ "Description" SG_ 118 ICC_OptUsmStat "USM Setting";
BA_ "UserSigValidity" SG_ 118 ICC_OptUsmStat 1;
BA_ "Version" SG_ 118 ICC_OptUsmStat "21.03.02";
BA_ "Description" SG_ 118 ICC_MajorSWVer "Major Version of ICC ECU in Engineering Mode";
BA_ "UserSigValidity" SG_ 118 ICC_MajorSWVer 1;
BA_ "Version" SG_ 118 ICC_MajorSWVer "21.07.00";
BA_ "Description" SG_ 118 ICC_MinorSWVer "Minor Version of ICC ECU in Engineering Mode";
BA_ "UserSigValidity" SG_ 118 ICC_MinorSWVer 1;
BA_ "Version" SG_ 118 ICC_MinorSWVer "21.07.00";
BA_ "Description" SG_ 118 ICC_SymStat "The status of ICC Func.";
BA_ "UserSigValidity" SG_ 118 ICC_SymStat 1;
BA_ "Version" SG_ 118 ICC_SymStat "21.03.02";
BA_ "GenMsgSendType" BO_ 119 0;
BA_ "GenMsgCycleTime" BO_ 119 50;
BA_ "GenMsgCycleTimeFast" BO_ 119 0;
BA_ "GenMsgNrOfRepetition" BO_ 119 0;
BA_ "Description" SG_ 119 ICC_HS_Crc2Val "The data area for CRC calculation is based on the data length (DLC) of the message DB.

The CRC shall be calculated over the entire data block (excluding the CRC bytes) including the user data, alive counter and Data ID 

 

- CRC Polynomial (0x1D) , Initial Value : 0x00, XOR value : 0xFF, Data ID Mode : Both, Data ID : Message ID + 0xF800 

- The initial value is for CRC calculation and the message should be sent with the calculated result value. 

The mathematical expression to 8 bit CRC polynomial is given here. G(x) = x8 + x4 + x3 + x2 + 1";
BA_ "GenSigStartValue" SG_ 119 ICC_HS_Crc2Val 255;
BA_ "UserSigValidity" SG_ 119 ICC_HS_Crc2Val 3;
BA_ "Version" SG_ 119 ICC_HS_Crc2Val "21.03.02";
BA_ "Description" SG_ 119 ICC_HS_AlvCnt2Val "For the first transmission request for a data element the counter shall be initialized with 0 and shall be incremented by 1

for every subsequent send request. When the counter reaches the maximum value(0xE), then it shall restart with 0 for the next send request";
BA_ "UserSigValidity" SG_ 119 ICC_HS_AlvCnt2Val 3;
BA_ "Version" SG_ 119 ICC_HS_AlvCnt2Val "21.03.02";
BA_ "Description" SG_ 119 ICC_EyePosXVal "the X-axis value of Eye Position";
BA_ "GenSigStartValue" SG_ 119 ICC_EyePosXVal 30;
BA_ "UserSigValidity" SG_ 119 ICC_EyePosXVal 1;
BA_ "Version" SG_ 119 ICC_EyePosXVal "21.03.02";
BA_ "Description" SG_ 119 ICC_EyePosYVal "the Y-axis value of Eye Position";
BA_ "GenSigStartValue" SG_ 119 ICC_EyePosYVal 30;
BA_ "UserSigValidity" SG_ 119 ICC_EyePosYVal 1;
BA_ "Version" SG_ 119 ICC_EyePosYVal "21.03.02";
BA_ "Description" SG_ 119 ICC_EyePosZVal "the Z-axis value of Eye Position";
BA_ "GenSigStartValue" SG_ 119 ICC_EyePosZVal 30;
BA_ "UserSigValidity" SG_ 119 ICC_EyePosZVal 1;
BA_ "Version" SG_ 119 ICC_EyePosZVal "21.03.02";
BA_ "Description" SG_ 119 ICC_EyeGazeYawVal "the Yaw value of Eye Gaze";
BA_ "GenSigStartValue" SG_ 119 ICC_EyeGazeYawVal 30;
BA_ "UserSigValidity" SG_ 119 ICC_EyeGazeYawVal 1;
BA_ "Version" SG_ 119 ICC_EyeGazeYawVal "21.04.00";
BA_ "Description" SG_ 119 ICC_EyeGazePitchVal "the Pitch value of Eye Gaze";
BA_ "GenSigStartValue" SG_ 119 ICC_EyeGazePitchVal 30;
BA_ "UserSigValidity" SG_ 119 ICC_EyeGazePitchVal 1;
BA_ "Version" SG_ 119 ICC_EyeGazePitchVal "21.04.00";
BA_ "GenMsgSendType" BO_ 120 0;
BA_ "GenMsgCycleTime" BO_ 120 50;
BA_ "GenMsgCycleTimeFast" BO_ 120 0;
BA_ "GenMsgNrOfRepetition" BO_ 120 0;
BA_ "Description" SG_ 120 ICC_HS_Crc3Val "The data area for CRC calculation is based on the data length (DLC) of the message DB.

The CRC shall be calculated over the entire data block (excluding the CRC bytes) including the user data, alive counter and Data ID 

 

- CRC Polynomial (0x1D) , Initial Value : 0x00, XOR value : 0xFF, Data ID Mode : Both, Data ID : Message ID + 0xF800 

- The initial value is for CRC calculation and the message should be sent with the calculated result value. 

The mathematical expression to 8 bit CRC polynomial is given here. G(x) = x8 + x4 + x3 + x2 + 1";
BA_ "GenSigStartValue" SG_ 120 ICC_HS_Crc3Val 255;
BA_ "UserSigValidity" SG_ 120 ICC_HS_Crc3Val 3;
BA_ "Version" SG_ 120 ICC_HS_Crc3Val "21.03.02";
BA_ "Description" SG_ 120 ICC_HS_AlvCnt3Val "For the first transmission request for a data element the counter shall be initialized with 0 and shall be incremented by 1

for every subsequent send request. When the counter reaches the maximum value(0xE), then it shall restart with 0 for the next send request";
BA_ "UserSigValidity" SG_ 120 ICC_HS_AlvCnt3Val 3;
BA_ "Version" SG_ 120 ICC_HS_AlvCnt3Val "21.03.02";
BA_ "Description" SG_ 120 ICC_HeadPoseYawVal "the Yaw value of Head Pose";
BA_ "GenSigStartValue" SG_ 120 ICC_HeadPoseYawVal 30;
BA_ "UserSigValidity" SG_ 120 ICC_HeadPoseYawVal 1;
BA_ "Version" SG_ 120 ICC_HeadPoseYawVal "21.04.00";
BA_ "Description" SG_ 120 ICC_HeadPosePitchVal "the Pitch value of Head Pose";
BA_ "GenSigStartValue" SG_ 120 ICC_HeadPosePitchVal 30;
BA_ "UserSigValidity" SG_ 120 ICC_HeadPosePitchVal 1;
BA_ "Version" SG_ 120 ICC_HeadPosePitchVal "21.04.00";
BA_ "Description" SG_ 120 ICC_HeadPoseRollVal "the Roll value of Head Pose";
BA_ "GenSigStartValue" SG_ 120 ICC_HeadPoseRollVal 30;
BA_ "UserSigValidity" SG_ 120 ICC_HeadPoseRollVal 1;
BA_ "Version" SG_ 120 ICC_HeadPoseRollVal "21.04.00";
BA_ "Description" SG_ 120 ICC_EyeOpenVal "the value of Eye Openness";
BA_ "UserSigValidity" SG_ 120 ICC_EyeOpenVal 1;
BA_ "Version" SG_ 120 ICC_EyeOpenVal "21.03.02";
BA_ "Description" SG_ 120 ICC_LeftEyeOpenVal "the value of Left Eye Openness";
BA_ "UserSigValidity" SG_ 120 ICC_LeftEyeOpenVal 1;
BA_ "Version" SG_ 120 ICC_LeftEyeOpenVal "21.03.02";
BA_ "Description" SG_ 120 ICC_RightEyeOpenVal "the value of Right Eye Openness";
BA_ "UserSigValidity" SG_ 120 ICC_RightEyeOpenVal 1;
BA_ "Version" SG_ 120 ICC_RightEyeOpenVal "21.03.02";
BA_ "Description" SG_ 120 ICC_EyeBlinkOccurrence "the Occurrence of Eye Blink Count before last 50ms";
BA_ "UserSigValidity" SG_ 120 ICC_EyeBlinkOccurrence 1;
BA_ "Version" SG_ 120 ICC_EyeBlinkOccurrence "21.07.05";
BA_ "GenMsgSendType" BO_ 121 0;
BA_ "GenMsgCycleTime" BO_ 121 50;
BA_ "GenMsgCycleTimeFast" BO_ 121 0;
BA_ "GenMsgNrOfRepetition" BO_ 121 0;
BA_ "Description" SG_ 121 ICC_HS_Crc4Val "The data area for CRC calculation is based on the data length (DLC) of the message DB.

The CRC shall be calculated over the entire data block (excluding the CRC bytes) including the user data, alive counter and Data ID 

 

- CRC Polynomial (0x1D) , Initial Value : 0x00, XOR value : 0xFF, Data ID Mode : Both, Data ID : Message ID + 0xF800 

- The initial value is for CRC calculation and the message should be sent with the calculated result value. 

The mathematical expression to 8 bit CRC polynomial is given here. G(x) = x8 + x4 + x3 + x2 + 1";
BA_ "GenSigStartValue" SG_ 121 ICC_HS_Crc4Val 255;
BA_ "UserSigValidity" SG_ 121 ICC_HS_Crc4Val 3;
BA_ "Version" SG_ 121 ICC_HS_Crc4Val "21.03.02";
BA_ "Description" SG_ 121 ICC_HS_AlvCnt4Val "For the first transmission request for a data element the counter shall be initialized with 0 and shall be incremented by 1

for every subsequent send request. When the counter reaches the maximum value(0xE), then it shall restart with 0 for the next send request";
BA_ "UserSigValidity" SG_ 121 ICC_HS_AlvCnt4Val 3;
BA_ "Version" SG_ 121 ICC_HS_AlvCnt4Val "21.03.02";
BA_ "Description" SG_ 121 ICC_EyeStat "the status of Eye Openness";
BA_ "UserSigValidity" SG_ 121 ICC_EyeStat 1;
BA_ "Version" SG_ 121 ICC_EyeStat "21.03.02";
BA_ "Description" SG_ 121 ICC_LeftEyeOpenStat "the status of left eye openness";
BA_ "UserSigValidity" SG_ 121 ICC_LeftEyeOpenStat 1;
BA_ "Version" SG_ 121 ICC_LeftEyeOpenStat "21.03.02";
BA_ "Description" SG_ 121 ICC_RightEyeOpenStat "the status of right eye openness";
BA_ "UserSigValidity" SG_ 121 ICC_RightEyeOpenStat 1;
BA_ "Version" SG_ 121 ICC_RightEyeOpenStat "21.03.02";
BA_ "Description" SG_ 121 ICC_DistLvlStat "the status of distraction level";
BA_ "UserSigValidity" SG_ 121 ICC_DistLvlStat 1;
BA_ "Version" SG_ 121 ICC_DistLvlStat "21.03.02";
BA_ "Description" SG_ 121 ICC_DrwsLvlStat "the status of drowsiness level";
BA_ "UserSigValidity" SG_ 121 ICC_DrwsLvlStat 1;
BA_ "Version" SG_ 121 ICC_DrwsLvlStat "21.03.02";
BA_ "Description" SG_ 121 ICC_FaceDetectStat "the status of face detection";
BA_ "UserSigValidity" SG_ 121 ICC_FaceDetectStat 1;
BA_ "Version" SG_ 121 ICC_FaceDetectStat "21.03.02";
BA_ "Description" SG_ 121 ICC_FaceFakeStat "the status of fake-face detection";
BA_ "UserSigValidity" SG_ 121 ICC_FaceFakeStat 1;
BA_ "Version" SG_ 121 ICC_FaceFakeStat "21.03.02";
BA_ "Description" SG_ 121 ICC_AoIStat "the status of Area of Interest detestion";
BA_ "UserSigValidity" SG_ 121 ICC_AoIStat 1;
BA_ "Version" SG_ 121 ICC_AoIStat "21.03.02";
BA_ "GenMsgSendType" BO_ 1086 0;
BA_ "Description" SG_ 1086 RL_CURTAIN_POSITION "2열 좌측 윈도우 글라스 커튼 위치 정보";
BA_ "GenSigSendType" SG_ 1086 RL_CURTAIN_POSITION 4;
BA_ "UserSigValidity" SG_ 1086 RL_CURTAIN_POSITION 0;
BA_REL_ "GenSigTimeoutTime" BU_SG_REL_ ATS SG_ 1086 RL_CURTAIN_POSITION 1500;
BA_REL_ "GenSigTimeoutTime" BU_SG_REL_ CGW_CCU SG_ 1086 RL_CURTAIN_POSITION 1500;
BA_ "NetworkRequest" SG_ 1086 RL_CURTAIN_POSITION 0;
BA_ "NetworkRequestHoldingTime" SG_ 1086 RL_CURTAIN_POSITION 5000;
BA_ "Version" SG_ 1086 RL_CURTAIN_POSITION "18.03.07";
BA_ "Description" SG_ 1086 RDC_SWVerMinor1 "Indicate the RDC software version as follows:

- The software version is displayed in three digits.

- The Major and Minor digits are separated by '.'

- Signal values are transmitted to ASCII codes.



※ Example

RDC_SWVerMajor1 : 0x41 (HEX) -> ASCII CODE : 'A' 

RDC_SWVerMinor1 : 0x30 (HEX) -> ASCII CODE : '0'

RDC_SWVerMinor2 : 0x33 (HEX) -> ASCII CODE : '3'

=> RDC S/W Ver is displayed 'A.03'";
BA_ "GenSigSendType" SG_ 1086 RDC_SWVerMinor1 4;
BA_ "UserSigValidity" SG_ 1086 RDC_SWVerMinor1 0;
BA_REL_ "GenSigTimeoutTime" BU_SG_REL_ CGW_CCU SG_ 1086 RDC_SWVerMinor1 1500;
BA_ "Version" SG_ 1086 RDC_SWVerMinor1 "18.10.06";
BA_ "Description" SG_ 1086 RDC_SWVerMinor2 "Indicate the RDC software version as follows:

- The software version is displayed in three digits.

- The Major and Minor digits are separated by '.'

- Signal values are transmitted to ASCII codes.



※ Example

RDC_SWVerMajor1 : 0x41 (HEX) -> ASCII CODE : 'A' 

RDC_SWVerMinor1 : 0x30 (HEX) -> ASCII CODE : '0'

RDC_SWVerMinor2 : 0x33 (HEX) -> ASCII CODE : '3'

=> RDC S/W Ver is displayed 'A.03'";
BA_ "GenSigSendType" SG_ 1086 RDC_SWVerMinor2 4;
BA_ "UserSigValidity" SG_ 1086 RDC_SWVerMinor2 0;
BA_REL_ "GenSigTimeoutTime" BU_SG_REL_ CGW_CCU SG_ 1086 RDC_SWVerMinor2 1500;
BA_ "Version" SG_ 1086 RDC_SWVerMinor2 "18.10.06";
BA_ "Description" SG_ 1086 RR_CURTAIN_POSITION "2열 우측 윈도우 글라스 커튼 위치 정보";
BA_ "GenSigSendType" SG_ 1086 RR_CURTAIN_POSITION 4;
BA_ "UserSigValidity" SG_ 1086 RR_CURTAIN_POSITION 0;
BA_REL_ "GenSigTimeoutTime" BU_SG_REL_ ATS SG_ 1086 RR_CURTAIN_POSITION 1500;
BA_REL_ "GenSigTimeoutTime" BU_SG_REL_ CGW_CCU SG_ 1086 RR_CURTAIN_POSITION 1500;
BA_ "NetworkRequest" SG_ 1086 RR_CURTAIN_POSITION 0;
BA_ "NetworkRequestHoldingTime" SG_ 1086 RR_CURTAIN_POSITION 5000;
BA_ "Version" SG_ 1086 RR_CURTAIN_POSITION "18.03.07";
BA_ "Description" SG_ 1086 RDC_RrLftDoorCurtainActSta "This signal indicates RL Door Curtain Action Status";
BA_ "GenSigSendType" SG_ 1086 RDC_RrLftDoorCurtainActSta 4;
BA_ "UserSigValidity" SG_ 1086 RDC_RrLftDoorCurtainActSta 0;
BA_REL_ "GenSigTimeoutTime" BU_SG_REL_ ATS SG_ 1086 RDC_RrLftDoorCurtainActSta 1500;
BA_ "NetworkRequest" SG_ 1086 RDC_RrLftDoorCurtainActSta 0;
BA_ "NetworkRequestHoldingTime" SG_ 1086 RDC_RrLftDoorCurtainActSta 5000;
BA_ "Version" SG_ 1086 RDC_RrLftDoorCurtainActSta "20.08.00";
BA_ "Description" SG_ 1086 RDC_RrRtDoorCurtainActSta "This signal indicates RR Door Curtain Action Status";
BA_ "GenSigSendType" SG_ 1086 RDC_RrRtDoorCurtainActSta 4;
BA_ "UserSigValidity" SG_ 1086 RDC_RrRtDoorCurtainActSta 0;
BA_REL_ "GenSigTimeoutTime" BU_SG_REL_ ATS SG_ 1086 RDC_RrRtDoorCurtainActSta 1500;
BA_ "NetworkRequest" SG_ 1086 RDC_RrRtDoorCurtainActSta 0;
BA_ "NetworkRequestHoldingTime" SG_ 1086 RDC_RrRtDoorCurtainActSta 5000;
BA_ "Version" SG_ 1086 RDC_RrRtDoorCurtainActSta "20.08.00";
BA_ "Description" SG_ 1086 RDC_VitalityCurtainSta "Current setting value for RDC curtain of mood-therapy";
BA_ "GenSigSendType" SG_ 1086 RDC_VitalityCurtainSta 4;
BA_ "UserSigValidity" SG_ 1086 RDC_VitalityCurtainSta 0;
BA_REL_ "GenSigTimeoutTime" BU_SG_REL_ CGW_CCU SG_ 1086 RDC_VitalityCurtainSta 1500;
BA_ "NetworkRequest" SG_ 1086 RDC_VitalityCurtainSta 0;
BA_ "NetworkRequestHoldingTime" SG_ 1086 RDC_VitalityCurtainSta 5000;
BA_ "Version" SG_ 1086 RDC_VitalityCurtainSta "20.07.10";
BA_ "Description" SG_ 1086 RDC_DelightCurtainSta "Current setting value for RDC curtain of mood-therapy";
BA_ "GenSigSendType" SG_ 1086 RDC_DelightCurtainSta 4;
BA_ "UserSigValidity" SG_ 1086 RDC_DelightCurtainSta 0;
BA_REL_ "GenSigTimeoutTime" BU_SG_REL_ CGW_CCU SG_ 1086 RDC_DelightCurtainSta 1500;
BA_ "NetworkRequest" SG_ 1086 RDC_DelightCurtainSta 0;
BA_ "NetworkRequestHoldingTime" SG_ 1086 RDC_DelightCurtainSta 5000;
BA_ "Version" SG_ 1086 RDC_DelightCurtainSta "20.07.10";
BA_ "Description" SG_ 1086 RDC_OptTyp "RDC OPTION SIGNAL";
BA_ "GenSigSendType" SG_ 1086 RDC_OptTyp 4;
BA_ "UserSigValidity" SG_ 1086 RDC_OptTyp 0;
BA_REL_ "GenSigTimeoutTime" BU_SG_REL_ ATS SG_ 1086 RDC_OptTyp 1500;
BA_REL_ "GenSigTimeoutTime" BU_SG_REL_ CGW_CCU SG_ 1086 RDC_OptTyp 1500;
BA_ "NetworkRequest" SG_ 1086 RDC_OptTyp 0;
BA_ "NetworkRequestHoldingTime" SG_ 1086 RDC_OptTyp 5000;
BA_ "Version" SG_ 1086 RDC_OptTyp "20.01.01";
BA_ "Description" SG_ 1086 RDC_CareCurtainSta "Current setting value for RDC curtain of mood-therapy";
BA_ "GenSigSendType" SG_ 1086 RDC_CareCurtainSta 4;
BA_ "UserSigValidity" SG_ 1086 RDC_CareCurtainSta 0;
BA_REL_ "GenSigTimeoutTime" BU_SG_REL_ CGW_CCU SG_ 1086 RDC_CareCurtainSta 1500;
BA_ "NetworkRequest" SG_ 1086 RDC_CareCurtainSta 0;
BA_ "NetworkRequestHoldingTime" SG_ 1086 RDC_CareCurtainSta 5000;
BA_ "Version" SG_ 1086 RDC_CareCurtainSta "20.07.10";
BA_ "Description" SG_ 1086 RDC_ComfortCurtainSta "Current setting value for RDC curtain of mood-therapy";
BA_ "GenSigSendType" SG_ 1086 RDC_ComfortCurtainSta 4;
BA_ "UserSigValidity" SG_ 1086 RDC_ComfortCurtainSta 0;
BA_REL_ "GenSigTimeoutTime" BU_SG_REL_ CGW_CCU SG_ 1086 RDC_ComfortCurtainSta 1500;
BA_ "NetworkRequest" SG_ 1086 RDC_ComfortCurtainSta 0;
BA_ "NetworkRequestHoldingTime" SG_ 1086 RDC_ComfortCurtainSta 5000;
BA_ "Version" SG_ 1086 RDC_ComfortCurtainSta "20.07.10";
BA_ "Description" SG_ 1086 RDC_SWVerMajor1 "Indicate the RDC software version as follows:

- The software version is displayed in three digits.

- The Major and Minor digits are separated by '.'

- Signal values are transmitted to ASCII codes.



※ Example

RDC_SWVerMajor1 : 0x41 (HEX) -> ASCII CODE : 'A' 

RDC_SWVerMinor1 : 0x30 (HEX) -> ASCII CODE : '0'

RDC_SWVerMinor2 : 0x33 (HEX) -> ASCII CODE : '3'

=> RDC S/W Ver is displayed 'A.03'";
BA_ "GenSigSendType" SG_ 1086 RDC_SWVerMajor1 4;
BA_ "UserSigValidity" SG_ 1086 RDC_SWVerMajor1 0;
BA_REL_ "GenSigTimeoutTime" BU_SG_REL_ CGW_CCU SG_ 1086 RDC_SWVerMajor1 1500;
BA_ "Version" SG_ 1086 RDC_SWVerMajor1 "21.07.00";
BA_ "GenMsgSendType" BO_ 1080 0;
BA_ "Description" SG_ 1080 RL_SHVU_SeatOptSta "후석 LH 시트에 적용된 히터/통풍 옵션 사양";
BA_ "GenSigSendType" SG_ 1080 RL_SHVU_SeatOptSta 4;
BA_ "UserSigValidity" SG_ 1080 RL_SHVU_SeatOptSta 3;
BA_REL_ "GenSigTimeoutTime" BU_SG_REL_ ATS SG_ 1080 RL_SHVU_SeatOptSta 1500;
BA_REL_ "GenSigTimeoutTime" BU_SG_REL_ CGW_CCU SG_ 1080 RL_SHVU_SeatOptSta 1500;
BA_ "NetworkRequest" SG_ 1080 RL_SHVU_SeatOptSta 0;
BA_ "NetworkRequestHoldingTime" SG_ 1080 RL_SHVU_SeatOptSta 5000;
BA_ "Version" SG_ 1080 RL_SHVU_SeatOptSta "17.12.03";
BA_ "Description" SG_ 1080 RL_SHVU_HtAutoDownRVal "후석 LH 히터 오토다운 Enable/Disable 설정 정보";
BA_ "GenSigSendType" SG_ 1080 RL_SHVU_HtAutoDownRVal 4;
BA_ "UserSigValidity" SG_ 1080 RL_SHVU_HtAutoDownRVal 3;
BA_REL_ "GenSigTimeoutTime" BU_SG_REL_ ATS SG_ 1080 RL_SHVU_HtAutoDownRVal 1500;
BA_REL_ "GenSigTimeoutTime" BU_SG_REL_ ATS SG_ 1080 RL_SHVU_HtAutoDownRVal 1500;
BA_REL_ "GenSigTimeoutTime" BU_SG_REL_ CGW_CCU SG_ 1080 RL_SHVU_HtAutoDownRVal 1500;
BA_REL_ "GenSigTimeoutTime" BU_SG_REL_ CGW_CCU SG_ 1080 RL_SHVU_HtAutoDownRVal 1500;
BA_ "NetworkRequest" SG_ 1080 RL_SHVU_HtAutoDownRVal 0;
BA_ "NetworkRequestHoldingTime" SG_ 1080 RL_SHVU_HtAutoDownRVal 5000;
BA_ "Version" SG_ 1080 RL_SHVU_HtAutoDownRVal "17.12.03";
BA_ "Description" SG_ 1080 RL_SHVU_VntTurboSta "후석 LH 시트 통풍 터보모드 진입 정보";
BA_ "GenSigSendType" SG_ 1080 RL_SHVU_VntTurboSta 4;
BA_ "UserSigValidity" SG_ 1080 RL_SHVU_VntTurboSta 3;
BA_REL_ "GenSigTimeoutTime" BU_SG_REL_ ATS SG_ 1080 RL_SHVU_VntTurboSta 1500;
BA_REL_ "GenSigTimeoutTime" BU_SG_REL_ ATS SG_ 1080 RL_SHVU_VntTurboSta 1500;
BA_REL_ "GenSigTimeoutTime" BU_SG_REL_ CGW_CCU SG_ 1080 RL_SHVU_VntTurboSta 1500;
BA_REL_ "GenSigTimeoutTime" BU_SG_REL_ CGW_CCU SG_ 1080 RL_SHVU_VntTurboSta 1500;
BA_ "NetworkRequest" SG_ 1080 RL_SHVU_VntTurboSta 0;
BA_ "NetworkRequestHoldingTime" SG_ 1080 RL_SHVU_VntTurboSta 5000;
BA_ "Version" SG_ 1080 RL_SHVU_VntTurboSta "17.12.03";
BA_ "Description" SG_ 1080 RL_SHVU_SeatOptSta_RHD "후석 LH 시트에 적용된 히터/통풍 옵션 사양 (RHD)";
BA_ "GenSigSendType" SG_ 1080 RL_SHVU_SeatOptSta_RHD 4;
BA_ "UserSigValidity" SG_ 1080 RL_SHVU_SeatOptSta_RHD 3;
BA_REL_ "GenSigTimeoutTime" BU_SG_REL_ ATS SG_ 1080 RL_SHVU_SeatOptSta_RHD 1500;
BA_REL_ "GenSigTimeoutTime" BU_SG_REL_ CGW_CCU SG_ 1080 RL_SHVU_SeatOptSta_RHD 1500;
BA_ "NetworkRequest" SG_ 1080 RL_SHVU_SeatOptSta_RHD 0;
BA_ "NetworkRequestHoldingTime" SG_ 1080 RL_SHVU_SeatOptSta_RHD 5000;
BA_ "Version" SG_ 1080 RL_SHVU_SeatOptSta_RHD "19.08.05";
BA_ "Description" SG_ 1080 RL_SHVU_SeatHtOperSta_RHD "후석 LH 시트 현재 작동 중인 히터/통풍 단수 상태 (RHD)";
BA_ "GenSigSendType" SG_ 1080 RL_SHVU_SeatHtOperSta_RHD 4;
BA_ "UserSigValidity" SG_ 1080 RL_SHVU_SeatHtOperSta_RHD 3;
BA_REL_ "GenSigTimeoutTime" BU_SG_REL_ ATS SG_ 1080 RL_SHVU_SeatHtOperSta_RHD 1500;
BA_REL_ "GenSigTimeoutTime" BU_SG_REL_ CGW_CCU SG_ 1080 RL_SHVU_SeatHtOperSta_RHD 1500;
BA_ "NetworkRequest" SG_ 1080 RL_SHVU_SeatHtOperSta_RHD 0;
BA_ "NetworkRequestHoldingTime" SG_ 1080 RL_SHVU_SeatHtOperSta_RHD 5000;
BA_ "Version" SG_ 1080 RL_SHVU_SeatHtOperSta_RHD "19.08.05";
BA_ "Description" SG_ 1080 RL_SHVU_SeatHtOperSta "후석 LH 시트 현재 작동 중인 히터/통풍 단수 상태";
BA_ "GenSigSendType" SG_ 1080 RL_SHVU_SeatHtOperSta 4;
BA_ "UserSigValidity" SG_ 1080 RL_SHVU_SeatHtOperSta 3;
BA_REL_ "GenSigTimeoutTime" BU_SG_REL_ ATS SG_ 1080 RL_SHVU_SeatHtOperSta 1500;
BA_REL_ "GenSigTimeoutTime" BU_SG_REL_ CGW_CCU SG_ 1080 RL_SHVU_SeatHtOperSta 1500;
BA_ "NetworkRequest" SG_ 1080 RL_SHVU_SeatHtOperSta 0;
BA_ "NetworkRequestHoldingTime" SG_ 1080 RL_SHVU_SeatHtOperSta 5000;
BA_ "Version" SG_ 1080 RL_SHVU_SeatHtOperSta "17.12.03";
BA_ "Description" SG_ 1080 RL_SHVU_HtSwHiIndSta_RHD "RL 시트 열선 스위치 High Indicator 정보 (RHD)

-2nd LH Seat heater high Information";
BA_ "GenSigSendType" SG_ 1080 RL_SHVU_HtSwHiIndSta_RHD 4;
BA_ "UserSigValidity" SG_ 1080 RL_SHVU_HtSwHiIndSta_RHD 3;
BA_REL_ "GenSigTimeoutTime" BU_SG_REL_ ATS SG_ 1080 RL_SHVU_HtSwHiIndSta_RHD 1500;
BA_REL_ "GenSigTimeoutTime" BU_SG_REL_ CGW_CCU SG_ 1080 RL_SHVU_HtSwHiIndSta_RHD 1500;
BA_ "NetworkRequest" SG_ 1080 RL_SHVU_HtSwHiIndSta_RHD 0;
BA_ "NetworkRequestHoldingTime" SG_ 1080 RL_SHVU_HtSwHiIndSta_RHD 5000;
BA_ "Version" SG_ 1080 RL_SHVU_HtSwHiIndSta_RHD "19.08.05";
BA_ "Description" SG_ 1080 RL_SHVU_HtSwMidIndSta_RHD "RL 시트 열선 스위치 Mid Indicator 정보 (RHD)

-2nd LH Seat heater mid Information";
BA_ "GenSigSendType" SG_ 1080 RL_SHVU_HtSwMidIndSta_RHD 4;
BA_ "UserSigValidity" SG_ 1080 RL_SHVU_HtSwMidIndSta_RHD 3;
BA_REL_ "GenSigTimeoutTime" BU_SG_REL_ ATS SG_ 1080 RL_SHVU_HtSwMidIndSta_RHD 1500;
BA_REL_ "GenSigTimeoutTime" BU_SG_REL_ CGW_CCU SG_ 1080 RL_SHVU_HtSwMidIndSta_RHD 1500;
BA_ "NetworkRequest" SG_ 1080 RL_SHVU_HtSwMidIndSta_RHD 0;
BA_ "NetworkRequestHoldingTime" SG_ 1080 RL_SHVU_HtSwMidIndSta_RHD 5000;
BA_ "Version" SG_ 1080 RL_SHVU_HtSwMidIndSta_RHD "19.08.05";
BA_ "Description" SG_ 1080 RL_SHVU_HtSwLowIndSta_RHD "RL 시트 열선 스위치 Low Indicator 정보 (RHD)

-2nd LH Seat heater low Information";
BA_ "GenSigSendType" SG_ 1080 RL_SHVU_HtSwLowIndSta_RHD 4;
BA_ "UserSigValidity" SG_ 1080 RL_SHVU_HtSwLowIndSta_RHD 3;
BA_REL_ "GenSigTimeoutTime" BU_SG_REL_ ATS SG_ 1080 RL_SHVU_HtSwLowIndSta_RHD 1500;
BA_REL_ "GenSigTimeoutTime" BU_SG_REL_ CGW_CCU SG_ 1080 RL_SHVU_HtSwLowIndSta_RHD 1500;
BA_ "NetworkRequest" SG_ 1080 RL_SHVU_HtSwLowIndSta_RHD 0;
BA_ "NetworkRequestHoldingTime" SG_ 1080 RL_SHVU_HtSwLowIndSta_RHD 5000;
BA_ "Version" SG_ 1080 RL_SHVU_HtSwLowIndSta_RHD "19.08.05";
BA_ "Description" SG_ 1080 RL_SHVU_VntSwHiIndSta_RHD "RL 시트 통풍 스위치 High Indicator 정보 (RHD)

-2nd LH Seat vent high Information";
BA_ "GenSigSendType" SG_ 1080 RL_SHVU_VntSwHiIndSta_RHD 4;
BA_ "UserSigValidity" SG_ 1080 RL_SHVU_VntSwHiIndSta_RHD 3;
BA_REL_ "GenSigTimeoutTime" BU_SG_REL_ ATS SG_ 1080 RL_SHVU_VntSwHiIndSta_RHD 1500;
BA_REL_ "GenSigTimeoutTime" BU_SG_REL_ CGW_CCU SG_ 1080 RL_SHVU_VntSwHiIndSta_RHD 1500;
BA_ "NetworkRequest" SG_ 1080 RL_SHVU_VntSwHiIndSta_RHD 0;
BA_ "NetworkRequestHoldingTime" SG_ 1080 RL_SHVU_VntSwHiIndSta_RHD 5000;
BA_ "Version" SG_ 1080 RL_SHVU_VntSwHiIndSta_RHD "19.08.05";
BA_ "Description" SG_ 1080 RL_SHVU_VntSwMidIndSta_RHD "RL 시트 통풍 스위치 Mid Indicator 정보 (RHD)

-2nd LH Seat vent mid Information";
BA_ "GenSigSendType" SG_ 1080 RL_SHVU_VntSwMidIndSta_RHD 4;
BA_ "UserSigValidity" SG_ 1080 RL_SHVU_VntSwMidIndSta_RHD 3;
BA_REL_ "GenSigTimeoutTime" BU_SG_REL_ ATS SG_ 1080 RL_SHVU_VntSwMidIndSta_RHD 1500;
BA_REL_ "GenSigTimeoutTime" BU_SG_REL_ CGW_CCU SG_ 1080 RL_SHVU_VntSwMidIndSta_RHD 1500;
BA_ "NetworkRequest" SG_ 1080 RL_SHVU_VntSwMidIndSta_RHD 0;
BA_ "NetworkRequestHoldingTime" SG_ 1080 RL_SHVU_VntSwMidIndSta_RHD 5000;
BA_ "Version" SG_ 1080 RL_SHVU_VntSwMidIndSta_RHD "19.08.05";
BA_ "Description" SG_ 1080 RL_SHVU_VntSwLowIndSta_RHD "RL 시트 통풍 스위치 Low Indicator 정보 (RHD)

-2nd LH Seat vent low Information";
BA_ "GenSigSendType" SG_ 1080 RL_SHVU_VntSwLowIndSta_RHD 4;
BA_ "UserSigValidity" SG_ 1080 RL_SHVU_VntSwLowIndSta_RHD 3;
BA_REL_ "GenSigTimeoutTime" BU_SG_REL_ ATS SG_ 1080 RL_SHVU_VntSwLowIndSta_RHD 1500;
BA_REL_ "GenSigTimeoutTime" BU_SG_REL_ CGW_CCU SG_ 1080 RL_SHVU_VntSwLowIndSta_RHD 1500;
BA_ "NetworkRequest" SG_ 1080 RL_SHVU_VntSwLowIndSta_RHD 0;
BA_ "NetworkRequestHoldingTime" SG_ 1080 RL_SHVU_VntSwLowIndSta_RHD 5000;
BA_ "Version" SG_ 1080 RL_SHVU_VntSwLowIndSta_RHD "19.08.05";
BA_ "Description" SG_ 1080 RL_SHVU_SeatHtFail "후석 LH 시트 FailSafe 발생 상태";
BA_ "GenSigSendType" SG_ 1080 RL_SHVU_SeatHtFail 4;
BA_ "UserSigValidity" SG_ 1080 RL_SHVU_SeatHtFail 3;
BA_REL_ "GenSigTimeoutTime" BU_SG_REL_ ATS SG_ 1080 RL_SHVU_SeatHtFail 1500;
BA_REL_ "GenSigTimeoutTime" BU_SG_REL_ CGW_CCU SG_ 1080 RL_SHVU_SeatHtFail 1500;
BA_REL_ "GenSigTimeoutTime" BU_SG_REL_ CGW_CCU SG_ 1080 RL_SHVU_SeatHtFail 1500;
BA_ "NetworkRequest" SG_ 1080 RL_SHVU_SeatHtFail 0;
BA_ "NetworkRequestHoldingTime" SG_ 1080 RL_SHVU_SeatHtFail 5000;
BA_ "Version" SG_ 1080 RL_SHVU_SeatHtFail "17.12.03";
BA_ "GenMsgSendType" BO_ 1070 0;
BA_ "Description" SG_ 1070 RL_SHVU_HtSwHiIndSta "RL 시트 열선 스위치 High Indicator 정보

-2nd LH Seat heater high Information";
BA_ "GenSigSendType" SG_ 1070 RL_SHVU_HtSwHiIndSta 4;
BA_ "UserSigValidity" SG_ 1070 RL_SHVU_HtSwHiIndSta 3;
BA_REL_ "GenSigTimeoutTime" BU_SG_REL_ ATS SG_ 1070 RL_SHVU_HtSwHiIndSta 1500;
BA_REL_ "GenSigTimeoutTime" BU_SG_REL_ CGW_CCU SG_ 1070 RL_SHVU_HtSwHiIndSta 1500;
BA_ "NetworkRequest" SG_ 1070 RL_SHVU_HtSwHiIndSta 0;
BA_ "NetworkRequestHoldingTime" SG_ 1070 RL_SHVU_HtSwHiIndSta 5000;
BA_ "Version" SG_ 1070 RL_SHVU_HtSwHiIndSta "18.12.08";
BA_ "Description" SG_ 1070 RL_SHVU_HtSwMidIndSta "RL 시트 열선 스위치 Mid Indicator 정보

-2nd LH Seat heater mid Information";
BA_ "GenSigSendType" SG_ 1070 RL_SHVU_HtSwMidIndSta 4;
BA_ "UserSigValidity" SG_ 1070 RL_SHVU_HtSwMidIndSta 3;
BA_REL_ "GenSigTimeoutTime" BU_SG_REL_ ATS SG_ 1070 RL_SHVU_HtSwMidIndSta 1500;
BA_REL_ "GenSigTimeoutTime" BU_SG_REL_ CGW_CCU SG_ 1070 RL_SHVU_HtSwMidIndSta 1500;
BA_ "NetworkRequest" SG_ 1070 RL_SHVU_HtSwMidIndSta 0;
BA_ "NetworkRequestHoldingTime" SG_ 1070 RL_SHVU_HtSwMidIndSta 5000;
BA_ "Version" SG_ 1070 RL_SHVU_HtSwMidIndSta "18.12.08";
BA_ "Description" SG_ 1070 RL_SHVU_HtSwLowIndSta "RL 시트 열선 스위치 Low Indicator 정보

-2nd LH Seat heater low Information";
BA_ "GenSigSendType" SG_ 1070 RL_SHVU_HtSwLowIndSta 4;
BA_ "UserSigValidity" SG_ 1070 RL_SHVU_HtSwLowIndSta 3;
BA_REL_ "GenSigTimeoutTime" BU_SG_REL_ ATS SG_ 1070 RL_SHVU_HtSwLowIndSta 1500;
BA_REL_ "GenSigTimeoutTime" BU_SG_REL_ CGW_CCU SG_ 1070 RL_SHVU_HtSwLowIndSta 1500;
BA_ "NetworkRequest" SG_ 1070 RL_SHVU_HtSwLowIndSta 0;
BA_ "NetworkRequestHoldingTime" SG_ 1070 RL_SHVU_HtSwLowIndSta 5000;
BA_ "Version" SG_ 1070 RL_SHVU_HtSwLowIndSta "18.12.08";
BA_ "Description" SG_ 1070 RL_SHVU_VntSwHiIndSta "RL 시트 통풍 스위치 High Indicator 정보

-2nd LH Seat vent high Information";
BA_ "GenSigSendType" SG_ 1070 RL_SHVU_VntSwHiIndSta 4;
BA_ "UserSigValidity" SG_ 1070 RL_SHVU_VntSwHiIndSta 3;
BA_REL_ "GenSigTimeoutTime" BU_SG_REL_ ATS SG_ 1070 RL_SHVU_VntSwHiIndSta 1500;
BA_REL_ "GenSigTimeoutTime" BU_SG_REL_ CGW_CCU SG_ 1070 RL_SHVU_VntSwHiIndSta 1500;
BA_ "NetworkRequest" SG_ 1070 RL_SHVU_VntSwHiIndSta 0;
BA_ "NetworkRequestHoldingTime" SG_ 1070 RL_SHVU_VntSwHiIndSta 5000;
BA_ "Version" SG_ 1070 RL_SHVU_VntSwHiIndSta "18.12.08";
BA_ "Description" SG_ 1070 RL_SHVU_VntSwMidIndSta "RL 시트 통풍 스위치 Mid Indicator 정보

-2nd LH Seat vent mid Information";
BA_ "GenSigSendType" SG_ 1070 RL_SHVU_VntSwMidIndSta 4;
BA_ "UserSigValidity" SG_ 1070 RL_SHVU_VntSwMidIndSta 3;
BA_REL_ "GenSigTimeoutTime" BU_SG_REL_ ATS SG_ 1070 RL_SHVU_VntSwMidIndSta 1500;
BA_REL_ "GenSigTimeoutTime" BU_SG_REL_ CGW_CCU SG_ 1070 RL_SHVU_VntSwMidIndSta 1500;
BA_ "NetworkRequest" SG_ 1070 RL_SHVU_VntSwMidIndSta 0;
BA_ "NetworkRequestHoldingTime" SG_ 1070 RL_SHVU_VntSwMidIndSta 5000;
BA_ "Version" SG_ 1070 RL_SHVU_VntSwMidIndSta "18.12.08";
BA_ "Description" SG_ 1070 RL_SHVU_VntSwLowIndSta "RL 시트 통풍 스위치 Low Indicator 정보

-2nd LH Seat vent low Information";
BA_ "GenSigSendType" SG_ 1070 RL_SHVU_VntSwLowIndSta 4;
BA_ "UserSigValidity" SG_ 1070 RL_SHVU_VntSwLowIndSta 3;
BA_REL_ "GenSigTimeoutTime" BU_SG_REL_ ATS SG_ 1070 RL_SHVU_VntSwLowIndSta 1500;
BA_REL_ "GenSigTimeoutTime" BU_SG_REL_ CGW_CCU SG_ 1070 RL_SHVU_VntSwLowIndSta 1500;
BA_ "NetworkRequest" SG_ 1070 RL_SHVU_VntSwLowIndSta 0;
BA_ "NetworkRequestHoldingTime" SG_ 1070 RL_SHVU_VntSwLowIndSta 5000;
BA_ "Version" SG_ 1070 RL_SHVU_VntSwLowIndSta "18.12.08";
BA_ "Description" SG_ 1070 RL_SHVU_HtBlcUsmSta "RL Seat Heater Balance Status";
BA_ "GenSigSendType" SG_ 1070 RL_SHVU_HtBlcUsmSta 4;
BA_ "UserSigValidity" SG_ 1070 RL_SHVU_HtBlcUsmSta 3;
BA_REL_ "GenSigTimeoutTime" BU_SG_REL_ ATS SG_ 1070 RL_SHVU_HtBlcUsmSta 1500;
BA_REL_ "GenSigTimeoutTime" BU_SG_REL_ CGW_CCU SG_ 1070 RL_SHVU_HtBlcUsmSta 1500;
BA_ "NetworkRequest" SG_ 1070 RL_SHVU_HtBlcUsmSta 0;
BA_ "NetworkRequestHoldingTime" SG_ 1070 RL_SHVU_HtBlcUsmSta 5000;
BA_ "Version" SG_ 1070 RL_SHVU_HtBlcUsmSta "20.01.02";
BA_ "GenMsgCycleTime" BO_ 599 0;
BA_ "GenSigSendType" SG_ 599 RRPSM_AvWtcMemReq 4;
BA_ "UserSigValidity" SG_ 599 RRPSM_AvWtcMemReq 3;
BA_REL_ "GenSigTimeoutTime" BU_SG_REL_ ATS SG_ 599 RRPSM_AvWtcMemReq 0;
BA_ "NetworkRequest" SG_ 599 RRPSM_AvWtcMemReq 0;
BA_ "NetworkRequestHoldingTime" SG_ 599 RRPSM_AvWtcMemReq 5000;
BA_ "Version" SG_ 599 RRPSM_AvWtcMemReq "21.06.11";
BA_ "GenSigSendType" SG_ 599 RRPSM_RearModeWngDisforATS 4;
BA_ "UserSigValidity" SG_ 599 RRPSM_RearModeWngDisforATS 0;
BA_REL_ "GenSigTimeoutTime" BU_SG_REL_ ATS SG_ 599 RRPSM_RearModeWngDisforATS 0;
BA_ "NetworkRequest" SG_ 599 RRPSM_RearModeWngDisforATS 0;
BA_ "NetworkRequestHoldingTime" SG_ 599 RRPSM_RearModeWngDisforATS 5000;
BA_ "Version" SG_ 599 RRPSM_RearModeWngDisforATS "21.08.01";
BA_ "GenSigSendType" SG_ 599 RRPSM_ReadingMemReq 4;
BA_ "UserSigValidity" SG_ 599 RRPSM_ReadingMemReq 3;
BA_REL_ "GenSigTimeoutTime" BU_SG_REL_ ATS SG_ 599 RRPSM_ReadingMemReq 0;
BA_ "NetworkRequest" SG_ 599 RRPSM_ReadingMemReq 0;
BA_ "NetworkRequestHoldingTime" SG_ 599 RRPSM_ReadingMemReq 5000;
BA_ "Version" SG_ 599 RRPSM_ReadingMemReq "21.06.11";
BA_ "GenSigSendType" SG_ 599 RRPSM_RestMemReq 4;
BA_ "UserSigValidity" SG_ 599 RRPSM_RestMemReq 3;
BA_REL_ "GenSigTimeoutTime" BU_SG_REL_ ATS SG_ 599 RRPSM_RestMemReq 0;
BA_ "NetworkRequest" SG_ 599 RRPSM_RestMemReq 0;
BA_ "NetworkRequestHoldingTime" SG_ 599 RRPSM_RestMemReq 5000;
BA_ "Version" SG_ 599 RRPSM_RestMemReq "21.06.11";
BA_ "GenSigSendType" SG_ 599 RRPSM_ReturnMemReq 4;
BA_ "UserSigValidity" SG_ 599 RRPSM_ReturnMemReq 3;
BA_REL_ "GenSigTimeoutTime" BU_SG_REL_ ATS SG_ 599 RRPSM_ReturnMemReq 0;
BA_ "NetworkRequest" SG_ 599 RRPSM_ReturnMemReq 0;
BA_ "NetworkRequestHoldingTime" SG_ 599 RRPSM_ReturnMemReq 5000;
BA_ "Version" SG_ 599 RRPSM_ReturnMemReq "21.06.11";
BA_ "GenSigSendType" SG_ 599 RRPSM_RearModeWngDis 4;
BA_ "UserSigValidity" SG_ 599 RRPSM_RearModeWngDis 1;
BA_REL_ "GenSigTimeoutTime" BU_SG_REL_ CGW_CCU SG_ 599 RRPSM_RearModeWngDis 0;
BA_ "NetworkRequest" SG_ 599 RRPSM_RearModeWngDis 0;
BA_ "NetworkRequestHoldingTime" SG_ 599 RRPSM_RearModeWngDis 5000;
BA_ "Version" SG_ 599 RRPSM_RearModeWngDis "21.08.01";
BA_ "GenMsgSendType" BO_ 127 0;
BA_ "Description" SG_ 127 RRPSS_Local_Crc1Val "The data area for CRC calculation is based on the data length (DLC) of the message DB.

The CRC shall be calculated over the entire data block (excluding the CRC bytes) including the user data, alive counter and Data ID 

 

- CRC Polynomial (0x1D) , Initial Value : 0x00, XOR value : 0xFF, Data ID Mode : Both, Data ID : Message ID + 0xF800 

- The initial value is for CRC calculation and the message should be sent with the calculated result value. 

The mathematical expression to 8 bit CRC polynomial is given here. G(x) = x8 + x4 + x3 + x2 + 1";
BA_ "GenSigSendType" SG_ 127 RRPSS_Local_Crc1Val 4;
BA_ "GenSigStartValue" SG_ 127 RRPSS_Local_Crc1Val 255;
BA_ "UserSigValidity" SG_ 127 RRPSS_Local_Crc1Val 0;
BA_REL_ "GenSigTimeoutTime" BU_SG_REL_ CGW_CCU SG_ 127 RRPSS_Local_Crc1Val 1500;
BA_ "Version" SG_ 127 RRPSS_Local_Crc1Val "19.12.07";
BA_ "Description" SG_ 127 RRPSS_Local_AlvCnt1Val "For the first transmission request for a data element the counter shall be initialized with 0 and shall be incremented by 1

for every subsequent send request. When the counter reaches the maximum value(0xE), then it shall restart with 0 for the next send request";
BA_ "GenSigSendType" SG_ 127 RRPSS_Local_AlvCnt1Val 4;
BA_ "UserSigValidity" SG_ 127 RRPSS_Local_AlvCnt1Val 0;
BA_REL_ "GenSigTimeoutTime" BU_SG_REL_ CGW_CCU SG_ 127 RRPSS_Local_AlvCnt1Val 1500;
BA_ "Version" SG_ 127 RRPSS_Local_AlvCnt1Val "19.12.07";
BA_ "Description" SG_ 127 RRPSS_L_StSldFwdMvBtn "RRPSS_SlideForwardMoveButton";
BA_ "GenSigSendType" SG_ 127 RRPSS_L_StSldFwdMvBtn 4;
BA_ "UserSigValidity" SG_ 127 RRPSS_L_StSldFwdMvBtn 0;
BA_REL_ "GenSigTimeoutTime" BU_SG_REL_ ATS SG_ 127 RRPSS_L_StSldFwdMvBtn 1500;
BA_REL_ "GenSigTimeoutTime" BU_SG_REL_ CGW_CCU SG_ 127 RRPSS_L_StSldFwdMvBtn 1500;
BA_ "NetworkRequest" SG_ 127 RRPSS_L_StSldFwdMvBtn 0;
BA_ "NetworkRequestHoldingTime" SG_ 127 RRPSS_L_StSldFwdMvBtn 5000;
BA_ "Version" SG_ 127 RRPSS_L_StSldFwdMvBtn "19.12.07";
BA_ "Description" SG_ 127 RRPSS_L_StSldBwdMvBtn "RRPSS_SlideBackwardMoveButton";
BA_ "GenSigSendType" SG_ 127 RRPSS_L_StSldBwdMvBtn 4;
BA_ "UserSigValidity" SG_ 127 RRPSS_L_StSldBwdMvBtn 0;
BA_REL_ "GenSigTimeoutTime" BU_SG_REL_ ATS SG_ 127 RRPSS_L_StSldBwdMvBtn 1500;
BA_REL_ "GenSigTimeoutTime" BU_SG_REL_ CGW_CCU SG_ 127 RRPSS_L_StSldBwdMvBtn 1500;
BA_ "NetworkRequest" SG_ 127 RRPSS_L_StSldBwdMvBtn 0;
BA_ "NetworkRequestHoldingTime" SG_ 127 RRPSS_L_StSldBwdMvBtn 5000;
BA_ "Version" SG_ 127 RRPSS_L_StSldBwdMvBtn "19.12.07";
BA_ "Description" SG_ 127 RRPSS_L_StRclFwdMvBtn "RRPSS_ReclinerForwardMoveButton";
BA_ "GenSigSendType" SG_ 127 RRPSS_L_StRclFwdMvBtn 4;
BA_ "UserSigValidity" SG_ 127 RRPSS_L_StRclFwdMvBtn 0;
BA_REL_ "GenSigTimeoutTime" BU_SG_REL_ ATS SG_ 127 RRPSS_L_StRclFwdMvBtn 1500;
BA_REL_ "GenSigTimeoutTime" BU_SG_REL_ CGW_CCU SG_ 127 RRPSS_L_StRclFwdMvBtn 1500;
BA_ "NetworkRequest" SG_ 127 RRPSS_L_StRclFwdMvBtn 0;
BA_ "NetworkRequestHoldingTime" SG_ 127 RRPSS_L_StRclFwdMvBtn 5000;
BA_ "Version" SG_ 127 RRPSS_L_StRclFwdMvBtn "19.12.07";
BA_ "Description" SG_ 127 RRPSS_L_StRclBwdMvBtn "RRPSS_ReclinerBackwardMoveButton";
BA_ "GenSigSendType" SG_ 127 RRPSS_L_StRclBwdMvBtn 4;
BA_ "UserSigValidity" SG_ 127 RRPSS_L_StRclBwdMvBtn 0;
BA_REL_ "GenSigTimeoutTime" BU_SG_REL_ ATS SG_ 127 RRPSS_L_StRclBwdMvBtn 1500;
BA_REL_ "GenSigTimeoutTime" BU_SG_REL_ CGW_CCU SG_ 127 RRPSS_L_StRclBwdMvBtn 1500;
BA_ "NetworkRequest" SG_ 127 RRPSS_L_StRclBwdMvBtn 0;
BA_ "NetworkRequestHoldingTime" SG_ 127 RRPSS_L_StRclBwdMvBtn 5000;
BA_ "Version" SG_ 127 RRPSS_L_StRclBwdMvBtn "19.12.07";
BA_ "Description" SG_ 127 RRPSS_L_StTltUpMvBtn "RRPSS_TiltUpMoveButton";
BA_ "GenSigSendType" SG_ 127 RRPSS_L_StTltUpMvBtn 4;
BA_ "UserSigValidity" SG_ 127 RRPSS_L_StTltUpMvBtn 0;
BA_REL_ "GenSigTimeoutTime" BU_SG_REL_ ATS SG_ 127 RRPSS_L_StTltUpMvBtn 1500;
BA_REL_ "GenSigTimeoutTime" BU_SG_REL_ CGW_CCU SG_ 127 RRPSS_L_StTltUpMvBtn 1500;
BA_ "NetworkRequest" SG_ 127 RRPSS_L_StTltUpMvBtn 0;
BA_ "NetworkRequestHoldingTime" SG_ 127 RRPSS_L_StTltUpMvBtn 5000;
BA_ "Version" SG_ 127 RRPSS_L_StTltUpMvBtn "19.12.07";
BA_ "Description" SG_ 127 RRPSS_L_StTltDnMvBtn "RRPSS_TiltDownMoveButton";
BA_ "GenSigSendType" SG_ 127 RRPSS_L_StTltDnMvBtn 4;
BA_ "UserSigValidity" SG_ 127 RRPSS_L_StTltDnMvBtn 0;
BA_REL_ "GenSigTimeoutTime" BU_SG_REL_ ATS SG_ 127 RRPSS_L_StTltDnMvBtn 1500;
BA_REL_ "GenSigTimeoutTime" BU_SG_REL_ CGW_CCU SG_ 127 RRPSS_L_StTltDnMvBtn 1500;
BA_ "NetworkRequest" SG_ 127 RRPSS_L_StTltDnMvBtn 0;
BA_ "NetworkRequestHoldingTime" SG_ 127 RRPSS_L_StTltDnMvBtn 5000;
BA_ "Version" SG_ 127 RRPSS_L_StTltDnMvBtn "19.12.07";
BA_ "Description" SG_ 127 RRPSS_L_StHRestUpMvBtn "RRPSS_Head Rest UpMoveButton";
BA_ "GenSigSendType" SG_ 127 RRPSS_L_StHRestUpMvBtn 4;
BA_ "UserSigValidity" SG_ 127 RRPSS_L_StHRestUpMvBtn 0;
BA_REL_ "GenSigTimeoutTime" BU_SG_REL_ ATS SG_ 127 RRPSS_L_StHRestUpMvBtn 1500;
BA_REL_ "GenSigTimeoutTime" BU_SG_REL_ CGW_CCU SG_ 127 RRPSS_L_StHRestUpMvBtn 1500;
BA_ "NetworkRequest" SG_ 127 RRPSS_L_StHRestUpMvBtn 0;
BA_ "NetworkRequestHoldingTime" SG_ 127 RRPSS_L_StHRestUpMvBtn 5000;
BA_ "Version" SG_ 127 RRPSS_L_StHRestUpMvBtn "19.12.07";
BA_ "Description" SG_ 127 RRPSS_L_StHRestDnMvBtn "RRPSS_Head Rest DownMoveButton";
BA_ "GenSigSendType" SG_ 127 RRPSS_L_StHRestDnMvBtn 4;
BA_ "UserSigValidity" SG_ 127 RRPSS_L_StHRestDnMvBtn 0;
BA_REL_ "GenSigTimeoutTime" BU_SG_REL_ ATS SG_ 127 RRPSS_L_StHRestDnMvBtn 1500;
BA_REL_ "GenSigTimeoutTime" BU_SG_REL_ CGW_CCU SG_ 127 RRPSS_L_StHRestDnMvBtn 1500;
BA_ "NetworkRequest" SG_ 127 RRPSS_L_StHRestDnMvBtn 0;
BA_ "NetworkRequestHoldingTime" SG_ 127 RRPSS_L_StHRestDnMvBtn 5000;
BA_ "Version" SG_ 127 RRPSS_L_StHRestDnMvBtn "19.12.07";
BA_ "Description" SG_ 127 RRPSS_L_StHRestFwdMvBtn "RRPSS_Head Rest ForwardMoveButton";
BA_ "GenSigSendType" SG_ 127 RRPSS_L_StHRestFwdMvBtn 4;
BA_ "UserSigValidity" SG_ 127 RRPSS_L_StHRestFwdMvBtn 0;
BA_REL_ "GenSigTimeoutTime" BU_SG_REL_ ATS SG_ 127 RRPSS_L_StHRestFwdMvBtn 1500;
BA_REL_ "GenSigTimeoutTime" BU_SG_REL_ CGW_CCU SG_ 127 RRPSS_L_StHRestFwdMvBtn 1500;
BA_ "NetworkRequest" SG_ 127 RRPSS_L_StHRestFwdMvBtn 0;
BA_ "NetworkRequestHoldingTime" SG_ 127 RRPSS_L_StHRestFwdMvBtn 5000;
BA_ "Version" SG_ 127 RRPSS_L_StHRestFwdMvBtn "19.12.07";
BA_ "Description" SG_ 127 RRPSS_L_StHRestBwdMvBtn "RRPSS_Head Rest BackwardMoveButton";
BA_ "GenSigSendType" SG_ 127 RRPSS_L_StHRestBwdMvBtn 4;
BA_ "UserSigValidity" SG_ 127 RRPSS_L_StHRestBwdMvBtn 0;
BA_REL_ "GenSigTimeoutTime" BU_SG_REL_ ATS SG_ 127 RRPSS_L_StHRestBwdMvBtn 1500;
BA_REL_ "GenSigTimeoutTime" BU_SG_REL_ CGW_CCU SG_ 127 RRPSS_L_StHRestBwdMvBtn 1500;
BA_ "NetworkRequest" SG_ 127 RRPSS_L_StHRestBwdMvBtn 0;
BA_ "NetworkRequestHoldingTime" SG_ 127 RRPSS_L_StHRestBwdMvBtn 5000;
BA_ "Version" SG_ 127 RRPSS_L_StHRestBwdMvBtn "19.12.07";
BA_ "Description" SG_ 127 RRPSS_L_StLegRestUpBtn "RRPSS_Leg Rest Up Move Button";
BA_ "GenSigSendType" SG_ 127 RRPSS_L_StLegRestUpBtn 4;
BA_ "UserSigValidity" SG_ 127 RRPSS_L_StLegRestUpBtn 0;
BA_REL_ "GenSigTimeoutTime" BU_SG_REL_ ATS SG_ 127 RRPSS_L_StLegRestUpBtn 1500;
BA_REL_ "GenSigTimeoutTime" BU_SG_REL_ CGW_CCU SG_ 127 RRPSS_L_StLegRestUpBtn 1500;
BA_ "NetworkRequest" SG_ 127 RRPSS_L_StLegRestUpBtn 0;
BA_ "NetworkRequestHoldingTime" SG_ 127 RRPSS_L_StLegRestUpBtn 5000;
BA_ "Version" SG_ 127 RRPSS_L_StLegRestUpBtn "20.08.07";
BA_ "Description" SG_ 127 RRPSS_L_StLegRestDnBtn "RRPSS_Leg Rest Down Move Button";
BA_ "GenSigSendType" SG_ 127 RRPSS_L_StLegRestDnBtn 4;
BA_ "UserSigValidity" SG_ 127 RRPSS_L_StLegRestDnBtn 0;
BA_REL_ "GenSigTimeoutTime" BU_SG_REL_ ATS SG_ 127 RRPSS_L_StLegRestDnBtn 1500;
BA_REL_ "GenSigTimeoutTime" BU_SG_REL_ CGW_CCU SG_ 127 RRPSS_L_StLegRestDnBtn 1500;
BA_ "NetworkRequest" SG_ 127 RRPSS_L_StLegRestDnBtn 0;
BA_ "NetworkRequestHoldingTime" SG_ 127 RRPSS_L_StLegRestDnBtn 5000;
BA_ "Version" SG_ 127 RRPSS_L_StLegRestDnBtn "20.08.07";
BA_ "Description" SG_ 127 RRPSS_L_StLegRestExtUpBtn "RRPSS_Leg Support Forward Move Button";
BA_ "GenSigSendType" SG_ 127 RRPSS_L_StLegRestExtUpBtn 4;
BA_ "UserSigValidity" SG_ 127 RRPSS_L_StLegRestExtUpBtn 0;
BA_REL_ "GenSigTimeoutTime" BU_SG_REL_ ATS SG_ 127 RRPSS_L_StLegRestExtUpBtn 1500;
BA_REL_ "GenSigTimeoutTime" BU_SG_REL_ CGW_CCU SG_ 127 RRPSS_L_StLegRestExtUpBtn 1500;
BA_ "NetworkRequest" SG_ 127 RRPSS_L_StLegRestExtUpBtn 0;
BA_ "NetworkRequestHoldingTime" SG_ 127 RRPSS_L_StLegRestExtUpBtn 5000;
BA_ "Version" SG_ 127 RRPSS_L_StLegRestExtUpBtn "20.08.07";
BA_ "Description" SG_ 127 RRPSS_L_StLegRestExtDnBtn "RRPSS_Leg Support Backward Move Button";
BA_ "GenSigSendType" SG_ 127 RRPSS_L_StLegRestExtDnBtn 4;
BA_ "UserSigValidity" SG_ 127 RRPSS_L_StLegRestExtDnBtn 0;
BA_REL_ "GenSigTimeoutTime" BU_SG_REL_ ATS SG_ 127 RRPSS_L_StLegRestExtDnBtn 1500;
BA_REL_ "GenSigTimeoutTime" BU_SG_REL_ CGW_CCU SG_ 127 RRPSS_L_StLegRestExtDnBtn 1500;
BA_ "NetworkRequest" SG_ 127 RRPSS_L_StLegRestExtDnBtn 0;
BA_ "NetworkRequestHoldingTime" SG_ 127 RRPSS_L_StLegRestExtDnBtn 5000;
BA_ "Version" SG_ 127 RRPSS_L_StLegRestExtDnBtn "20.08.07";
BA_ "GenMsgSendType" BO_ 1071 0;
BA_ "Description" SG_ 1071 RR_SHVU_HtSwHiIndSta "RR 시트 열선 스위치 High Indicator 정보

-2nd RH Seat heater high Information";
BA_ "GenSigSendType" SG_ 1071 RR_SHVU_HtSwHiIndSta 4;
BA_ "UserSigValidity" SG_ 1071 RR_SHVU_HtSwHiIndSta 3;
BA_REL_ "GenSigTimeoutTime" BU_SG_REL_ ATS SG_ 1071 RR_SHVU_HtSwHiIndSta 1500;
BA_REL_ "GenSigTimeoutTime" BU_SG_REL_ CGW_CCU SG_ 1071 RR_SHVU_HtSwHiIndSta 1500;
BA_ "NetworkRequest" SG_ 1071 RR_SHVU_HtSwHiIndSta 0;
BA_ "NetworkRequestHoldingTime" SG_ 1071 RR_SHVU_HtSwHiIndSta 5000;
BA_ "Version" SG_ 1071 RR_SHVU_HtSwHiIndSta "18.12.08";
BA_ "Description" SG_ 1071 RR_SHVU_HtSwMidIndSta "RL 시트 열선 스위치 Mid Indicator 정보

-2nd LH Seat heater mid Information";
BA_ "GenSigSendType" SG_ 1071 RR_SHVU_HtSwMidIndSta 4;
BA_ "UserSigValidity" SG_ 1071 RR_SHVU_HtSwMidIndSta 3;
BA_REL_ "GenSigTimeoutTime" BU_SG_REL_ ATS SG_ 1071 RR_SHVU_HtSwMidIndSta 1500;
BA_REL_ "GenSigTimeoutTime" BU_SG_REL_ CGW_CCU SG_ 1071 RR_SHVU_HtSwMidIndSta 1500;
BA_ "NetworkRequest" SG_ 1071 RR_SHVU_HtSwMidIndSta 0;
BA_ "NetworkRequestHoldingTime" SG_ 1071 RR_SHVU_HtSwMidIndSta 5000;
BA_ "Version" SG_ 1071 RR_SHVU_HtSwMidIndSta "18.12.08";
BA_ "Description" SG_ 1071 RR_SHVU_HtSwLowIndSta "RR 시트 열선 스위치 Low Indicator 정보

-2nd RH Seat heater low Information";
BA_ "GenSigSendType" SG_ 1071 RR_SHVU_HtSwLowIndSta 4;
BA_ "UserSigValidity" SG_ 1071 RR_SHVU_HtSwLowIndSta 3;
BA_REL_ "GenSigTimeoutTime" BU_SG_REL_ ATS SG_ 1071 RR_SHVU_HtSwLowIndSta 1500;
BA_REL_ "GenSigTimeoutTime" BU_SG_REL_ CGW_CCU SG_ 1071 RR_SHVU_HtSwLowIndSta 1500;
BA_ "NetworkRequest" SG_ 1071 RR_SHVU_HtSwLowIndSta 0;
BA_ "NetworkRequestHoldingTime" SG_ 1071 RR_SHVU_HtSwLowIndSta 5000;
BA_ "Version" SG_ 1071 RR_SHVU_HtSwLowIndSta "18.12.08";
BA_ "Description" SG_ 1071 RR_SHVU_VntSwHiIndSta "RR 시트 통풍 스위치 High Indicator 정보

-2nd RH Seat vent high Information";
BA_ "GenSigSendType" SG_ 1071 RR_SHVU_VntSwHiIndSta 4;
BA_ "UserSigValidity" SG_ 1071 RR_SHVU_VntSwHiIndSta 3;
BA_REL_ "GenSigTimeoutTime" BU_SG_REL_ ATS SG_ 1071 RR_SHVU_VntSwHiIndSta 1500;
BA_REL_ "GenSigTimeoutTime" BU_SG_REL_ CGW_CCU SG_ 1071 RR_SHVU_VntSwHiIndSta 1500;
BA_ "NetworkRequest" SG_ 1071 RR_SHVU_VntSwHiIndSta 0;
BA_ "NetworkRequestHoldingTime" SG_ 1071 RR_SHVU_VntSwHiIndSta 5000;
BA_ "Version" SG_ 1071 RR_SHVU_VntSwHiIndSta "18.12.08";
BA_ "Description" SG_ 1071 RR_SHVU_VntSwMidIndSta "RR 시트 통풍 스위치 Mid Indicator 정보

-2nd RH Seat vent mid Information";
BA_ "GenSigSendType" SG_ 1071 RR_SHVU_VntSwMidIndSta 4;
BA_ "UserSigValidity" SG_ 1071 RR_SHVU_VntSwMidIndSta 3;
BA_REL_ "GenSigTimeoutTime" BU_SG_REL_ ATS SG_ 1071 RR_SHVU_VntSwMidIndSta 1500;
BA_REL_ "GenSigTimeoutTime" BU_SG_REL_ CGW_CCU SG_ 1071 RR_SHVU_VntSwMidIndSta 1500;
BA_ "NetworkRequest" SG_ 1071 RR_SHVU_VntSwMidIndSta 0;
BA_ "NetworkRequestHoldingTime" SG_ 1071 RR_SHVU_VntSwMidIndSta 5000;
BA_ "Version" SG_ 1071 RR_SHVU_VntSwMidIndSta "18.12.08";
BA_ "Description" SG_ 1071 RR_SHVU_VntSwLowIndSta "RR 시트 통풍 스위치 Low Indicator 정보

-2nd RH Seat vent low Information";
BA_ "GenSigSendType" SG_ 1071 RR_SHVU_VntSwLowIndSta 4;
BA_ "UserSigValidity" SG_ 1071 RR_SHVU_VntSwLowIndSta 3;
BA_REL_ "GenSigTimeoutTime" BU_SG_REL_ ATS SG_ 1071 RR_SHVU_VntSwLowIndSta 1500;
BA_REL_ "GenSigTimeoutTime" BU_SG_REL_ CGW_CCU SG_ 1071 RR_SHVU_VntSwLowIndSta 1500;
BA_ "NetworkRequest" SG_ 1071 RR_SHVU_VntSwLowIndSta 0;
BA_ "NetworkRequestHoldingTime" SG_ 1071 RR_SHVU_VntSwLowIndSta 5000;
BA_ "Version" SG_ 1071 RR_SHVU_VntSwLowIndSta "18.12.08";
BA_ "Description" SG_ 1071 RR_SHVU_HtBlcUsmSta "RR Seat Heater Balance Status";
BA_ "GenSigSendType" SG_ 1071 RR_SHVU_HtBlcUsmSta 4;
BA_ "UserSigValidity" SG_ 1071 RR_SHVU_HtBlcUsmSta 3;
BA_REL_ "GenSigTimeoutTime" BU_SG_REL_ ATS SG_ 1071 RR_SHVU_HtBlcUsmSta 1500;
BA_REL_ "GenSigTimeoutTime" BU_SG_REL_ CGW_CCU SG_ 1071 RR_SHVU_HtBlcUsmSta 1500;
BA_ "NetworkRequest" SG_ 1071 RR_SHVU_HtBlcUsmSta 0;
BA_ "NetworkRequestHoldingTime" SG_ 1071 RR_SHVU_HtBlcUsmSta 5000;
BA_ "Version" SG_ 1071 RR_SHVU_HtBlcUsmSta "20.01.02";
BA_ "GenMsgSendType" BO_ 1073 0;
BA_ "Description" SG_ 1073 USM_ValCmdSta "USM request value of RWPC";
BA_ "GenSigSendType" SG_ 1073 USM_ValCmdSta 4;
BA_ "UserSigValidity" SG_ 1073 USM_ValCmdSta 0;
BA_REL_ "GenSigTimeoutTime" BU_SG_REL_ ATS SG_ 1073 USM_ValCmdSta 1500;
BA_REL_ "GenSigTimeoutTime" BU_SG_REL_ CGW_CCU SG_ 1073 USM_ValCmdSta 1500;
BA_ "NetworkRequest" SG_ 1073 USM_ValCmdSta 0;
BA_ "NetworkRequestHoldingTime" SG_ 1073 USM_ValCmdSta 5000;
BA_ "Version" SG_ 1073 USM_ValCmdSta "17.11.00";
BA_ "Description" SG_ 1073 RWPC_SWVerMinor1 "Indicate the RWPC software version as follows:

- The software version is displayed in three digits.

- The Major and Minor digits are separated by '.'

- Signal values are transmitted to ASCII codes.



※ Example

RWPC_SWVerMajor1 : 0x41 (HEX) -> ASCII CODE : 'A' 

RWPC_SWVerMinor1 : 0x30 (HEX) -> ASCII CODE : '0'

RWPC_SWVerMinor2 : 0x33 (HEX) -> ASCII CODE : '3'

=> RWPC S/W Ver is displayed 'A.03'";
BA_ "GenSigSendType" SG_ 1073 RWPC_SWVerMinor1 4;
BA_ "UserSigValidity" SG_ 1073 RWPC_SWVerMinor1 0;
BA_REL_ "GenSigTimeoutTime" BU_SG_REL_ CGW_CCU SG_ 1073 RWPC_SWVerMinor1 1500;
BA_ "Version" SG_ 1073 RWPC_SWVerMinor1 "18.10.06";
BA_ "Description" SG_ 1073 WPC_PhnLftWrngRWPCSta "Warning by RWPC for User (Phone left in vehicle)";
BA_ "GenSigSendType" SG_ 1073 WPC_PhnLftWrngRWPCSta 4;
BA_ "UserSigValidity" SG_ 1073 WPC_PhnLftWrngRWPCSta 0;
BA_REL_ "GenSigTimeoutTime" BU_SG_REL_ ATS SG_ 1073 WPC_PhnLftWrngRWPCSta 1500;
BA_REL_ "GenSigTimeoutTime" BU_SG_REL_ CGW_CCU SG_ 1073 WPC_PhnLftWrngRWPCSta 1500;
BA_ "NetworkRequest" SG_ 1073 WPC_PhnLftWrngRWPCSta 0;
BA_ "NetworkRequestHoldingTime" SG_ 1073 WPC_PhnLftWrngRWPCSta 5000;
BA_ "Version" SG_ 1073 WPC_PhnLftWrngRWPCSta "19.10.02";
BA_ "Description" SG_ 1073 RWPC_SWVerMinor2 "Indicate the RWPC software version as follows:

- The software version is displayed in three digits.

- The Major and Minor digits are separated by '.'

- Signal values are transmitted to ASCII codes.



※ Example

RWPC_SWVerMajor1 : 0x41 (HEX) -> ASCII CODE : 'A' 

RWPC_SWVerMinor1 : 0x30 (HEX) -> ASCII CODE : '0'

RWPC_SWVerMinor2 : 0x33 (HEX) -> ASCII CODE : '3'

=> RWPC S/W Ver is displayed 'A.03'";
BA_ "GenSigSendType" SG_ 1073 RWPC_SWVerMinor2 4;
BA_ "UserSigValidity" SG_ 1073 RWPC_SWVerMinor2 0;
BA_REL_ "GenSigTimeoutTime" BU_SG_REL_ CGW_CCU SG_ 1073 RWPC_SWVerMinor2 1500;
BA_ "Version" SG_ 1073 RWPC_SWVerMinor2 "18.10.06";
BA_ "Description" SG_ 1073 USM_ValCmdStaforATS "USM request value of RWPC for ATS";
BA_ "GenSigSendType" SG_ 1073 USM_ValCmdStaforATS 4;
BA_ "UserSigValidity" SG_ 1073 USM_ValCmdStaforATS 0;
BA_REL_ "GenSigTimeoutTime" BU_SG_REL_ ATS SG_ 1073 USM_ValCmdStaforATS 1500;
BA_ "NetworkRequest" SG_ 1073 USM_ValCmdStaforATS 0;
BA_ "NetworkRequestHoldingTime" SG_ 1073 USM_ValCmdStaforATS 5000;
BA_ "Version" SG_ 1073 USM_ValCmdStaforATS "20.07.05";
BA_ "Description" SG_ 1073 RWPC_SWVerMajor1 "Indicate the RWPC software version as follows:

- The software version is displayed in three digits.

- The Major and Minor digits are separated by '.'

- Signal values are transmitted to ASCII codes.



※ Example

RWPC_SWVerMajor1 : 0x41 (HEX) -> ASCII CODE : 'A' 

RWPC_SWVerMinor1 : 0x30 (HEX) -> ASCII CODE : '0'

RWPC_SWVerMinor2 : 0x33 (HEX) -> ASCII CODE : '3'

=> RWPC S/W Ver is displayed 'A.03'";
BA_ "GenSigSendType" SG_ 1073 RWPC_SWVerMajor1 4;
BA_ "UserSigValidity" SG_ 1073 RWPC_SWVerMajor1 0;
BA_REL_ "GenSigTimeoutTime" BU_SG_REL_ CGW_CCU SG_ 1073 RWPC_SWVerMajor1 1500;
BA_ "Version" SG_ 1073 RWPC_SWVerMajor1 "21.07.00";
VAL_ 2239849729 PA_ModDis 0 "No display" 1 "PDW display" 2 "PA display" 3 "PDW & PA display" 4 "Reserved" 5 "Reserved" 6 "Not used" 7 "Error Indicator" ;
VAL_ 2239849729 PA_ModSelSeqDis 0 "Default" 1 "Domestic" 2 "EU LHD" 3 "EU RHD" 4 "Reserved" 5 "Reserved" 6 "Not used" 7 "Error Indicator" ;
VAL_ 2239849729 PA_RSPA_Opt 0 "PA/RSPA not applied" 1 "PA/RSPA applied" 2 "Not Used" 3 "Error Indicator" ;
VAL_ 2239849729 PA_HmiStaDis 0 "No Display" 1 "Parking mode selection - right perpendicular" 2 "Parking mode selection - left perpendicular" 3 "Parking mode selection - right parallel" 4 "Parking mode selection - left parallel" 5 "Parking mode selection - OFF" 6 "Requesting go forward for detecting parking space" 7 "Detecting parking space - right perpendicular" 8 "Detecting parking space - left perpendicular" 9 "Detecting parking space - right parallel" 10 "Detecting parking space - left parallel" 13 "Requesting stop of vehicle in perpendicular parking" 14 "Requesting Steering Wheel to left side in right perpendicular parking" 15 "Requesting Steering Wheel to right side in left perpendicular parking" 17 "Finishing parking space - right perpendicular" 18 "Finishing parking space - left perpendicular" 19 "Finishing parking space - right parallel" 20 "Finishing parking space - left parallel" 23 "Automatic steering activation" 25 "Requesting gear shift to forward during automatic steering activation" 26 "Requesting gear shift to backward during automatic steering activation" 28 "Finishing automatic steering activation" 30 "System auto-canceled" 31 "System failed" 32 "Over speed of vehicle" 33 "Requesting EPB AUTO-HOLD OFF" 34 "System deactivation by TRAILER MODE" 35 "System deactivation by TCS OFF" 37 "Parking out mode selection - OFF" 38 "Parking out mode selection - left" 39 "Parking out mode selection - right" 40 "Detecting parking out space - left" 41 "Detecting parking out space - right" 42 "Requesting gear shift to backward in parking out mode after detecting parking out space" 44 "Automatic steering activation for parking out" 46 "Requesting gear shift to forward in parking out mode" 47 "Requesting gear shift to backward in parking out mode" 49 "Finishing automatic steering activation for parking out" 50 "System auto-canceled in parking out mode" 51 "Informing parking space - right perpendicular" 52 "Informing parking space - left perpendicular" 53 "Informing parking space - right parallel" 54 "Informing parking space - left parallel" 55 "Imforming remotely moving forward" 56 "Activating remotely moving forward" 57 "Finishing remotely moving forward" 58 "Pause - Fob button released" 59 "Pause - Requesting pushing button" 60 "Pause - Fob is out of boundary" 61 "Pause - Door open" 62 "Pause - Trunk open" 63 "Pause - Tailgate open" 64 "Pause - Obstacle is detected" 65 "Aborted - Moving not intended direction" 66 "Aborted - Referring to manual" 67 "Aborted - DCT temperature warning" 84 "Aborted - Steep road slope" 85 "Not working condition - Steep ascending road slope" 86 "Not working condition - Steep descending road slope" 254 "Not used" 255 "Error Indicator" ;
VAL_ 2239849729 PA_FrLtWrngDis 0 "OFF (No warning)" 1 "1’st warning level" 2 "2’nd warning level" 3 "3’nd warning level (the closest status with obstacle)" 4 "Reserved" 5 "Reserved" 6 "Not used" 7 "Error Indicator" ;
VAL_ 2239849729 PA_FrCtWrngDis 0 "OFF (No warning)" 1 "1’st warning level" 2 "2’nd warning level" 3 "3’nd warning level (the closest status with obstacle)" 4 "Reserved" 5 "Reserved" 6 "Not used" 7 "Error Indicator" ;
VAL_ 2239849729 PA_FrRtWrngDis 0 "OFF (No warning)" 1 "1’st warning level" 2 "2’nd warning level" 3 "3’nd warning level (the closest status with obstacle)" 4 "Reserved" 5 "Reserved" 6 "Not used" 7 "Error Indicator" ;
VAL_ 2239849729 PA_RrLtWrngDis 0 "OFF (No warning)" 1 "1’st warning level" 2 "2’nd warning level" 3 "3’nd warning level (the closest status with obstacle)" 4 "Reserved" 5 "Reserved" 6 "Not used" 7 "Error Indicator" ;
VAL_ 2239849729 PA_RrCtWrngDis 0 "OFF (No warning)" 1 "1’st warning level" 2 "2’nd warning level" 3 "3’nd warning level (the closest status with obstacle)" 4 "Reserved" 5 "Reserved" 6 "Not used" 7 "Error Indicator" ;
VAL_ 2239849729 PA_RrRtWrngDis 0 "OFF (No warning)" 1 "1’st warning level" 2 "2’nd warning level" 3 "3’nd warning level (the closest status with obstacle)" 4 "Reserved" 5 "Reserved" 6 "Not used" 7 "Error Indicator" ;
VAL_ 2239849730 PA_BpAlrmReq 0 "No warning alarm" 1 "PA or PDW Failure State warning alarm" 30 "Not used" 31 "Error Indicator" 3 "Change to TGS “R” warning alarm" 4 "PA parking complete warning alarm" 7 "“Stop” message during PA function warning alarm" 8 "“Scan complete” message warning" 9 "“System abort” message during PA driving warning alarm" 10 "“Gear Shift to Backward” warning alarm" 11 "“Gear Shift to Forward” warning alarm" 12 "PA parking out complete warning alarm" 14 "SMK Sound request" ;
VAL_ 2239849730 PA_FrWrngAlrmReq 0 "OFF(No warning alarm)" 1 "’st warning alarm level" 2 "2’nd warning alarm level" 3 "3’nd warning alarm level (the closest status with obstacle)" ;
VAL_ 2239849730 PA_RrWrngAlrmReq 0 "OFF(No warning alarm)" 1 "1’st warning alarm level" 2 "2’nd warning alarm level" 3 "3’nd warning alarm level (the closest status with obstacle)" ;
VAL_ 2239849730 PA_FrLtWrngAlrmReq 0 "OFF(No warning alarm)" 1 "1’st warning alarm level" 2 "2’nd warning alarm level" 3 "3’nd warning alarm level (the closest status with obstacle)" ;
VAL_ 2239849730 PA_FrCtWrngAlrmReq 0 "OFF(No warning alarm)" 1 "1’st warning alarm level" 2 "2’nd warning alarm level" 3 "3’nd warning alarm level (the closest status with obstacle)" ;
VAL_ 2239849730 PA_FrRtWrngAlrmReq 0 "OFF(No warning alarm)" 1 "1’st warning alarm level" 2 "2’nd warning alarm level" 3 "3’nd warning alarm level (the closest status with obstacle)" ;
VAL_ 2239849730 PA_RrLtWrngAlrmReq 0 "OFF(No warning alarm)" 1 "1’st warning alarm level" 2 "2’nd warning alarm level" 3 "3’nd warning alarm level (the closest status with obstacle)" ;
VAL_ 2239849730 PA_RrCtWrngAlrmReq 0 "OFF(No warning alarm)" 1 "1’st warning alarm level" 2 "2’nd warning alarm level" 3 "3’nd warning alarm level (the closest status with obstacle)" ;
VAL_ 2239849730 PA_RrRtWrngAlrmReq 0 "OFF(No warning alarm)" 1 "1’st warning alarm level" 2 "2’nd warning alarm level" 3 "3’nd warning alarm level (the closest status with obstacle)" ;
VAL_ 2239849730 PA_Sta 0 "Reserved" 1 "PA_Init" 2 "PA_NewStart" 3 "PA_Standby" 4 "PA_Active" 5 "PA_Angle_Control_Active" 6 "PA_Failure" 7 "PA_Abort" 8 "Reserved" 9 "Reserved" 10 "Reserved" 11 "Reserved" 12 "Reserved" 13 "Reserved" 14 "Not used" 15 "Error Indicator" ;
VAL_ 2239849730 PA_TestModSta 0 "PA is not in Test Mode" 1 "PA is in Test Mode" 2 "Not used" 3 "Error Indicator" ;
VAL_ 2239849730 ADAS_PRK_OptInfo 15 "Invalid" ;
VAL_ 2239849730 PA_AlrmVlmLvlReq 0 "Default" 1 "Level 1" 2 "Level 2" 3 "Level 3" 4 "Reserved" 5 "Reserved" 6 "Not used" 7 "Error Indicator" ;
VAL_ 2239849730 PA_LtFrWrngDis 0 "OFF (No warning)" 1 "1’st warning level" 2 "2’nd warning level" 3 "3’nd warning level (the closest status with obstacle)" 4 "Reserved" 5 "Reserved" 6 "Not used" 7 "Error Indicator" ;
VAL_ 2239849730 PA_RtFrWrngDis 0 "OFF (No warning)" 1 "1’st warning level" 2 "2’nd warning level" 3 "3’nd warning level (the closest status with obstacle)" 4 "Reserved" 5 "Reserved" 6 "Not used" 7 "Error Indicator" ;
VAL_ 2239849730 PA_SdWrngAlrmReq 0 "OFF(No warning alarm)" 1 "’st warning alarm level" 2 "2’nd warning alarm level" 3 "3’nd warning alarm level (the closest status with obstacle)" ;
VAL_ 2239849730 PA_AlrmVlmDeratingReq 0 "OFF (deactivation of warning alarm)" 1 "ON (activation of warning alarm)" 2 "Not used" 3 "Error Indicator" ;
VAL_ 2239849731 PA_LtWrngDis 0 "OFF (No warning)" 1 "1’st warning level" 2 "2’nd warning level" 3 "3’nd warning level (the closest status with obstacle)" 4 "Reserved" 5 "Reserved" 6 "Not used" 7 "Error Indicator" ;
VAL_ 2239849731 PA_RtRrWrngDis 0 "OFF (No warning)" 1 "1’st warning level" 2 "2’nd warning level" 3 "3’nd warning level (the closest status with obstacle)" 4 "Reserved" 5 "Reserved" 6 "Not used" 7 "Error Indicator" ;
VAL_ 2239849731 PA_SdRtWrngAlrmReq 0 "OFF(No warning alarm)" 1 "’st warning alarm level" 2 "2’nd warning alarm level" 3 "3’nd warning alarm level (the closest status with obstacle)" ;
VAL_ 2239849731 PA_RtWrngDis 0 "OFF (No warning)" 1 "1’st warning level" 2 "2’nd warning level" 3 "3’nd warning level (the closest status with obstacle)" 4 "Reserved" 5 "Reserved" 6 "Not used" 7 "Error Indicator" ;
VAL_ 2239849731 PA_SdLtWrngAlrmReq 0 "OFF(No warning alarm)" 1 "’st warning alarm level" 2 "2’nd warning alarm level" 3 "3’nd warning alarm level (the closest status with obstacle)" ;
VAL_ 2239849731 PA_LtRrWrngDis 0 "OFF (No warning)" 1 "1’st warning level" 2 "2’nd warning level" 3 "3’nd warning level (the closest status with obstacle)" 4 "Reserved" 5 "Reserved" 6 "Not used" 7 "Error Indicator" ;
VAL_ 1555 AMP_NaviVolumeState 0 "0x0x0~0xFD:Navi Volume" 253 "0x0x0~0xFD:Navi Volume" 254 "Invalid" 255 "Invalid" ;
VAL_ 1555 DATC_Beep1_OutputCh_State 0 "0x0x0000~0xFFFE:Valid" 65534 "0x0x0000~0xFFFE:Valid" 65535 "Invalid" ;
VAL_ 1555 DATC_Beep1FrequencyState 0 "RESERVED" 1 "RESERVED" 2 "RESERVED" 3 "RESERVED" 4 "RESERVED" 5 "RESERVED" 6 "RESERVED" 7 "RESERVED" 8 "RESERVED" 9 "RESERVED" 10 "RESERVED" 11 "RESERVED" 12 "RESERVED" 13 "RESERVED" 14 "RESERVED" 15 "RESERVED" 16 "RESERVED" 17 "RESERVED" 18 "RESERVED" 19 "RESERVED" 20 "0x14~0x4E20:Valid frequency of Hz" 20000 "0x14~0x4E20:Valid frequency of Hz" 20001 "0x4E21~0xFFFE:RESERVED" 65534 "0x4E21~0xFFFE:RESERVED" 65535 "Invalid" ;
VAL_ 1555 DATC_Beep1VolumeState 0 "0x0x0~0xFE:Beep1 Volume" 254 "0x0x0~0xFE:Beep1 Volume" 255 "Invalid" ;
VAL_ 1538 AMP_MTSVolumeState 0 "0x0x0~0xFD:MTS Volume" 253 "0x0x0~0xFD:MTS Volume" 254 "Invalid" 255 "Invalid" ;
VAL_ 1538 DVRS_Beep_OutputCh_State 65535 "Invalid" ;
VAL_ 1538 DVRS_BeepFrequencyState 0 "RESERVED" 1 "RESERVED" 2 "RESERVED" 3 "RESERVED" 4 "RESERVED" 5 "RESERVED" 6 "RESERVED" 7 "RESERVED" 8 "RESERVED" 9 "RESERVED" 10 "RESERVED" 11 "RESERVED" 12 "RESERVED" 13 "RESERVED" 14 "RESERVED" 15 "RESERVED" 16 "RESERVED" 17 "RESERVED" 18 "RESERVED" 19 "RESERVED" 20 "0x0014~0x4E20:Valid frequency of Hx" 20000 "0x0014~0x4E20:Valid frequency of Hx" 20001 "0x4E21~0xFFFE:RESERVED" 65534 "0x4E21~0xFFFE:RESERVED" 65535 "Invalid" ;
VAL_ 1538 DVRS_BeepVolumeState 0 "0x0x0~0xFE:DVRS Beep Volume" 254 "0x0x0~0xFE:DVRS Beep Volume" 255 "Invalid" ;
VAL_ 1539 AMP_HFVolumeState 0 "0x0x0~0xFD:HF Volume" 253 "0x0x0~0xFD:HF Volume" 254 "Invalid" 255 "Invalid" ;
VAL_ 1539 ATS_Beep_OutputCh_State 0 "0x0x0000~0xFFFE:Valid" 65534 "0x0x0000~0xFFFE:Valid" 65535 "Invalid" ;
VAL_ 1539 ATS_BeepFrequencyState 0 "" 1 "" 2 "" 3 "" 4 "" 5 "" 6 "" 7 "" 8 "" 9 "" 10 "" 11 "" 12 "" 13 "" 14 "" 15 "" 16 "" 17 "" 18 "" 19 "" 20 "0x0014~0x4E20:Valid frequency of Hz" 20000 "0x0014~0x4E20:Valid frequency of Hz" 20001 "0x4E21~0xFFFE:" 65534 "0x4E21~0xFFFE:" 65535 "Invalid" ;
VAL_ 1539 ATS_BeepVolumeState 0 "0x0x0~0xFE:ATS Beep Volume" 254 "0x0x0~0xFE:ATS Beep Volume" 255 "Invalid" ;
VAL_ 1540 AMP_MaxVolumeStep 0 "0x0x0~0xFD:Valid" 253 "0x0x0~0xFD:Valid" 254 "Invalid" 255 "Invalid" ;
VAL_ 1540 AMP_MaxFadeStep 0 "0x0x0~0xFD:Valid" 253 "0x0x0~0xFD:Valid" 254 "Invalid" 255 "Invalid" ;
VAL_ 1540 AMP_MaxBassStep 0 "0x0x0~0xFD:Valid" 253 "0x0x0~0xFD:Valid" 254 "Invalid" 255 "Invalid" ;
VAL_ 1540 AMP_MaxMidStep 0 "0x0x0~0xFD:Valid" 253 "0x0x0~0xFD:Valid" 254 "Invalid" 255 "Invalid" ;
VAL_ 1540 AMP_MaxTrebleStep 0 "0x0x0~0xFD:Valid" 253 "0x0x0~0xFD:Valid" 254 "Invalid" 255 "Invalid" ;
VAL_ 1540 AMP_MaxBalanceStep 0 "0x0x0~0xFD:Valid" 253 "0x0x0~0xFD:Valid" 254 "Invalid" 255 "Invalid" ;
VAL_ 1542 AMP_MaxBeep1VolumeState 0 "0x0x0~0xFE:Valid" 254 "0x0x0~0xFE:Valid" 255 "Invalid" ;
VAL_ 1542 AMP_CLU_InfoVolumeState 0 "0x0x0~0xFE:cluster info volume" 254 "0x0x0~0xFE:cluster info volume" 255 "Invalid" ;
VAL_ 1542 AMP_CLUinfo_OutputCh_State 65535 "Invalid" ;
VAL_ 1542 AMP_ADASVolMasterGainState 0 "0x0x0~0xFE:ADAS volume" 254 "0x0x0~0xFE:ADAS volume" 255 "Invalid" ;
VAL_ 1542 AMP_Beep1FrequencyState 0 "RESERVED" 1 "RESERVED" 2 "RESERVED" 3 "RESERVED" 4 "RESERVED" 5 "RESERVED" 6 "RESERVED" 7 "RESERVED" 8 "RESERVED" 9 "RESERVED" 10 "RESERVED" 11 "RESERVED" 12 "RESERVED" 13 "RESERVED" 14 "RESERVED" 15 "RESERVED" 16 "RESERVED" 17 "RESERVED" 18 "RESERVED" 19 "RESERVED" 20 "0x0014~0x4E20:Valid frequency of Hz" 20000 "0x0014~0x4E20:Valid frequency of Hz" 20001 "0x4E21~0xFFFE:RESERVED" 65534 "0x4E21~0xFFFE:RESERVED" 65535 "Invalid" ;
VAL_ 1543 AMP_WalkieTalkieVolumeState 0 "0x0x0~0xFE:WalkieTalkieVolume" 254 "0x0x0~0xFE:WalkieTalkieVolume" 255 "invalid" ;
VAL_ 1543 AMP_WalkieTalkie_OutputCh_State 0 "0x0x0~0xFFFE:OutputChState (Refer the signal description)" 65534 "0x0x0~0xFFFE:OutputChState (Refer the signal description)" 65535 "Invalid" ;
VAL_ 1545 AMP_Beep1VolumeState 0 "0x0x0~0xFD:Beep1 Volume" 253 "0x0x0~0xFD:Beep1 Volume" 254 "Invalid" 255 "Invalid" ;
VAL_ 1545 AMP_Analog_OutputCh_State 65535 "Invalid" ;
VAL_ 1545 AMP_Beep1_OutputCh_State 65535 "Invalid" ;
VAL_ 1545 AMP_Beep1KBDVolumeState 0 "0x0x0~0xFE:Keyboard Beep Volume" 254 "0x0x0~0xFE:Keyboard Beep Volume" 255 "Invalid" ;
VAL_ 1545 AMP_SPDIF_OutputCh_State 65535 "Invalid" ;
VAL_ 1552 AMP_ToneScapeXSetting 0 "0x0x0~0xFE:ToneScapeX" 254 "0x0x0~0xFE:ToneScapeX" 255 "Invalid" ;
VAL_ 1552 AMP_ToneScapeYSetting 0 "0x0x0~0xFE:ToneScapeY" 254 "0x0x0~0xFE:ToneScapeY" 255 "Invalid" ;
VAL_ 1552 AMP_ToneScapeZSetting 0 "0x0x0~0xFE:ToneScapeZ" 254 "0x0x0~0xFE:ToneScapeZ" 255 "Invalid" ;
VAL_ 1552 AMP_SiriModeState 0 "Siri Mode Off" 1 "Siri Mode On" 2 "Reserved" 3 "Invalid" ;
VAL_ 1552 AMP_SiriVolumeState 0 "0x0x0~0xFD:SiriVolume" 253 "0x0x0~0xFD:SiriVolume" 254 "Reserved" 255 "invalid" ;
VAL_ 1553 AMP_Binary1Ver 0 "0x0x00~0xFE:Valid" 254 "0x0x00~0xFE:Valid" 255 "Invalid" ;
VAL_ 1553 AMP_Binary3Ver 0 "0x0x00~0xFE:Valid" 254 "0x0x00~0xFE:Valid" 255 "Invalid" ;
VAL_ 1553 AMP_Binary4Ver 0 "0x0x00~0xFE:Valid" 254 "0x0x00~0xFE:Valid" 255 "Invalid" ;
VAL_ 1553 AMP_Binary5Ver 0 "0x0x00~0xFE:Valid" 254 "0x0x00~0xFE:Valid" 255 "Invalid" ;
VAL_ 1553 AMP_Binary6Ver 0 "0x0x00~0xFE:Valid" 254 "0x0x00~0xFE:Valid" 255 "Invalid" ;
VAL_ 1553 AMP_WalkieTalkieModeState 0 "WalkieTalkie Mode Off" 1 "WalkieTalkie Mode On" 2 "Reserved" 3 "Invalid" ;
VAL_ 1553 AMP_Binary2Ver 0 "0x0x00~0xFE:Valid" 254 "0x0x00~0xFE:Valid" 255 "Invalid" ;
VAL_ 1546 AMP_SupportBeepVolumeControl 0 "Null" 1 "False" 2 "True" 3 "Invalid" ;
VAL_ 1546 AMP_SupportESEVMode 0 "Null" 1 "False" 2 "True" 3 "Invalid" ;
VAL_ 1546 AMP_SupportANCMode 0 "Null" 1 "False" 2 "True" 3 "Invalid" ;
VAL_ 1546 AMP_MakerID 0 "Initial Value" 1 "Mobis" 2 "Beats by Dr.Dre" 3 "Harman_Becker" 4 "BOSE" 5 "Bang&Olufsen" 6 "Meridian" 7 "0x07~0xFF:Invalid" 255 "0x07~0xFF:Invalid" ;
VAL_ 1546 AMP_SupportQLS 0 "Null" 1 "False" 2 "True" 3 "Invalid" ;
VAL_ 1546 AMP_SupportASDMode 0 "Null" 1 "False" 2 "True" 3 "Invalid" ;
VAL_ 1546 AMP_Support_ElecSound 0 "Null" 1 "False" 2 "True" 3 "Invalid" ;
VAL_ 1547 AMP_SupportHDAudio 0 "Null" 1 "False" 2 "True" 3 "Invalid" ;
VAL_ 1547 AMP_SupportVirtualVenue 0 "Null" 1 "False" 2 "True" 3 "Invalid" ;
VAL_ 1547 AMP_SupportQLI 0 "Null" 1 "False" 2 "True" 3 "Invalid" ;
VAL_ 1547 AMP_SupportWrnPromptMode 0 "Null" 1 "False" 2 "True" 3 "Invalid" ;
VAL_ 1547 AMP_SupportKBDBeep 0 "Null" 1 "False" 2 "True" 3 "Invaid" ;
VAL_ 1547 AMP_SupportDriverMode 0 "Null" 1 "False" 2 "True" 3 "Invalid" ;
VAL_ 1547 AMP_Support_SDVC 0 "Null" 1 "False" 2 "True" 3 "Invaid" ;
VAL_ 1547 AMP_Support_CLU_InfoVolume10 0 "Null" 1 "False" 2 "True" 3 "Invalid" ;
VAL_ 1547 AMP_Support_ADASVolume10 0 "Null" 1 "False" 2 "True" 3 "Invalid" ;
VAL_ 1547 AMP_Support_BeepVolume10 0 "Null" 1 "False" 2 "True" 3 "Invalid" ;
VAL_ 1547 AMP_Support_AlarmVolume10 0 "Null" 1 "False" 2 "True" 3 "Invalid" ;
VAL_ 1547 AMP_Support_Volume35 0 "Null" 1 "False" 2 "True" 3 "Invalid" ;
VAL_ 1547 AMP_SupportRANC 0 "Null" 1 "False" 2 "True" 3 "Invaid" ;
VAL_ 591 ATS_RLStSldFwdBtn 0 "Default" 1 "Off" 2 "On" 3 "Reserved" ;
VAL_ 591 ATS_RLStSldBwdBtn 0 "Default" 1 "Off" 2 "On" 3 "Reserved" ;
VAL_ 591 ATS_RLStRclFwdBtn 0 "Default" 1 "Off" 2 "On" 3 "Reserved" ;
VAL_ 591 ATS_RLStRclBwdBtn 0 "Default" 1 "Off" 2 "On" 3 "Reserved" ;
VAL_ 591 ATS_RLStTltUpBtn 0 "Default" 1 "Off" 2 "On" 3 "Reserved" ;
VAL_ 591 ATS_RLStTltDnBtn 0 "Default" 1 "Off" 2 "On" 3 "Reserved" ;
VAL_ 591 ATS_RLStHRestUpBtn 0 "Default" 1 "Off" 2 "On" 3 "Reserved" ;
VAL_ 591 ATS_RLStHRestDnBtn 0 "Default" 1 "Off" 2 "On" 3 "Reserved" ;
VAL_ 591 ATS_RLStHRestFwdBtn 0 "Default" 1 "Off" 2 "On" 3 "Reserved" ;
VAL_ 591 ATS_RLStHRestBwdBtn 0 "Default" 1 "Off" 2 "On" 3 "Reserved" ;
VAL_ 591 ATS_RLStLegRestUpBtn 0 "Default" 1 "Off" 2 "On" 3 "Reserved" ;
VAL_ 591 ATS_RLStLegRestDnBtn 0 "Default" 1 "Off" 2 "On" 3 "Reserved" ;
VAL_ 591 ATS_RLStLegRestExtUpBtn 0 "Default" 1 "Off" 2 "On" 3 "Reserved" ;
VAL_ 591 ATS_RLStLegRestExtDnBtn 0 "Default" 1 "Off" 2 "On" 3 "Reserved" ;
VAL_ 591 ATS_RLStShoulderADJFwdBtn 0 "Default" 1 "Off" 2 "On" 3 "Reserved" ;
VAL_ 591 ATS_RLStShoulderADJBwdBtn 0 "Default" 1 "Off" 2 "On" 3 "Reserved" ;
VAL_ 607 ATS_RRStSldFwdBtn 0 "Default" 1 "Off" 2 "On" 3 "Reserved" ;
VAL_ 607 ATS_RRStSldBwdBtn 0 "Default" 1 "Off" 2 "On" 3 "Reserved" ;
VAL_ 607 ATS_RRStRclFwdBtn 0 "Default" 1 "Off" 2 "On" 3 "Reserved" ;
VAL_ 607 ATS_RRStRclBwdBtn 0 "Default" 1 "Off" 2 "On" 3 "Reserved" ;
VAL_ 607 ATS_RRStTltUpBtn 0 "Default" 1 "Off" 2 "On" 3 "Reserved" ;
VAL_ 607 ATS_RRStTltDnBtn 0 "Default" 1 "Off" 2 "On" 3 "Reserved" ;
VAL_ 607 ATS_RRStHRestUpBtn 0 "Default" 1 "Off" 2 "On" 3 "Reserved" ;
VAL_ 607 ATS_RRStHRestDnBtn 0 "Default" 1 "Off" 2 "On" 3 "Reserved" ;
VAL_ 607 ATS_RRStHRestFwdBtn 0 "Default" 1 "Off" 2 "On" 3 "Reserved" ;
VAL_ 607 ATS_RRStHRestBwdBtn 0 "Default" 1 "Off" 2 "On" 3 "Reserved" ;
VAL_ 607 ATS_RRStShoulderADJFwdBtn 0 "Default" 1 "Off" 2 "On" 3 "Reserved" ;
VAL_ 607 ATS_RRStShoulderADJBwdBtn 0 "Default" 1 "Off" 2 "On" 3 "Reserved" ;
VAL_ 607 ATS_RRStLegRestUpBtn 0 "Default" 1 "Off" 2 "On" 3 "Reserved" ;
VAL_ 607 ATS_RRStLegRestDnBtn 0 "Default" 1 "Off" 2 "On" 3 "Reserved" ;
VAL_ 607 ATS_RRStLegRestExtUpBtn 0 "Default" 1 "Off" 2 "On" 3 "Reserved" ;
VAL_ 607 ATS_RRStLegRestExtDnBtn 0 "Default" 1 "Off" 2 "On" 3 "Reserved" ;
VAL_ 1058 Wiper_PrkngPosSta 0 "else" 1 "Parking Position" 2 "Not Used" 3 "Error Indicator" ;
VAL_ 1058 Wiper_RainSnsrOptionTyp 0 "Non Rain Sensor Option" 1 "Rain Sensor Option" 2 "Not Used" 3 "Error Indicator" ;
VAL_ 1058 Wiper_RainSnsrSta 0 "OFF" 1 "Rain Detected" 2 "Low" 3 "High" 4 "Fault 1" 5 "Reserved" 6 "Reserved" 7 "Reserved" 8 "Reserved" 9 "Reserved" 10 "Reserved" 11 "Reserved" 12 "Reserved" 13 "Reserved" 14 "Not Used" 15 "Error Indicator" ;
VAL_ 1058 BCM_GearPosPSta 0 "Off" 1 "P" 2 "Not Used" 3 "Error Indicator" ;
VAL_ 1058 BCM_SunRoofOpnSta 0 "Close" 1 "Open" 2 "Not Used" 3 "Error Indicator" ;
VAL_ 1058 SunRoof_RrBlindErrSta 0 "No error" 1 "Thermal Protection Active" 2 "Initialized Status" 3 "Undefined ECU Error" 4 "Switch Error" 5 "Voltage error" 6 "Complex Error" 7 "Invalid" ;
VAL_ 2563128065 AMP_EngOrderC2GainSet 0 "Min Value" 1 "Values" 2 "Values" 3 "Values" 4 "Values" 5 "Values" 6 "Values" 7 "Values" 8 "Values" 9 "Values" 10 "Max Value" 11 "0xB~0xFE:Reserved" 254 "0xB~0xFE:Reserved" 255 "Invalid" ;
VAL_ 2563128065 AMP_EngOrderC6GainSet 0 "Min Value" 1 "Values" 2 "Values" 3 "Values" 4 "Values" 5 "Values" 6 "Values" 7 "Values" 8 "Values" 9 "Values" 10 "Max Value" 11 "0xB~0xFE:Reserved" 254 "0xB~0xFE:Reserved" 255 "Invalid" ;
VAL_ 2563128065 AMP_CLU_InfoVolumeStep 0 "0x0x0~0xFE:cluster inform sound volume" 254 "0x0x0~0xFE:cluster inform sound volume" 255 "Invalid" ;
VAL_ 2563128065 AMP_CLUinfo_OutputCh_Select 65535 "Invaild" ;
VAL_ 2563128065 AMP_ADASVolMasterGain 0 "0x0x0~0xFE:Volume setting value" 254 "0x0x0~0xFE:Volume setting value" 255 "Invalid" ;
VAL_ 2563128065 AMP_EngOrderC4GainSet 0 "Min Value" 1 "Values" 2 "Values" 3 "Values" 4 "Values" 5 "Values" 6 "Values" 7 "Values" 8 "Values" 9 "Values" 10 "Values" 11 "Values" 12 "Values" 13 "Values" 14 "Values" 15 "Values" 16 "Values" 17 "Values" 18 "Values" 19 "Values" 20 "Values" 21 "Values" 22 "Values" 23 "Values" 24 "Max Value" 25 "0x19~0xFE:Reserved" 254 "0x19~0xFE:Reserved" 255 "Invalid" ;
VAL_ 118 ICC_CamBlckdStat 0 "Unknown" 1 "Blockage" 2 "No Blockage" 3 "Invalid" ;
VAL_ 118 ICC_WarningStat 0 "No Warning" 1 "Distraction Warning" 2 "Drowsiness Warning" 3 "Handle Tilt Up" 4 "Handle Tilt Down" 5 "Reserved" 6 "Blockage Warning" 7 "Failure Warning" ;
VAL_ 118 ICC_CamFailStat 0 "No Failure" 1 "Camera Failure" 2 "IR-LED Failure" 3 "Invalid" ;
VAL_ 118 ICC_EcuFailStat 0 "No Failure" 1 "ECU Failure" 2 "Reserved" 3 "Invalid" ;
VAL_ 118 ICC_OptUsmStat 0 "Unknown" 1 "Off" 2 "On" 3 "Invalid" ;
VAL_ 118 ICC_MajorSWVer 0 "0x0x0~0xFF:" 255 "0x0x0~0xFF:" ;
VAL_ 118 ICC_MinorSWVer 0 "0x0x0~0xFF:" 255 "0x0x0~0xFF:" ;
VAL_ 118 ICC_SymStat 0 "Unknown" 1 "Init" 2 "Failure" 3 "Off" 4 "Ready" 5 "Active" 6 "Reserved" 7 "Invalid" ;
VAL_ 119 ICC_EyePosXVal 0 "Value" 1 "Value" 2 "Value" 3 "Value" 4 "Value" 5 "Value" 6 "Value" 7 "Value" 8 "Value" 9 "Value" 10 "Value" 11 "Value" 12 "Value" 13 "Value" 14 "Value" 15 "Value" 16 "Value" 17 "Value" 18 "Value" 19 "Value" 20 "Value" 21 "Value" 22 "Value" 23 "Value" 24 "Value" 25 "Value" 26 "Value" 27 "Value" 28 "Value" 29 "Value" 30 "Value" 31 "Value" 32 "Value" 33 "Value" 34 "Value" 35 "Value" 36 "Value" 37 "Value" 38 "Value" 39 "Value" 40 "Value" 41 "Value" 42 "Value" 43 "Value" 44 "Value" 45 "Value" 46 "Value" 47 "Value" 48 "Value" 49 "Value" 50 "Value" 51 "Value" 52 "Value" 53 "Value" 54 "Value" 55 "Value" 56 "Value" 57 "Value" 58 "Value" 59 "Value" 60 "Value" 63 "Invalid" ;
VAL_ 119 ICC_EyePosYVal 0 "Value" 1 "Value" 2 "Value" 3 "Value" 4 "Value" 5 "Value" 6 "Value" 7 "Value" 8 "Value" 9 "Value" 10 "Value" 11 "Value" 12 "Value" 13 "Value" 14 "Value" 15 "Value" 16 "Value" 17 "Value" 18 "Value" 19 "Value" 20 "Value" 21 "Value" 22 "Value" 23 "Value" 24 "Value" 25 "Value" 26 "Value" 27 "Value" 28 "Value" 29 "Value" 30 "Value" 31 "Value" 32 "Value" 33 "Value" 34 "Value" 35 "Value" 36 "Value" 37 "Value" 38 "Value" 39 "Value" 40 "Value" 41 "Value" 42 "Value" 43 "Value" 44 "Value" 45 "Value" 46 "Value" 47 "Value" 48 "Value" 49 "Value" 50 "Value" 51 "Value" 52 "Value" 53 "Value" 54 "Value" 55 "Value" 56 "Value" 57 "Value" 58 "Value" 59 "Value" 60 "Value" 63 "Invalid" ;
VAL_ 119 ICC_EyePosZVal 0 "Value" 1 "Value" 2 "Value" 3 "Value" 4 "Value" 5 "Value" 6 "Value" 7 "Value" 8 "Value" 9 "Value" 10 "Value" 11 "Value" 12 "Value" 13 "Value" 14 "Value" 15 "Value" 16 "Value" 17 "Value" 18 "Value" 19 "Value" 20 "Value" 21 "Value" 22 "Value" 23 "Value" 24 "Value" 25 "Value" 26 "Value" 27 "Value" 28 "Value" 29 "Value" 30 "Value" 31 "Value" 32 "Value" 33 "Value" 34 "Value" 35 "Value" 36 "Value" 37 "Value" 38 "Value" 39 "Value" 40 "Value" 41 "Value" 42 "Value" 43 "Value" 44 "Value" 45 "Value" 46 "Value" 47 "Value" 48 "Value" 49 "Value" 50 "Value" 51 "Value" 52 "Value" 53 "Value" 54 "Value" 55 "Value" 56 "Value" 57 "Value" 58 "Value" 59 "Value" 60 "Value" 63 "Invalid" ;
VAL_ 119 ICC_EyeGazeYawVal 0 "Value" 1 "Value" 2 "Value" 3 "Value" 4 "Value" 5 "Value" 6 "Value" 7 "Value" 8 "Value" 9 "Value" 10 "Value" 11 "Value" 12 "Value" 13 "Value" 14 "Value" 15 "Value" 16 "Value" 17 "Value" 18 "Value" 19 "Value" 20 "Value" 21 "Value" 22 "Value" 23 "Value" 24 "Value" 25 "Value" 26 "Value" 27 "Value" 28 "Value" 29 "Value" 30 "Value" 31 "Value" 32 "Value" 33 "Value" 34 "Value" 35 "Value" 36 "Value" 37 "Value" 38 "Value" 39 "Value" 40 "Value" 41 "Value" 42 "Value" 43 "Value" 44 "Value" 45 "Value" 46 "Value" 47 "Value" 48 "Value" 49 "Value" 50 "Value" 51 "Value" 52 "Value" 53 "Value" 54 "Value" 55 "Value" 56 "Value" 57 "Value" 58 "Value" 59 "Value" 60 "Value" 63 "Invalid" ;
VAL_ 119 ICC_EyeGazePitchVal 0 "Value" 1 "Value" 2 "Value" 3 "Value" 4 "Value" 5 "Value" 6 "Value" 7 "Value" 8 "Value" 9 "Value" 10 "Value" 11 "Value" 12 "Value" 13 "Value" 14 "Value" 15 "Value" 16 "Value" 17 "Value" 18 "Value" 19 "Value" 20 "Value" 21 "Value" 22 "Value" 23 "Value" 24 "Value" 25 "Value" 26 "Value" 27 "Value" 28 "Value" 29 "Value" 30 "Value" 31 "Value" 32 "Value" 33 "Value" 34 "Value" 35 "Value" 36 "Value" 37 "Value" 38 "Value" 39 "Value" 40 "Value" 41 "Value" 42 "Value" 43 "Value" 44 "Value" 45 "Value" 46 "Value" 47 "Value" 48 "Value" 49 "Value" 50 "Value" 51 "Value" 52 "Value" 53 "Value" 54 "Value" 55 "Value" 56 "Value" 57 "Value" 58 "Value" 59 "Value" 60 "Value" 63 "Invalid" ;
VAL_ 120 ICC_HeadPoseYawVal 0 "Value" 1 "Value" 2 "Value" 3 "Value" 4 "Value" 5 "Value" 6 "Value" 7 "Value" 8 "Value" 9 "Value" 10 "Value" 11 "Value" 12 "Value" 13 "Value" 14 "Value" 15 "Value" 16 "Value" 17 "Value" 18 "Value" 19 "Value" 20 "Value" 21 "Value" 22 "Value" 23 "Value" 24 "Value" 25 "Value" 26 "Value" 27 "Value" 28 "Value" 29 "Value" 30 "Value" 31 "Value" 32 "Value" 33 "Value" 34 "Value" 35 "Value" 36 "Value" 37 "Value" 38 "Value" 39 "Value" 40 "Value" 41 "Value" 42 "Value" 43 "Value" 44 "Value" 45 "Value" 46 "Value" 47 "Value" 48 "Value" 49 "Value" 50 "Value" 51 "Value" 52 "Value" 53 "Value" 54 "Value" 55 "Value" 56 "Value" 57 "Value" 58 "Value" 59 "Value" 60 "Value" 63 "Invalid" ;
VAL_ 120 ICC_HeadPosePitchVal 0 "Value" 1 "Value" 2 "Value" 3 "Value" 4 "Value" 5 "Value" 6 "Value" 7 "Value" 8 "Value" 9 "Value" 10 "Value" 11 "Value" 12 "Value" 13 "Value" 14 "Value" 15 "Value" 16 "Value" 17 "Value" 18 "Value" 19 "Value" 20 "Value" 21 "Value" 22 "Value" 23 "Value" 24 "Value" 25 "Value" 26 "Value" 27 "Value" 28 "Value" 29 "Value" 30 "Value" 31 "Value" 32 "Value" 33 "Value" 34 "Value" 35 "Value" 36 "Value" 37 "Value" 38 "Value" 39 "Value" 40 "Value" 41 "Value" 42 "Value" 43 "Value" 44 "Value" 45 "Value" 46 "Value" 47 "Value" 48 "Value" 49 "Value" 50 "Value" 51 "Value" 52 "Value" 53 "Value" 54 "Value" 55 "Value" 56 "Value" 57 "Value" 58 "Value" 59 "Value" 60 "Value" 63 "Invalid" ;
VAL_ 120 ICC_HeadPoseRollVal 0 "Value" 1 "Value" 2 "Value" 3 "Value" 4 "Value" 5 "Value" 6 "Value" 7 "Value" 8 "Value" 9 "Value" 10 "Value" 11 "Value" 12 "Value" 13 "Value" 14 "Value" 15 "Value" 16 "Value" 17 "Value" 18 "Value" 19 "Value" 20 "Value" 21 "Value" 22 "Value" 23 "Value" 24 "Value" 25 "Value" 26 "Value" 27 "Value" 28 "Value" 29 "Value" 30 "Value" 31 "Value" 32 "Value" 33 "Value" 34 "Value" 35 "Value" 36 "Value" 37 "Value" 38 "Value" 39 "Value" 40 "Value" 41 "Value" 42 "Value" 43 "Value" 44 "Value" 45 "Value" 46 "Value" 47 "Value" 48 "Value" 49 "Value" 50 "Value" 51 "Value" 52 "Value" 53 "Value" 54 "Value" 55 "Value" 56 "Value" 57 "Value" 58 "Value" 59 "Value" 60 "Value" 63 "Invalid" ;
VAL_ 120 ICC_EyeOpenVal 0 "Value" 1 "Value" 2 "Value" 3 "Value" 4 "Value" 5 "Value" 6 "Value" 7 "Value" 8 "Value" 9 "Value" 10 "Value" 11 "Value" 12 "Value" 13 "Value" 14 "Value" 15 "Value" 16 "Value" 17 "Value" 18 "Value" 19 "Value" 20 "Value" 21 "Value" 22 "Value" 23 "Value" 24 "Value" 25 "Value" 26 "Value" 27 "Value" 28 "Value" 29 "Value" 30 "Value" 31 "Value" 32 "Value" 33 "Value" 34 "Value" 35 "Value" 36 "Value" 37 "Value" 38 "Value" 39 "Value" 40 "Value" 41 "Value" 42 "Value" 43 "Value" 44 "Value" 45 "Value" 46 "Value" 47 "Value" 48 "Value" 49 "Value" 50 "Value" 63 "Invalid" ;
VAL_ 120 ICC_LeftEyeOpenVal 0 "Value" 1 "Value" 2 "Value" 3 "Value" 4 "Value" 5 "Value" 6 "Value" 7 "Value" 8 "Value" 9 "Value" 10 "Value" 11 "Value" 12 "Value" 13 "Value" 14 "Value" 15 "Value" 16 "Value" 17 "Value" 18 "Value" 19 "Value" 20 "Value" 21 "Value" 22 "Value" 23 "Value" 24 "Value" 25 "Value" 26 "Value" 27 "Value" 28 "Value" 29 "Value" 30 "Value" 31 "Value" 32 "Value" 33 "Value" 34 "Value" 35 "Value" 36 "Value" 37 "Value" 38 "Value" 39 "Value" 40 "Value" 41 "Value" 42 "Value" 43 "Value" 44 "Value" 45 "Value" 46 "Value" 47 "Value" 48 "Value" 49 "Value" 50 "Value" 63 "Invalid" ;
VAL_ 120 ICC_RightEyeOpenVal 0 "Value" 1 "Value" 2 "Value" 3 "Value" 4 "Value" 5 "Value" 6 "Value" 7 "Value" 8 "Value" 9 "Value" 10 "Value" 11 "Value" 12 "Value" 13 "Value" 14 "Value" 15 "Value" 16 "Value" 17 "Value" 18 "Value" 19 "Value" 20 "Value" 21 "Value" 22 "Value" 23 "Value" 24 "Value" 25 "Value" 26 "Value" 27 "Value" 28 "Value" 29 "Value" 30 "Value" 31 "Value" 32 "Value" 33 "Value" 34 "Value" 35 "Value" 36 "Value" 37 "Value" 38 "Value" 39 "Value" 40 "Value" 41 "Value" 42 "Value" 43 "Value" 44 "Value" 45 "Value" 46 "Value" 47 "Value" 48 "Value" 49 "Value" 50 "Value" 63 "Invalid" ;
VAL_ 120 ICC_EyeBlinkOccurrence 0 "Unknown" 1 "Yes" 2 "No" 3 "Invalid" ;
VAL_ 121 ICC_EyeStat 0 "Opened" 1 "Closed" 2 "Reserved" 3 "Invalid" ;
VAL_ 121 ICC_LeftEyeOpenStat 0 "Opened" 1 "Closed" 2 "Reserved" 3 "Invalid" ;
VAL_ 121 ICC_RightEyeOpenStat 0 "Opened" 1 "Closed" 2 "Reserved" 3 "Invalid" ;
VAL_ 121 ICC_DistLvlStat 0 "Level0" 1 "Level1" 2 "Level2" 3 "Level3" 4 "Level4" 5 "Level5" 6 "Reserved" 7 "Invalid" ;
VAL_ 121 ICC_DrwsLvlStat 0 "Level0" 1 "Level1" 2 "Level2" 3 "Level3" 4 "Level4" 5 "Level5" 6 "Reserved" 7 "Invalid" ;
VAL_ 121 ICC_FaceDetectStat 0 "Unknown" 1 "Not detected" 2 "Detected" 3 "Invalid" ;
VAL_ 121 ICC_FaceFakeStat 0 "Unknown" 1 "Real Face" 2 "Fake Face" 3 "Invalid" ;
VAL_ 121 ICC_AoIStat 0 "Unknown" 1 "On the Road" 2 "Left side Mirror" 3 "Right side Mirror" 4 "Cluster" 5 "Avnt" 6 "Room Mirror" 7 "Invalid" ;
VAL_ 1086 RL_CURTAIN_POSITION 0 "Bottom" 1 "Middle" 2 "Top" 3 "Unknown(Curtain not Initialized)" ;
VAL_ 1086 RDC_SWVerMinor1 0 "0x0x0~0x7F:ASCII Code Value (HEX)" 127 "0x0x0~0x7F:ASCII Code Value (HEX)" ;
VAL_ 1086 RDC_SWVerMinor2 0 "0x0x0~0x7F:ASCII Code Value (HEX)" 127 "0x0x0~0x7F:ASCII Code Value (HEX)" ;
VAL_ 1086 RR_CURTAIN_POSITION 0 "Bottom" 1 "Middle" 2 "Top" 3 "Unknown(Curtain not Initialized)" ;
VAL_ 1086 RDC_RrLftDoorCurtainActSta 0 "No Action" 1 "Opening" 2 "Closing" 3 "Invalid" ;
VAL_ 1086 RDC_RrRtDoorCurtainActSta 0 "No Action" 1 "Opening" 2 "Closing" 3 "Invalid" ;
VAL_ 1086 RDC_VitalityCurtainSta 0 "Default" 1 "Off" 2 "On" 3 "Invalid" ;
VAL_ 1086 RDC_DelightCurtainSta 0 "Default" 1 "Off" 2 "On" 3 "Invalid" ;
VAL_ 1086 RDC_OptTyp 0 "Default" 1 "RDC Option" 2 "Not Used" 3 "Error Indicator" ;
VAL_ 1086 RDC_CareCurtainSta 0 "Default" 1 "Off" 2 "On" 3 "Invalid" ;
VAL_ 1086 RDC_ComfortCurtainSta 0 "Default" 1 "Off" 2 "On" 3 "Invalid" ;
VAL_ 1086 RDC_SWVerMajor1 0 "0x0x0~0x7F:ASCII Code Value (HEX)" 127 "0x0x0~0x7F:ASCII Code Value (HEX)" ;
VAL_ 1080 RL_SHVU_SeatOptSta 0 "Init" 1 "Heater only 2step" 2 "Heater only 3step" 3 "Vent only 2step" 4 "Vent only 3step" 5 "Heater and Vent 2step" 6 "Heater and Vent 3step" 7 "Invalid" ;
VAL_ 1080 RL_SHVU_HtAutoDownRVal 0 "Init" 1 "Disable" 2 "Enable" 3 "Invalid" ;
VAL_ 1080 RL_SHVU_VntTurboSta 0 "Off(Initial Value)" 1 "Turbo Mode" 2 "Not Used" 3 "Error Indicator" ;
VAL_ 1080 RL_SHVU_SeatOptSta_RHD 0 "Init" 1 "Heater only 2step" 2 "Heater only 3step" 3 "Vent only 2step" 4 "Vent only 3step" 5 "Heater and Vent 2step" 6 "Heater and Vent 3step" 7 "Invalid" ;
VAL_ 1080 RL_SHVU_SeatHtOperSta_RHD 0 "Init" 1 "Unused" 2 "Heater & Vent OFF" 3 "Vent Low" 4 "Vent Mid" 5 "Vent High" 6 "Heater Low" 7 "Heater Mid" 8 "Heater High" 9 "Unused" 10 "Unused" 11 "Unused" 12 "Unused" 13 "Unused" 14 "Unused" 15 "Invalid" ;
VAL_ 1080 RL_SHVU_SeatHtOperSta 0 "Init" 1 "Unused" 2 "Heater & Vent OFF" 3 "Vent Low" 4 "Vent Mid" 5 "Vent High" 6 "Heater Low" 7 "Heater Mid" 8 "Heater High" 9 "Unused" 10 "Unused" 11 "Unused" 12 "Unused" 13 "Unused" 14 "Unused" 15 "Invalid" ;
VAL_ 1080 RL_SHVU_HtSwHiIndSta_RHD 0 "OFF" 1 "ON" 2 "Not used" 3 "Error Indicator" ;
VAL_ 1080 RL_SHVU_HtSwMidIndSta_RHD 0 "OFF" 1 "ON" 2 "Not used" 3 "Error Indicator" ;
VAL_ 1080 RL_SHVU_HtSwLowIndSta_RHD 0 "OFF" 1 "ON" 2 "Not used" 3 "Error Indicator" ;
VAL_ 1080 RL_SHVU_VntSwHiIndSta_RHD 0 "OFF" 1 "ON" 2 "Not used" 3 "Error Indicator" ;
VAL_ 1080 RL_SHVU_VntSwMidIndSta_RHD 0 "OFF" 1 "ON" 2 "Not used" 3 "Error Indicator" ;
VAL_ 1080 RL_SHVU_VntSwLowIndSta_RHD 0 "OFF" 1 "ON" 2 "Not used" 3 "Error Indicator" ;
VAL_ 1080 RL_SHVU_SeatHtFail 0 "No Fail(Initial Value)" 1 "Fail" 2 "Not Used" 3 "Error Indicator" ;
VAL_ 1070 RL_SHVU_HtSwHiIndSta 0 "OFF" 1 "ON" 2 "Not used" 3 "Error Indicator" ;
VAL_ 1070 RL_SHVU_HtSwMidIndSta 0 "OFF" 1 "ON" 2 "Not used" 3 "Error Indicator" ;
VAL_ 1070 RL_SHVU_HtSwLowIndSta 0 "OFF" 1 "ON" 2 "Not used" 3 "Error Indicator" ;
VAL_ 1070 RL_SHVU_VntSwHiIndSta 0 "OFF" 1 "ON" 2 "Not used" 3 "Error Indicator" ;
VAL_ 1070 RL_SHVU_VntSwMidIndSta 0 "OFF" 1 "ON" 2 "Not used" 3 "Error Indicator" ;
VAL_ 1070 RL_SHVU_VntSwLowIndSta 0 "OFF" 1 "ON" 2 "Not used" 3 "Error Indicator" ;
VAL_ 1070 RL_SHVU_HtBlcUsmSta 0 "Default" 1 "Normal" 2 "Back 1" 3 "Back 2" 4 "Back 3" 5 "Cush 1" 6 "Cush 2" 7 "Cush 3" 8 "Reserved" 9 "Reserved" 10 "Reserved" 11 "Reserved" 12 "Reserved" 13 "Reserved" 14 "Reserved" 15 "Invalid" ;
VAL_ 599 RRPSM_AvWtcMemReq 0 "Default" 1 "Save" 2 "Reset" 3 "Invalid" ;
VAL_ 599 RRPSM_RearModeWngDisforATS 0 "Default" 1 "Relax/Return Mode(Rear Only)" 2 "Inhibit LegRest" 3 "Monitor Mode-Fail(Ast Seated)" 4 "AST seated && FootRest Open" 5 "Inhibit Rear IMS" 6 "Inhibit One Touch MODE" 7 "Invaild" ;
VAL_ 599 RRPSM_ReadingMemReq 0 "Default" 1 "Save" 2 "Reset" 3 "Invalid" ;
VAL_ 599 RRPSM_RestMemReq 0 "Default" 1 "Save" 2 "Reset" 3 "Invalid" ;
VAL_ 599 RRPSM_ReturnMemReq 0 "Default" 1 "Save" 2 "Reset" 3 "Invalid" ;
VAL_ 599 RRPSM_RearModeWngDis 0 "Default" 1 "Relax Mode(Rear Only)" 2 "Return Mode(Rear Only)" 3 "One Touch  Mode-Fail (Ast Seated)" 4 "Mode-Fail (Not Initialized)" 5 "Inhibit Rear IMS" 6 "AST seated && FootRest Open" 7 "Invaild" ;
VAL_ 127 RRPSS_L_StSldFwdMvBtn 0 "Default" 1 "Off" 2 "On" 3 "Invalid" ;
VAL_ 127 RRPSS_L_StSldBwdMvBtn 0 "Default" 1 "Off" 2 "On" 3 "Invalid" ;
VAL_ 127 RRPSS_L_StRclFwdMvBtn 0 "Default" 1 "Off" 2 "On" 3 "Invalid" ;
VAL_ 127 RRPSS_L_StRclBwdMvBtn 0 "Default" 1 "Off" 2 "On" 3 "Invalid" ;
VAL_ 127 RRPSS_L_StTltUpMvBtn 0 "Default" 1 "Off" 2 "On" 3 "Invalid" ;
VAL_ 127 RRPSS_L_StTltDnMvBtn 0 "Default" 1 "Off" 2 "On" 3 "Invalid" ;
VAL_ 127 RRPSS_L_StHRestUpMvBtn 0 "Default" 1 "Off" 2 "On" 3 "Invalid" ;
VAL_ 127 RRPSS_L_StHRestDnMvBtn 0 "Default" 1 "Off" 2 "On" 3 "Invalid" ;
VAL_ 127 RRPSS_L_StHRestFwdMvBtn 0 "Default" 1 "Off" 2 "On" 3 "Invalid" ;
VAL_ 127 RRPSS_L_StHRestBwdMvBtn 0 "Default" 1 "Off" 2 "On" 3 "Invalid" ;
VAL_ 127 RRPSS_L_StLegRestUpBtn 0 "Default" 1 "Off" 2 "On" 3 "Invalid" ;
VAL_ 127 RRPSS_L_StLegRestDnBtn 0 "Default" 1 "Off" 2 "On" 3 "Invalid" ;
VAL_ 127 RRPSS_L_StLegRestExtUpBtn 0 "Default" 1 "Off" 2 "On" 3 "Invalid" ;
VAL_ 127 RRPSS_L_StLegRestExtDnBtn 0 "Default" 1 "Off" 2 "On" 3 "Invalid" ;
VAL_ 1071 RR_SHVU_HtSwHiIndSta 0 "OFF" 1 "ON" 2 "Not used" 3 "Error indicator" ;
VAL_ 1071 RR_SHVU_HtSwMidIndSta 0 "OFF" 1 "ON" 2 "Not used" 3 "Error Indicator" ;
VAL_ 1071 RR_SHVU_HtSwLowIndSta 0 "OFF" 1 "ON" 2 "Not used" 3 "Error Indicator" ;
VAL_ 1071 RR_SHVU_VntSwHiIndSta 0 "OFF" 1 "ON" 2 "Not used" 3 "Error Indictor" ;
VAL_ 1071 RR_SHVU_VntSwMidIndSta 0 "OFF" 1 "ON" 2 "Not used" 3 "Error Indicator" ;
VAL_ 1071 RR_SHVU_VntSwLowIndSta 0 "OFF" 1 "ON" 2 "Not used" 3 "Error Indicator" ;
VAL_ 1071 RR_SHVU_HtBlcUsmSta 0 "Default" 1 "Normal" 2 "Back 1" 3 "Back 2" 4 "Back 3" 5 "Cush 1" 6 "Cush 2" 7 "Cush 3" 8 "Reserved" 9 "Reserved" 10 "Reserved" 11 "Reserved" 12 "Reserved" 13 "Reserved" 14 "Reserved" 15 "Invalid" ;
VAL_ 1073 USM_ValCmdSta 0 "Default" 1 "Off(Disable)" 2 "On(Enable)" 3 "Invalid" ;
VAL_ 1073 RWPC_SWVerMinor1 0 "0x0x0~0x7F:ASCII Code Value (HEX)" 127 "0x0x0~0x7F:ASCII Code Value (HEX)" ;
VAL_ 1073 WPC_PhnLftWrngRWPCSta 0 "Off" 1 "Cellphone on the pad" 2 "Charging" 3 "Charging complete" 4 "Cellphone reminder" 5 "Error" 6 "Reserved" 7 "Invalid" ;
VAL_ 1073 RWPC_SWVerMinor2 0 "0x0x0~0x7F:ASCII Code Value (HEX)" 127 "0x0x0~0x7F:ASCII Code Value (HEX)" ;
VAL_ 1073 USM_ValCmdStaforATS 0 "Default" 1 "Off(Disable)" 2 "On(Enable)" 3 "Invalid" ;
VAL_ 1073 RWPC_SWVerMajor1 0 "0x0x0~0x7F:ASCII Code Value (HEX)" 127 "0x0x0~0x7F:ASCII Code Value (HEX)" ;
